VERSION ""

NS_ :

BS_:

BU_: ICC DVR EPC BBCM EAMP CMSM SBOX FLZCU_HCU_IC FLZCU_IC HCU_IC FLZCU_Signal_IC CGW TBOX BNCM CWC FRZCU

BO_ 1079 BSCU_1: 8 CGW
 SG_ BSCU_1_MotorLockSts : 17|2@0+ (1,0) [0|3] ""  ICC

BO_ 1127 CDU_DCDC_1: 24 CGW
 SG_ DCDC_FaultLevelSts : 107|3@0+ (1,0) [0|7] ""  ICC

BO_ 1035 VCC_1: 8 FLZCU_Signal_IC
 SG_ VCC_1_OTASts : 17|2@0+ (1,0) [0|3] ""  ICC

BO_ 1345 DVR_1: 16 DVR
 SG_ DVR_1_Sdcard_Sts : 26|3@0+ (1,0) [0|7] ""  ICC
 SG_ DVR_1_DVRFailReasons : 20|3@0+ (1,0) [0|7] ""  ICC
 SG_ DVR_1_RecordSts : 22|2@0+ (1,0) [0|3] ""  ICC

BO_ 1121 EAMP_1: 8 EAMP
 SG_ STAT_AMPNaviVolume : 3|4@0+ (1,0) [0|15] ""  ICC
 SG_ STAT_AMPVRVolume : 7|4@0+ (1,0) [0|15] ""  ICC
 SG_ STAT_AMPKeyTone : 9|2@0+ (1,0) [0|3] ""  ICC
 SG_ STAT_AMPMediaVolume : 15|6@0+ (1,0) [0|63] ""  ICC
 SG_ STAT_AMPPhoneVolume : 20|5@0+ (1,0) [0|31] ""  ICC
 SG_ STAT_AMPSoundFocus : 23|3@0+ (1,0) [0|7] ""  ICC
 SG_ STAT_AMPSoundEffect : 27|4@0+ (1,0) [0|15] ""  ICC
 SG_ STAT_AMPSoundEffectBass : 31|4@0+ (1,0) [0|15] ""  ICC
 SG_ STAT_AMPSoundEffectMidrange : 35|4@0+ (1,0) [0|15] ""  ICC
 SG_ STAT_AMPSoundEffectTreble : 39|4@0+ (1,0) [0|15] ""  ICC
 SG_ STAT_AMPSoundFieldBalance : 43|4@0+ (1,0) [0|15] ""  ICC
 SG_ STAT_AMPSoundFieldFader : 47|4@0+ (1,0) [0|15] ""  ICC
 SG_ STAT_REQ_AMPA2BMediaSound : 49|2@0+ (1,0) [0|3] ""  ICC
 SG_ STAT_REQ_AMPA2BNaviSound : 51|2@0+ (1,0) [0|3] ""  ICC
 SG_ STAT_REQ_AMPA2BVRSound : 53|2@0+ (1,0) [0|3] ""  ICC
 SG_ STAT_REQ_AMPA2BTTSSound : 55|2@0+ (1,0) [0|3] ""  ICC
 SG_ STAT_REQ_AMPA2BPhoneSound : 57|2@0+ (1,0) [0|3] ""  ICC
 SG_ STAT_REQ_AMPAlarm : 63|6@0+ (1,0) [0|63] ""  ICC

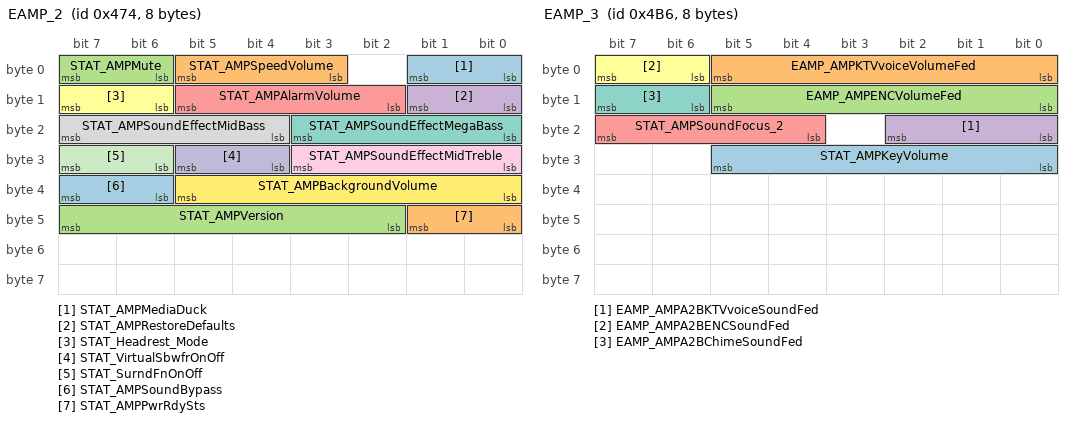
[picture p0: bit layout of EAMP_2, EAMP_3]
BO_ 1140 EAMP_2: 8 EAMP
 SG_ STAT_AMPMediaDuck : 1|2@0+ (1,0) [0|3] ""  ICC
 SG_ STAT_AMPSpeedVolume : 5|3@0+ (1,0) [0|7] ""  ICC
 SG_ STAT_AMPMute : 7|2@0+ (1,0) [0|3] ""  ICC
 SG_ STAT_AMPRestoreDefaults : 9|2@0+ (1,0) [0|3] ""  ICC
 SG_ STAT_AMPAlarmVolume : 13|4@0+ (1,0) [0|15] ""  ICC
 SG_ STAT_Headrest_Mode : 15|2@0+ (1,0) [0|3] ""  ICC
 SG_ STAT_AMPSoundEffectMegaBass : 19|4@0+ (1,0) [0|15] ""  ICC
 SG_ STAT_AMPSoundEffectMidBass : 23|4@0+ (1,0) [0|15] ""  ICC
 SG_ STAT_AMPSoundEffectMidTreble : 27|4@0+ (1,0) [0|15] ""  ICC
 SG_ STAT_VirtualSbwfrOnOff : 29|2@0+ (1,0) [0|3] ""  ICC
 SG_ STAT_SurndFnOnOff : 31|2@0+ (1,0) [0|3] ""  ICC
 SG_ STAT_AMPBackgroundVolume : 37|6@0+ (1,0) [0|63] ""  ICC
 SG_ STAT_AMPSoundBypass : 39|2@0+ (1,0) [0|3] ""  ICC
 SG_ STAT_AMPPwrRdySts : 41|2@0+ (1,0) [0|3] ""  ICC
 SG_ STAT_AMPVersion : 47|6@0+ (1,0) [0|63] ""  ICC

BO_ 1206 EAMP_3: 8 EAMP
 SG_ STAT_AMPKeyVolume : 29|6@0+ (1,0) [0|63] ""  ICC
 SG_ EAMP_AMPKTVvoiceVolumeFed : 5|6@0+ (1,0) [0|63] ""  ICC
 SG_ EAMP_AMPENCVolumeFed : 13|6@0+ (1,0) [0|63] ""  ICC
 SG_ EAMP_AMPA2BKTVvoiceSoundFed : 18|3@0+ (1,0) [0|7] ""  ICC
 SG_ STAT_AMPSoundFocus_2 : 23|4@0+ (1,0) [0|15] ""  ICC
 SG_ EAMP_AMPA2BENCSoundFed : 7|2@0+ (1,0) [0|3] ""  ICC
 SG_ EAMP_AMPA2BChimeSoundFed : 15|2@0+ (1,0) [0|3] ""  ICC

BO_ 1361 EPC_1: 64 EPC
 SG_ EPC_LeftPedalSystem_Sts : 27|4@0+ (1,0) [0|15] ""  ICC
 SG_ EPC_RightPedalSystem_Sts : 31|4@0+ (1,0) [0|15] ""  ICC
 SG_ EPC_LeftPedalTimeTravel : 39|8@0+ (1,0) [0|100] "%"  ICC
 SG_ EPC_RightPedalTimeTravel : 47|8@0+ (1,0) [0|100] "%"  ICC
 SG_ EPC_LeftPedalRealTime_Sts : 55|3@0+ (1,0) [0|7] ""  ICC
 SG_ EPC_LeftPedalBreakIce_Sts : 52|2@0+ (1,0) [0|3] ""  ICC
 SG_ EPC_RightPedalRealTime_Sts : 50|3@0+ (1,0) [0|7] ""  ICC
 SG_ EPC_RightPedalBreakIce_Sts : 63|2@0+ (1,0) [0|3] ""  ICC
 SG_ EPC_Enable_CmdStatus : 61|2@0+ (1,0) [0|3] ""  ICC
 SG_ EPC_LeftPedalCmdStatus : 59|2@0+ (1,0) [0|3] ""  ICC
 SG_ EPC_RightPedalCmdStatus : 57|2@0+ (1,0) [0|3] ""  ICC
 SG_ EPC_LeftPedal3D_Sts : 255|2@0+ (1,0) [0|3] ""  ICC
 SG_ EPC_RightPedal3D_Sts : 253|2@0+ (1,0) [0|3] ""  ICC

BO_ 1349 SBOX_MSD_1: 16 SBOX
 SG_ SBOX_MSD_Res : 3|4@0+ (1,0) [0|15] ""  ICC,TBOX
 SG_ SBOX_Ecallphonenub_Res : 7|4@0+ (1,0) [0|15] ""  ICC,TBOX

BO_ 1451 SBOX_STATE_2: 32 SBOX
 SG_ SBOX_GNSS_ANT_State : 1|2@0+ (1,0) [0|3] ""  ICC,TBOX
 SG_ SBOX_SIM_State : 3|2@0+ (1,0) [0|3] ""  ICC,TBOX
 SG_ SBOX_BT_State : 5|2@0+ (1,0) [0|3] ""  ICC,TBOX
 SG_ SBOX_TT_State : 7|2@0+ (1,0) [0|3] ""  ICC,TBOX
 SG_ SBOX_TT_ANT_State : 9|2@0+ (1,0) [0|3] ""  ICC,TBOX
 SG_ SBOX_BatterState : 11|2@0+ (1,0) [0|3] ""  ICC,TBOX
 SG_ SBOX_PowerState : 13|2@0+ (1,0) [0|3] ""  ICC,TBOX
 SG_ SBOX_SimActivation : 14|1@0+ (1,0) [0|1] ""  ICC,TBOX
 SG_ SBOX_TspActivation : 15|1@0+ (1,0) [0|1] ""  ICC,TBOX
 SG_ SBOX_SatelliteStatus : 19|4@0+ (1,0) [0|15] ""  ICC,TBOX
 SG_ SBOX_BtConState : 21|2@0+ (1,0) [0|3] ""  ICC,TBOX
 SG_ SBOX_SelfCheck : 23|2@0+ (1,0) [0|3] ""  ICC,TBOX
 SG_ SBOX_SatelliteSignalValue : 31|8@0+ (1,0) [0|255] ""  ICC,TBOX
 SG_ SBOX_BatTemp : 39|8@0+ (1,-40) [-40|100] "℃"  ICC,TBOX
 SG_ SBOX_TimeSpentOnline : 47|16@0+ (1,0) [0|65535] "sec"  ICC,TBOX
 SG_ SBOX_RunTime : 63|16@0+ (1,0) [0|65535] "min"  ICC,TBOX
 SG_ SBOX_EcallState : 79|2@0+ (1,0) [0|3] ""  ICC,TBOX

BO_ 1351 SBOX_CFG_3: 32 SBOX
 SG_ SBOX_SetMsgTotal : 15|16@0+ (1,0) [0|1000] ""  ICC
 SG_ SBOX_SetMSDTotal : 31|16@0+ (1,0) [0|1000] ""  ICC
 SG_ SBOX_SetCallTimeThreshold : 55|16@0+ (1,0) [0|65535] "min"  ICC
 SG_ SBOX_SetTodayCallTimeThreshold : 71|16@0+ (1,0) [0|65535] "min"  ICC
 SG_ SBOX_SetCurretnCallTime : 87|16@0+ (1,0) [0|65535] "min"  ICC
 SG_ SBOX_SetCurretnMsgThreshold : 103|16@0+ (1,0) [0|1000] ""  ICC
 SG_ SBOX_SetMsgTotalThreshold : 119|16@0+ (1,0) [0|1000] ""  ICC
 SG_ SBOX_SetMsdThreshold : 135|16@0+ (1,0) [0|1000] ""  ICC
 SG_ SBOX_SetCurrenMsdCnt : 151|16@0+ (1,0) [0|1000] ""  ICC
 SG_ SBOX_SetCustomMsgThreshold : 167|16@0+ (1,0) [0|1000] ""  ICC
 SG_ SBOX_SetCurrentCustomMsgCnt : 183|16@0+ (1,0) [0|1000] ""  ICC

BO_ 1353 SBOX_CFG_4: 16 SBOX
 SG_ SBOX_ICC_MACReq : 0|1@0+ (1,0) [0|1] ""  ICC
 SG_ SBOX_MAC_Req0 : 15|8@0+ (1,0) [0|255] ""  ICC
 SG_ SBOX_MAC_Req1 : 23|8@0+ (1,0) [0|255] ""  ICC
 SG_ SBOX_MAC_Req2 : 31|8@0+ (1,0) [0|255] ""  ICC
 SG_ SBOX_MAC_Req3 : 39|8@0+ (1,0) [0|255] ""  ICC
 SG_ SBOX_MAC_Req4 : 47|8@0+ (1,0) [0|255] ""  ICC
 SG_ SBOX_MAC_Req5 : 55|8@0+ (1,0) [0|255] ""  ICC

BO_ 1358 SBOX_CFG_5: 64 SBOX
 SG_ SBOX_ActiveTsp_Res : 0|1@0+ (1,0) [0|1] ""  ICC
 SG_ SBOX_ActiveSim_Res : 1|1@0+ (1,0) [0|1] ""  ICC
 SG_ SBOX_Mac_Res0 : 15|8@0+ (1,0) [0|255] ""  ICC
 SG_ SBOX_Mac_Res1 : 23|8@0+ (1,0) [0|255] ""  ICC
 SG_ SBOX_Mac_Res2 : 31|8@0+ (1,0) [0|255] ""  ICC
 SG_ SBOX_Mac_Res3 : 39|8@0+ (1,0) [0|255] ""  ICC
 SG_ SBOX_Mac_Res4 : 47|8@0+ (1,0) [0|255] ""  ICC
 SG_ SBOX_Mac_Res5 : 55|8@0+ (1,0) [0|255] ""  ICC
 SG_ SBOX_GetPlatformNumberRes : 2|1@0+ (1,0) [0|1] ""  ICC
 SG_ SBOX_ICCId_Res0 : 99|4@0+ (1,0) [0|9] ""  ICC
 SG_ SBOX_ICCId_Res1 : 103|4@0+ (1,0) [0|9] ""  ICC
 SG_ SBOX_ICCId_Res2 : 107|4@0+ (1,0) [0|9] ""  ICC
 SG_ SBOX_ICCId_Res3 : 111|4@0+ (1,0) [0|9] ""  ICC
 SG_ SBOX_ICCId_Res4 : 115|4@0+ (1,0) [0|9] ""  ICC
 SG_ SBOX_ICCId_Res5 : 119|4@0+ (1,0) [0|9] ""  ICC
 SG_ SBOX_ICCId_Res6 : 123|4@0+ (1,0) [0|9] ""  ICC
 SG_ SBOX_ICCId_Res7 : 127|4@0+ (1,0) [0|9] ""  ICC
 SG_ SBOX_ICCId_Res8 : 131|4@0+ (1,0) [0|9] ""  ICC
 SG_ SBOX_ICCId_Res9 : 135|4@0+ (1,0) [0|9] ""  ICC
 SG_ SBOX_ICCId_Res10 : 139|4@0+ (1,0) [0|9] ""  ICC
 SG_ SBOX_ICCId_Res11 : 143|4@0+ (1,0) [0|9] ""  ICC
 SG_ SBOX_ICCId_Res12 : 147|4@0+ (1,0) [0|9] ""  ICC
 SG_ SBOX_ICCId_Res13 : 151|4@0+ (1,0) [0|9] ""  ICC
 SG_ SBOX_ICCId_Res14 : 155|4@0+ (1,0) [0|9] ""  ICC
 SG_ SBOX_ICCId_Res15 : 159|4@0+ (1,0) [0|9] ""  ICC
 SG_ SBOX_ICCId_Res16 : 163|4@0+ (1,0) [0|9] ""  ICC
 SG_ SBOX_ICCId_Res17 : 167|4@0+ (1,0) [0|9] ""  ICC
 SG_ SBOX_ICCId_Res18 : 171|4@0+ (1,0) [0|9] ""  ICC
 SG_ SBOX_ICCId_Res19 : 175|4@0+ (1,0) [0|9] ""  ICC
 SG_ SBOX_Vin0 : 183|8@0+ (1,0) [0|90] ""  ICC
 SG_ SBOX_Vin1 : 191|8@0+ (1,0) [0|90] ""  ICC
 SG_ SBOX_Vin2 : 199|8@0+ (1,0) [0|90] ""  ICC
 SG_ SBOX_Vin3 : 207|8@0+ (1,0) [0|90] ""  ICC
 SG_ SBOX_Vin4 : 215|8@0+ (1,0) [0|90] ""  ICC
 SG_ SBOX_Vin5 : 223|8@0+ (1,0) [0|90] ""  ICC
 SG_ SBOX_Vin6 : 231|8@0+ (1,0) [0|90] ""  ICC
 SG_ SBOX_Vin7 : 239|8@0+ (1,0) [0|90] ""  ICC
 SG_ SBOX_Vin8 : 247|8@0+ (1,0) [0|90] ""  ICC
 SG_ SBOX_Vin9 : 255|8@0+ (1,0) [0|90] ""  ICC
 SG_ SBOX_Vin10 : 263|8@0+ (1,0) [0|90] ""  ICC
 SG_ SBOX_Vin11 : 271|8@0+ (1,0) [0|90] ""  ICC
 SG_ SBOX_Vin12 : 279|8@0+ (1,0) [0|90] ""  ICC
 SG_ SBOX_Vin13 : 287|8@0+ (1,0) [0|90] ""  ICC
 SG_ SBOX_Vin14 : 295|8@0+ (1,0) [0|90] ""  ICC
 SG_ SBOX_Vin15 : 303|8@0+ (1,0) [0|90] ""  ICC
 SG_ SBOX_Vin16 : 311|8@0+ (1,0) [0|90] ""  ICC

BO_ 1078 PLG_1: 8 BBCM
 SG_ PLG_LatchSts : 33|2@0+ (1,0) [0|3] ""  ICC,FLZCU_HCU_IC,FLZCU_IC,HCU_IC,TBOX,BNCM

BO_ 1310 BBCM_1: 32 BBCM
 SG_ BBCM_RLSeatMovFailCause3nd : 255|4@0+ (1,0) [0|15] ""  FRZCU,ICC
 SG_ BBCM_RRSeatMovFailCause3nd : 251|4@0+ (1,0) [0|15] ""  FRZCU,ICC
 SG_ BBCM_RLSeatMovFailCause2nd : 247|4@0+ (1,0) [0|15] ""  FRZCU,ICC
 SG_ BBCM_RRSeatMovFailCause2nd : 243|4@0+ (1,0) [0|15] ""  FRZCU,ICC
 SG_ BBCM_RRSeatExpSwSt2rd : 159|2@0+ (1,0) [0|3] ""  FRZCU,ICC
 SG_ BBCM_RRSeatExpSwCmd2rd : 145|2@0+ (1,0) [0|3] ""  ICC
 SG_ BBCM_RRSeatSwCmd3rd : 148|3@0+ (1,0) [0|7] ""  ICC
 SG_ BBCM_RLSeatSwCmd3rd : 151|3@0+ (1,0) [0|7] ""  ICC
 SG_ BBCM_RLSeatEasyEntryExitFb : 17|2@0+ (1,0) [0|3] ""  ICC
 SG_ BBCM_RRSeatEasyEntryExitFb : 19|2@0+ (1,0) [0|3] ""  ICC
 SG_ BBCM_RLSeatNeedMemory : 21|2@0+ (1,0) [0|3] ""  ICC
 SG_ BBCM_RLMemoryFb : 23|2@0+ (1,0) [0|3] ""  ICC
 SG_ BBCM_RLRecoverFb : 25|2@0+ (1,0) [0|3] ""  ICC
 SG_ BBCM_RRSeatNeedMemory : 27|2@0+ (1,0) [0|3] ""  ICC
 SG_ BBCM_RRMemoryFb : 29|2@0+ (1,0) [0|3] ""  ICC
 SG_ BBCM_RRRecoverFb : 31|2@0+ (1,0) [0|3] ""  ICC
 SG_ BBCM_RLSeatLvlFb2nd : 38|7@0+ (1,-1) [-1|100] "%"  ICC,FLZCU_HCU_IC,FLZCU_IC
 SG_ BBCM_RLSeatBackAgFb2nd : 46|7@0+ (1,-1) [-1|100] "%"  ICC,FLZCU_HCU_IC,FLZCU_IC
 SG_ BBCM_RLSeatLegSpprtFb2nd : 54|7@0+ (1,-1) [-1|100] "%"  ICC,FLZCU_HCU_IC,FLZCU_IC
 SG_ BBCM_RLSeatLegRestAngleFb2nd : 62|7@0+ (1,-1) [-1|100] "%"  ICC,FLZCU_HCU_IC,FLZCU_IC
 SG_ BBCM_RRSeatLvlFb2nd : 70|7@0+ (1,-1) [-1|100] "%"  ICC,FRZCU
 SG_ BBCM_RRSeatBackAgFb2nd : 78|7@0+ (1,-1) [-1|100] "%"  ICC,FRZCU
 SG_ BBCM_RRSeatLegSpprtFb2nd : 86|7@0+ (1,-1) [-1|100] "%"  ICC,FRZCU
 SG_ BBCM_RRSeatLegRestAngleFb2nd : 94|7@0+ (1,-1) [-1|100] "%"  ICC,FRZCU
 SG_ BBCM_RLSeatBackAgFb3rd : 102|7@0+ (1,-1) [-1|100] "%"  ICC
 SG_ BBCM_RRSeatBackAgFb3rd : 110|7@0+ (1,-1) [-1|100] "%"  ICC
 SG_ BBCM_RLSeatFrontFlipFb3rd : 118|7@0+ (1,-1) [-1|100] "%"  ICC
 SG_ BBCM_RRSeatFrontFlipFb3rd : 126|7@0+ (1,-1) [-1|100] "%"  ICC

BO_ 1201 CMSM_1: 16 CMSM
 SG_ CMSM_BLDCFaultSt : 87|3@0+ (1,0) [0|7] ""  ICC
 SG_ CMSM_DisplaySwitch : 23|2@0+ (1,0) [0|3] ""  ICC
 SG_ CMSM_DisplayAdjustrang : 31|8@0+ (1,0) [0|255] "°"  ICC
 SG_ CMSM_DisplayAdjustmode : 21|2@0+ (1,0) [0|3] ""  ICC
 SG_ CMSM_DisplayStandard : 84|2@0+ (1,0) [0|3] ""  ICC

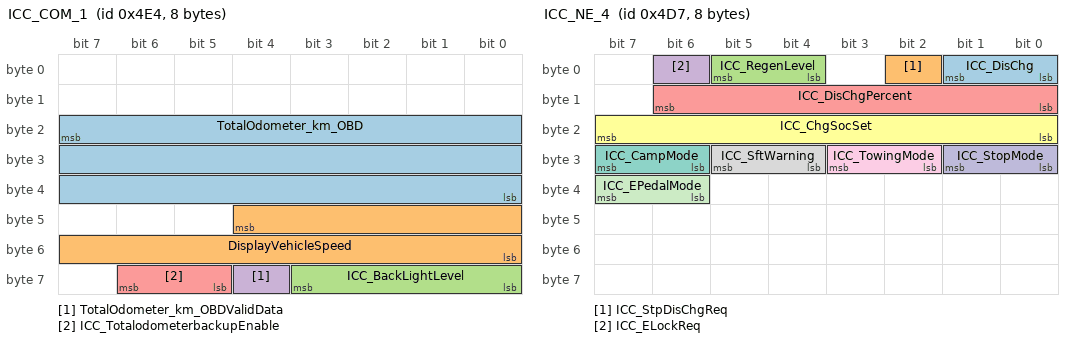
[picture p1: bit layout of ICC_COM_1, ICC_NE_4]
BO_ 1252 ICC_COM_1: 8 ICC
 SG_ TotalOdometer_km_OBD : 23|24@0+ (0.1,0) [0|999999.9] "km"  FLZCU_HCU_IC,FLZCU_IC,HCU_IC,TBOX,BNCM
 SG_ DisplayVehicleSpeed : 44|13@0+ (0.0625,0) [0|511.875] "km/h"  FLZCU_HCU_IC,FLZCU_IC,TBOX,BNCM
 SG_ ICC_BackLightLevel : 59|4@0+ (1,0) [0|15] ""  FLZCU_HCU_IC
 SG_ TotalOdometer_km_OBDValidData : 60|1@0+ (1,0) [0|1] ""  FLZCU_HCU_IC,FLZCU_IC,HCU_IC,TBOX,BNCM
 SG_ ICC_TotalodometerbackupEnable : 62|2@0+ (1,0) [0|3] ""  FLZCU_HCU_IC,FLZCU_IC

BO_ 1322 ICC_IC_2: 8 ICC
 SG_ STAT_AMPAlarm : 7|6@0+ (1,0) [0|63] ""  EAMP

BO_ 1176 ICC_CH_3: 8 ICC
 SG_ Fusa_498_6 : 51|2@0+ (1,0) [0|3] ""  CGW
 SG_ Fusa_498_5 : 45|4@0+ (1,0) [0|15] ""  CGW
 SG_ Fusa_498_4 : 34|3@0+ (1,0) [0|7] ""  CGW
 SG_ Fusa_498_3 : 39|3@0+ (1,0) [0|7] ""  CGW
 SG_ Fusa_498_2 : 31|4@0+ (1,0) [0|15] ""  CGW
 SG_ Fusa_498_1 : 15|2@0+ (1,0) [0|3] ""  CGW
 SG_ ICC_CH_3_CRC : 7|8@0+ (1,0) [0|255] ""  FLZCU_HCU_IC,FLZCU_Signal_IC,CGW
 SG_ ICC_CH_3_RollgCntr : 11|4@0+ (1,0) [0|14] ""  FLZCU_HCU_IC,FLZCU_Signal_IC,CGW
 SG_ ICC_ASUAssistPassSet : 13|2@0+ (1,0) [0|3] ""  FLZCU_HCU_IC,FLZCU_Signal_IC,CGW
 SG_ IHU_AutHldSet : 17|2@0+ (1,0) [0|3] ""  FLZCU_HCU_IC,FLZCU_Signal_IC,CGW
 SG_ ICC_AutoEasyEntrySet : 19|2@0+ (1,0) [0|3] ""  FLZCU_HCU_IC,FLZCU_Signal_IC,CGW
 SG_ ICC_ManualEasyOutSw : 21|2@0+ (1,0) [0|3] ""  FLZCU_HCU_IC,FLZCU_Signal_IC,CGW
 SG_ ICC_ASCMaintainModeReq : 23|2@0+ (1,0) [0|3] ""  FLZCU_HCU_IC,FLZCU_Signal_IC,CGW
 SG_ ICC_PABSetCmd : 25|2@0+ (1,0) [0|3] ""  FLZCU_HCU_IC,FLZCU_Signal_IC,CGW
 SG_ ICC_EPBSetCmd : 27|2@0+ (1,0) [0|3] ""  FLZCU_HCU_IC,FLZCU_Signal_IC,CGW
 SG_ ICC_ASUMemoryPosition : 36|2@0+ (1,0) [0|3] ""  FLZCU_HCU_IC,FLZCU_Signal_IC,CGW
 SG_ ICC_ASUEasyLoadingSet : 41|2@0+ (1,0) [0|3] ""  FLZCU_HCU_IC,FLZCU_Signal_IC,CGW
 SG_ Set_CSTFunctionSts : 47|2@0+ (1,0) [0|3] ""  FLZCU_HCU_IC,FLZCU_Signal_IC,CGW
 SG_ ICC_ASURearaxlewithTaildoor : 49|2@0+ (1,0) [0|3] ""  FLZCU_HCU_IC,FLZCU_Signal_IC,CGW
 SG_ CST_SensitivityReq : 53|2@0+ (1,0) [0|3] ""  FLZCU_HCU_IC,FLZCU_Signal_IC,CGW
 SG_ TIHU_SetHDCOnOff : 55|2@0+ (1,0) [0|3] ""  FLZCU_HCU_IC,FLZCU_Signal_IC,CGW
 SG_ Set_ESPFunctionSts : 57|2@0+ (1,0) [0|3] ""  FLZCU_HCU_IC,FLZCU_Signal_IC,CGW
 SG_ ICC_ASUPreviewCont : 59|2@0+ (1,0) [0|3] ""  FLZCU_HCU_IC,FLZCU_Signal_IC,CGW
 SG_ ICC_ASUHighwayModAdjust : 61|2@0+ (1,0) [0|3] ""  FLZCU_HCU_IC,FLZCU_Signal_IC,CGW
 SG_ ICC_ASUMapAdjust : 63|2@0+ (1,0) [0|3] ""  FLZCU_HCU_IC,FLZCU_Signal_IC,CGW

BO_ 1239 ICC_NE_4: 8 ICC
 SG_ ICC_DisChg : 1|2@0+ (1,0) [0|3] ""  FLZCU_HCU_IC,HCU_IC
 SG_ ICC_StpDisChgReq : 2|1@0+ (1,0) [0|1] "" Vector__XXX
 SG_ ICC_RegenLevel : 5|2@0+ (1,0) [0|3] "" Vector__XXX
 SG_ ICC_ELockReq : 6|1@0+ (1,0) [0|1] "" Vector__XXX
 SG_ ICC_DisChgPercent : 14|7@0+ (1,0) [1|100] "%"  FLZCU_HCU_IC,HCU_IC
 SG_ ICC_ChgSocSet : 23|8@0+ (1,0) [1|100] "%"  FLZCU_HCU_IC,HCU_IC
 SG_ ICC_CampMode : 31|2@0+ (1,0) [0|3] ""  FLZCU_HCU_IC,HCU_IC
 SG_ ICC_SftWarning : 29|2@0+ (1,0) [0|3] "" Vector__XXX
 SG_ ICC_TowingMode : 27|2@0+ (1,0) [0|3] ""  FLZCU_HCU_IC,HCU_IC
 SG_ ICC_StopMode : 25|2@0+ (1,0) [0|3] "" Vector__XXX
 SG_ ICC_EPedalMode : 39|2@0+ (1,0) [0|3] "" Vector__XXX

BO_ 1246 ICC_TMS_5: 32 ICC
 SG_ ICC_WindowKeySts : 1|2@0+ (1,0) [0|3] "" Vector__XXX
 SG_ ICC_FaceKeySts : 3|2@0+ (1,0) [0|3] "" Vector__XXX
 SG_ ICC_FootKeySts : 5|2@0+ (1,0) [0|3] "" Vector__XXX
 SG_ BltCallSts : 7|2@0+ (1,0) [0|3] "" Vector__XXX
 SG_ ICC_DockWinspSts : 9|2@0+ (1,0) [0|3] "" Vector__XXX
 SG_ ICC_DockTSts : 11|2@0+ (1,0) [0|3] "" Vector__XXX
 SG_ ICC_ACFastCool : 13|2@0+ (1,0) [0|3] "" Vector__XXX
 SG_ ICC_ACFastHeat : 15|2@0+ (1,0) [0|3] "" Vector__XXX
 SG_ ICC_SetCLMOn : 17|2@0+ (1,0) [0|3] "" Vector__XXX
 SG_ ICC_SetAutoKeySts : 19|2@0+ (1,0) [0|3] "" Vector__XXX
 SG_ ICC_SetFrontDeforestSts : 21|2@0+ (1,0) [0|3] "" Vector__XXX
 SG_ ICC_SetCirculationModeKeySts : 23|2@0+ (1,0) [0|3] "" Vector__XXX
 SG_ ICC_ZoneSelectionKeySts : 25|2@0+ (1,0) [0|3] "" Vector__XXX
 SG_ ICC_ResetFilter : 27|2@0+ (1,0) [0|3] "" Vector__XXX
 SG_ ICC_AUTODefrostOnKeySts : 29|2@0+ (1,0) [0|3] "" Vector__XXX
 SG_ ICC_AutoAirClean : 33|2@0+ (1,0) [0|3] "" Vector__XXX
 SG_ ICC_KeepWarm : 35|2@0+ (1,0) [0|3] ""  FLZCU_HCU_IC,HCU_IC
 SG_ ICC_BlowSpeedLevelKeySts : 39|4@0+ (1,0) [0|15] "" Vector__XXX
 SG_ ICC_SetACRequestKeySts : 42|3@0+ (1,0) [0|7] "" Vector__XXX
 SG_ ICC_DSwingSet : 45|3@0+ (1,0) [0|7] "" Vector__XXX
 SG_ ICC_PSwingSet : 50|3@0+ (1,0) [0|7] "" Vector__XXX
 SG_ ICC_AUTODefLevelSet : 58|3@0+ (1,0) [0|7] "" Vector__XXX
 SG_ ICC_SetTemperature_L_C : 55|5@0+ (0.5,15.5) [15.5|30.5] "℃" Vector__XXX
 SG_ ICC_SetTemperature_R_C : 63|5@0+ (0.5,15.5) [15.5|30.5] "℃" Vector__XXX
 SG_ ICC_DLSwingUpDwn : 70|7@0+ (1,0) [0|100] "%" Vector__XXX
 SG_ ICC_DLSwingLeRi : 78|7@0+ (1,0) [0|100] "%" Vector__XXX
 SG_ ICC_DRSwingUpDwn : 86|7@0+ (1,0) [0|100] "%" Vector__XXX
 SG_ ICC_DRSwingLeRi : 94|7@0+ (1,0) [0|100] "%" Vector__XXX
 SG_ ICC_PLSwingUpDwn : 102|7@0+ (1,0) [0|100] "%" Vector__XXX
 SG_ ICC_PLSwingLeRi : 110|7@0+ (1,0) [0|100] "%" Vector__XXX
 SG_ ICC_PRSwingUpDwn : 118|7@0+ (1,0) [0|100] "%" Vector__XXX
 SG_ ICC_PRSwingLeRi : 126|7@0+ (1,0) [0|100] "%" Vector__XXX
 SG_ ICC_DCSwingLeRi : 134|7@0+ (1,0) [0|100] "%" Vector__XXX
 SG_ ICC_NetWorkTemperature : 143|8@0+ (0.5,-40) [-40|85] "°C" Vector__XXX
 SG_ ICC_NetWorkHumidity : 151|8@0+ (0.5,-0.5) [0|100] "%" Vector__XXX
 SG_ ICC_DLOnOff : 201|2@0+ (1,0) [0|3] "" Vector__XXX
 SG_ ICC_DROnOff : 203|2@0+ (1,0) [0|3] "" Vector__XXX
 SG_ ICC_PLOnOff : 205|2@0+ (1,0) [0|3] "" Vector__XXX
 SG_ ICC_PROnOff : 207|2@0+ (1,0) [0|3] "" Vector__XXX
 SG_ ICC_DCOnOff : 209|2@0+ (1,0) [0|3] "" Vector__XXX
 SG_ ICC_LoveRemind : 211|2@0+ (1,0) [0|3] "" Vector__XXX
 SG_ ICC_InteCleanCar : 213|2@0+ (1,0) [0|3] "" Vector__XXX
 SG_ ICC_KeepWarmMemory : 223|2@0+ (1,0) [0|3] "" Vector__XXX

BO_ 1250 ICC_ZCU_6: 8 ICC
 SG_ ICC_CCMReq_4E2h : 52|3@0+ (1,0) [0|7] ""  FLZCU_HCU_IC,HCU_IC
 SG_ ICC_CCMSet : 49|2@0+ (1,0) [0|3] ""  FLZCU_HCU_IC,HCU_IC
 SG_ ICC_AutoLightSW : 10|1@0+ (1,0) [0|1] ""  FLZCU_HCU_IC,CGW
 SG_ ICC_CleanMode : 13|2@0+ (1,0) [0|3] ""  FLZCU_HCU_IC,FLZCU_IC,CGW
 SG_ ICC_1_OTASts : 17|2@0+ (1,0) [0|3] ""  FLZCU_HCU_IC,FLZCU_IC,HCU_IC,FLZCU_Signal_IC,CGW
 SG_ ICC_1_OTAHV_Req : 19|2@0+ (1,0) [0|3] ""  FLZCU_HCU_IC,FLZCU_IC,HCU_IC,CGW
 SG_ ICC_1_OTAPwrMngt : 22|3@0+ (1,0) [0|7] ""  FLZCU_HCU_IC,FLZCU_IC,CGW
 SG_ ICC_DriveModeSwitch : 31|3@0+ (1,0) [0|7] ""  FLZCU_HCU_IC,CGW
 SG_ ICC_PropulsionMode : 28|3@0+ (1,0) [0|7] ""  FLZCU_HCU_IC,CGW
 SG_ ICC_SteeringMode : 25|2@0+ (1,0) [0|3] ""  FLZCU_HCU_IC,HCU_IC,CGW
 SG_ ICC_SuspensionHeight : 39|3@0+ (1,0) [0|7] ""  FLZCU_HCU_IC,HCU_IC,CGW
 SG_ ICC_SuspensionDamping : 36|2@0+ (1,0) [0|3] ""  FLZCU_HCU_IC,HCU_IC,CGW
 SG_ ICC_AirconditionMode : 34|2@0+ (1,0) [0|3] ""  FLZCU_HCU_IC,CGW
 SG_ ICC_BrakePedalFeelMode : 47|2@0+ (1,0) [0|3] ""  FLZCU_HCU_IC,CGW
 SG_ ICC_SentinelHV_Req : 45|2@0+ (1,0) [0|3] ""  FLZCU_HCU_IC,HCU_IC,CGW
 SG_ ICC_PetModeHV_Req : 43|2@0+ (1,0) [0|3] ""  FLZCU_HCU_IC,HCU_IC,CGW
 SG_ ICC_SelfClearing : 41|2@0+ (1,0) [0|3] ""  FLZCU_HCU_IC,HCU_IC,CGW

BO_ 1254 ICC_DK_7: 64 ICC
 SG_ ICC_WelcomeOpenSet : 1|2@0+ (1,0) [0|3] ""  FLZCU_HCU_IC,FLZCU_IC,BNCM
 SG_ ICC_WALOpenSet : 3|2@0+ (1,0) [0|3] ""  FLZCU_HCU_IC,FLZCU_IC,BNCM
 SG_ ICC_EasytrunkSet : 5|2@0+ (1,0) [0|3] ""  BNCM
 SG_ ICC_UIROpenSet : 7|2@0+ (1,0) [0|3] ""  FLZCU_HCU_IC,FLZCU_IC,BNCM
 SG_ ICC_BeanIDReq : 13|2@0+ (1,0) [0|3] ""  BNCM
 SG_ ICC_CWCWorkingStsSet : 15|2@0+ (1,0) [0|3] ""  CWC
 SG_ ICC_CWCPhoneforgottenFunStsSet : 17|2@0+ (1,0) [0|3] ""  CWC
 SG_ ICC_RCWCWorkingStsSet : 25|2@0+ (1,0) [0|3] "" Vector__XXX
 SG_ ICC_RCWCPhoneforgottenFunStsSet : 27|2@0+ (1,0) [0|3] "" Vector__XXX

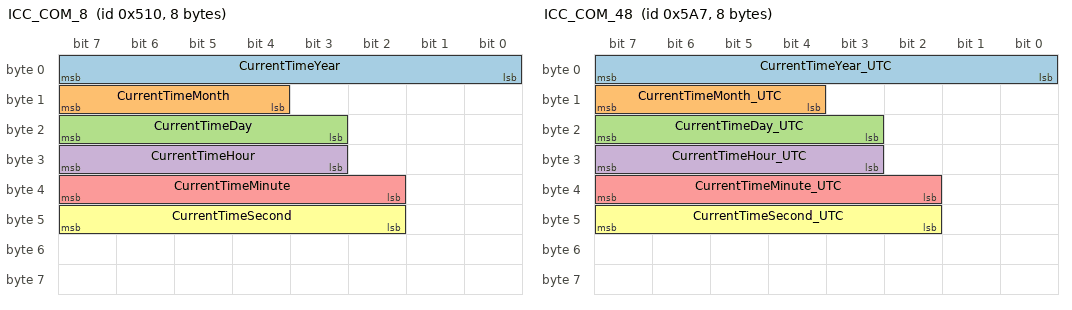
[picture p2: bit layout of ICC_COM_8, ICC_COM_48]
BO_ 1296 ICC_COM_8: 8 ICC
 SG_ CurrentTimeYear : 7|8@0+ (1,2000) [2000|2255] ""  DVR,EPC,FLZCU_HCU_IC,HCU_IC,BNCM
 SG_ CurrentTimeMonth : 15|4@0+ (1,0) [1|12] ""  DVR,EPC,FLZCU_HCU_IC,HCU_IC,BNCM
 SG_ CurrentTimeDay : 23|5@0+ (1,0) [1|31] ""  DVR,EPC,FLZCU_HCU_IC,HCU_IC,BNCM
 SG_ CurrentTimeHour : 31|5@0+ (1,0) [0|23] ""  DVR,EPC,FLZCU_HCU_IC,HCU_IC,BNCM
 SG_ CurrentTimeMinute : 39|6@0+ (1,0) [0|59] ""  DVR,EPC,FLZCU_HCU_IC,HCU_IC,BNCM
 SG_ CurrentTimeSecond : 47|6@0+ (1,0) [0|59] ""  DVR,EPC,FLZCU_HCU_IC,HCU_IC,BNCM

BO_ 1447 ICC_COM_48: 8 ICC
 SG_ CurrentTimeYear_UTC : 7|8@0+ (1,2000) [2000|2255] ""  FLZCU_HCU_IC,FLZCU_IC
 SG_ CurrentTimeMonth_UTC : 15|4@0+ (1,0) [1|12] ""  FLZCU_HCU_IC,FLZCU_IC
 SG_ CurrentTimeDay_UTC : 23|5@0+ (1,0) [1|31] ""  FLZCU_HCU_IC,FLZCU_IC
 SG_ CurrentTimeHour_UTC : 31|5@0+ (1,0) [0|23] ""  FLZCU_HCU_IC,FLZCU_IC
 SG_ CurrentTimeMinute_UTC : 39|6@0+ (1,0) [0|59] ""  FLZCU_HCU_IC,FLZCU_IC
 SG_ CurrentTimeSecond_UTC : 47|6@0+ (1,0) [0|59] ""  FLZCU_HCU_IC,FLZCU_IC

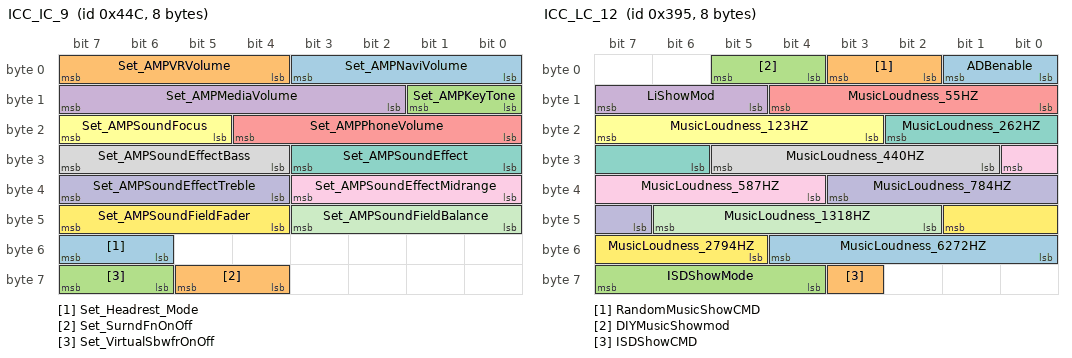
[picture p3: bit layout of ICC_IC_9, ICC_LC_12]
BO_ 1100 ICC_IC_9: 8 ICC
 SG_ Set_AMPNaviVolume : 3|4@0+ (1,0) [0|15] ""  EAMP
 SG_ Set_AMPVRVolume : 7|4@0+ (1,0) [0|15] ""  EAMP
 SG_ Set_AMPKeyTone : 9|2@0+ (1,0) [0|3] ""  EAMP
 SG_ Set_AMPMediaVolume : 15|6@0+ (1,0) [0|63] ""  EAMP
 SG_ Set_AMPPhoneVolume : 20|5@0+ (1,0) [0|31] ""  EAMP
 SG_ Set_AMPSoundFocus : 23|3@0+ (1,0) [0|7] ""  EAMP
 SG_ Set_AMPSoundEffect : 27|4@0+ (1,0) [0|15] ""  EAMP
 SG_ Set_AMPSoundEffectBass : 31|4@0+ (1,0) [0|15] ""  EAMP
 SG_ Set_AMPSoundEffectMidrange : 35|4@0+ (1,0) [0|15] ""  EAMP
 SG_ Set_AMPSoundEffectTreble : 39|4@0+ (1,0) [0|15] ""  EAMP
 SG_ Set_AMPSoundFieldBalance : 43|4@0+ (1,0) [0|15] ""  EAMP
 SG_ Set_AMPSoundFieldFader : 47|4@0+ (1,0) [0|15] ""  EAMP
 SG_ Set_Headrest_Mode : 55|2@0+ (1,0) [0|3] ""  EAMP
 SG_ Set_SurndFnOnOff : 61|2@0+ (1,0) [0|3] ""  EAMP
 SG_ Set_VirtualSbwfrOnOff : 63|2@0+ (1,0) [0|3] ""  EAMP

BO_ 1119 ICC_IC_10: 8 ICC
 SG_ Set_AMPMediaDuck : 1|2@0+ (1,0) [0|3] ""  EAMP
 SG_ Set_AMPSpeedVolume : 5|3@0+ (1,0) [0|7] ""  EAMP
 SG_ Set_AMPMute : 7|2@0+ (1,0) [0|3] ""  EAMP
 SG_ REQ_AMPA2BMediaSound : 9|2@0+ (1,0) [0|3] ""  EAMP
 SG_ REQ_AMPA2BNaviSound : 11|2@0+ (1,0) [0|3] ""  EAMP
 SG_ REQ_AMPA2BVRSound : 13|2@0+ (1,0) [0|3] ""  EAMP
 SG_ REQ_AMPA2BTTSSound : 15|2@0+ (1,0) [0|3] ""  EAMP
 SG_ REQ_AMPA2BKeyTone : 23|2@0+ (1,0) [0|3] ""  EAMP
 SG_ Set_AMPRestoreDefaults : 25|2@0+ (1,0) [0|3] ""  EAMP
 SG_ Set_AMPAlarmVolume : 29|4@0+ (1,0) [0|15] ""  EAMP
 SG_ REQ_AMPA2BPhoneSound : 31|2@0+ (1,0) [0|3] ""  EAMP
 SG_ Set_AMPSoundEffectMegaBass : 35|4@0+ (1,0) [0|15] ""  EAMP
 SG_ Set_AMPSoundEffectMidBass : 39|4@0+ (1,0) [0|15] ""  EAMP
 SG_ Set_AMPSoundEffectMidTreble : 43|4@0+ (1,0) [0|15] ""  EAMP
 SG_ Set_AMPBackgroundVolume : 53|6@0+ (1,0) [0|63] ""  EAMP
 SG_ Set_AMPSoundBypass : 45|2@0+ (1,0) [0|3] ""  EAMP
 SG_ Set_AMPA2BConfig : 47|2@0+ (1,0) [0|3] ""  EAMP

BO_ 1150 ICC_BD_11: 8 ICC
 SG_ Fusa_47E_3 : 28|1@0+ (1,0) [0|1] ""  CGW
 SG_ Fusa_47E_2 : 23|4@0+ (1,0) [0|15] ""  CGW
 SG_ Fusa_47E_1 : 15|2@0+ (1,0) [0|3] ""  CGW
 SG_ ICC_BD_11_CRC : 7|8@0+ (1,0) [0|255] "" Vector__XXX
 SG_ ICC_BD_11_RollgCntr : 11|4@0+ (1,0) [0|14] "" Vector__XXX
 SG_ ICC_CPDDelaySwitchSet : 13|2@0+ (1,0) [0|3] "" Vector__XXX
 SG_ ICC_PPMIDBSRBPASet : 17|2@0+ (1,0) [0|3] "" Vector__XXX
 SG_ ICC_PPMIDHwSet : 19|2@0+ (1,0) [0|3] "" Vector__XXX
 SG_ ICC_DriveDrosinessLevel : 31|3@0+ (1,0) [0|7] "" Vector__XXX
 SG_ ICC_FLDoorButton : 25|2@0+ (1,0) [0|3] "" Vector__XXX
 SG_ ICC_FRDoorButton : 27|2@0+ (1,0) [0|3] "" Vector__XXX
 SG_ ICC_RRDoorButton : 33|2@0+ (1,0) [0|3] "" Vector__XXX
 SG_ ICC_RLDoorButton : 35|2@0+ (1,0) [0|3] "" Vector__XXX
 SG_ ICC_CloseAllDoors : 37|2@0+ (1,0) [0|3] "" Vector__XXX
 SG_ ICC_DoorRemoteKeyControlEnable : 39|2@0+ (1,0) [0|3] ""  FLZCU_HCU_IC
 SG_ ICC_SetOpenAngle : 41|2@0+ (1,0) [0|3] "" Vector__XXX
 SG_ ICC_CPDSwitchSet : 43|2@0+ (1,0) [0|3] "" Vector__XXX
 SG_ ICC_FrontDoorPowerMode : 45|2@0+ (1,0) [0|3] "" Vector__XXX
 SG_ ICC_RearDoorPowerMode : 47|2@0+ (1,0) [0|3] "" Vector__XXX
 SG_ ICC_PedalCloseDriverDoorEnable : 49|2@0+ (1,0) [0|3] "" Vector__XXX
 SG_ RR_Door_RearScreen_Control : 51|2@0+ (1,0) [0|3] "" Vector__XXX
 SG_ ICC_RearDoorVoiceControlEnable : 53|2@0+ (1,0) [0|3] "" Vector__XXX
 SG_ ICC_FLVoiceControl : 55|2@0+ (1,0) [0|3] "" Vector__XXX
 SG_ ICC_FRVoiceControl : 57|2@0+ (1,0) [0|3] "" Vector__XXX
 SG_ ICC_RRVoiceControl : 59|2@0+ (1,0) [0|3] "" Vector__XXX
 SG_ ICC_RLVoiceControl : 61|2@0+ (1,0) [0|3] "" Vector__XXX
 SG_ RL_Door_RearScreen_Control : 63|2@0+ (1,0) [0|3] "" Vector__XXX

BO_ 917 ICC_LC_12: 8 ICC
 SG_ ADBenable : 1|2@0+ (1,0) [0|3] "" Vector__XXX
 SG_ RandomMusicShowCMD : 3|2@0+ (1,0) [0|3] "" Vector__XXX
 SG_ DIYMusicShowmod : 5|2@0+ (1,0) [0|3] "" Vector__XXX
 SG_ LiShowMod : 15|3@0+ (1,0) [0|7] "" Vector__XXX
 SG_ MusicLoudness_55HZ : 12|5@0+ (1,0) [0|31] "" Vector__XXX
 SG_ MusicLoudness_123HZ : 23|5@0+ (1,0) [0|31] "" Vector__XXX
 SG_ MusicLoudness_262HZ : 18|5@0+ (1,0) [0|31] "" Vector__XXX
 SG_ MusicLoudness_440HZ : 29|5@0+ (1,0) [0|31] "" Vector__XXX
 SG_ MusicLoudness_587HZ : 24|5@0+ (1,0) [0|31] "" Vector__XXX
 SG_ MusicLoudness_784HZ : 35|5@0+ (1,0) [0|31] "" Vector__XXX
 SG_ MusicLoudness_1318HZ : 46|5@0+ (1,0) [0|31] "" Vector__XXX
 SG_ MusicLoudness_2794HZ : 41|5@0+ (1,0) [0|31] "" Vector__XXX
 SG_ MusicLoudness_6272HZ : 52|5@0+ (1,0) [0|31] "" Vector__XXX
 SG_ ISDShowCMD : 59|1@0+ (1,0) [0|1] "" Vector__XXX
 SG_ ISDShowMode : 63|4@0+ (1,0) [0|15] "" Vector__XXX

BO_ 1273 ICC_IC_14: 8 ICC
 SG_ FaceID : 29|3@0+ (1,0) [0|7] ""  FLZCU_HCU_IC,FLZCU_IC

BO_ 1157 ICC_DA_15: 8 ICC
 SG_ Fusa_485_2 : 55|16@0+ (1,0) [0|65535] "" Vector__XXX
 SG_ Fusa_485_1 : 31|3@0+ (1,0) [0|7] "" Vector__XXX
 SG_ ICC_DA_15_CRC : 7|8@0+ (1,0) [0|255] "" Vector__XXX
 SG_ ICC_DA_15_RollgCntr : 11|4@0+ (1,0) [0|14] "" Vector__XXX
 SG_ ICC_DA_15_Resd : 15|4@0+ (1,0) [0|15] "" Vector__XXX
 SG_ ICC_DA_15_BSDLCWSettingSt : 17|2@0+ (1,0) [0|3] "" Vector__XXX
 SG_ ICC_DA_15_DOWSettingSt : 19|2@0+ (1,0) [0|3] "" Vector__XXX
 SG_ ICC_DA_15_RCWSettingSt : 21|2@0+ (1,0) [0|3] "" Vector__XXX
 SG_ ICC_DA_15_RCTARCTBWarnType : 23|2@0+ (1,0) [0|3] "" Vector__XXX
 SG_ ICC_DA_15_FCTAFCTBWarnType : 25|2@0+ (1,0) [0|3] "" Vector__XXX
 SG_ ICC_DA_15_FrontPDCMuteSet : 26|1@0+ (1,0) [0|1] "" Vector__XXX
 SG_ ICC_DA_15_FKPMuteSet : 27|1@0+ (1,0) [0|1] "" Vector__XXX
 SG_ ICC_DA_15_ExtremeEnergySaveMode : 28|1@0+ (1,0) [0|1] "" Vector__XXX
 SG_ Driver_EyeOnRoad : 39|3@0+ (1,0) [0|7] "" Vector__XXX
 SG_ Dms_Status : 36|3@0+ (1,0) [0|7] "" Vector__XXX
 SG_ Driver_AbnormalBehavior : 33|2@0+ (1,0) [0|3] "" Vector__XXX
 SG_ Driver_GazeRegion : 47|4@0+ (1,0) [0|15] "" Vector__XXX
 SG_ Dms_DriverPresence : 43|2@0+ (1,0) [0|3] "" Vector__XXX
 SG_ ICC_IHCfunctionSw : 41|2@0+ (1,0) [0|3] "" Vector__XXX

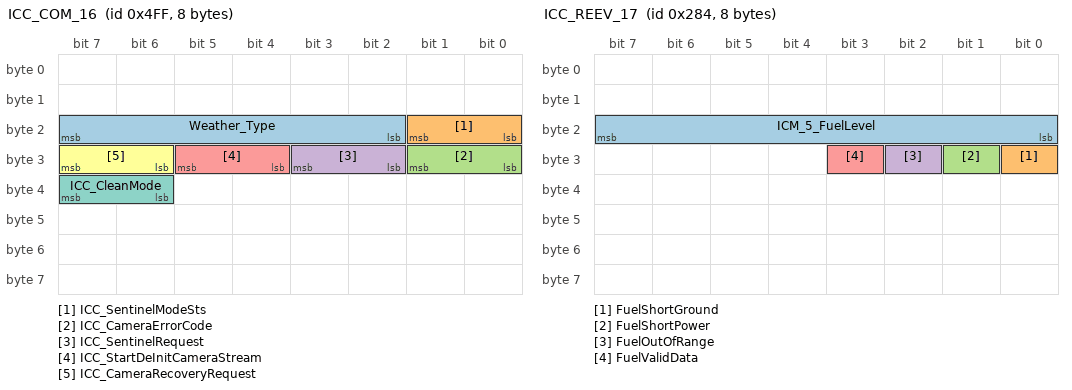
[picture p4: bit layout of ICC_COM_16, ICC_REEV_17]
BO_ 1279 ICC_COM_16: 8 ICC
 SG_ Weather_Type : 23|6@0+ (1,0) [0|63] "" Vector__XXX
 SG_ ICC_SentinelModeSts : 17|2@0+ (1,0) [0|3] "" Vector__XXX
 SG_ ICC_CameraErrorCode : 25|2@0+ (1,0) [0|3] "" Vector__XXX
 SG_ ICC_SentinelRequest : 27|2@0+ (1,0) [0|3] "" Vector__XXX
 SG_ ICC_StartDeInitCameraStream : 29|2@0+ (1,0) [0|3] "" Vector__XXX
 SG_ ICC_CameraRecoveryRequest : 31|2@0+ (1,0) [0|3] "" Vector__XXX
 SG_ ICC_CleanMode : 39|2@0+ (1,0) [0|3] "" Vector__XXX

BO_ 644 ICC_REEV_17: 8 ICC
 SG_ ICM_5_FuelLevel : 23|8@0+ (1,0) [0|100] "%"  FLZCU_HCU_IC,HCU_IC,TBOX
 SG_ FuelShortGround : 24|1@0+ (1,0) [0|1] ""  FLZCU_HCU_IC
 SG_ FuelShortPower : 25|1@0+ (1,0) [0|1] ""  FLZCU_HCU_IC
 SG_ FuelOutOfRange : 26|1@0+ (1,0) [0|1] ""  FLZCU_HCU_IC
 SG_ FuelValidData : 27|1@0+ (1,0) [0|1] ""  FLZCU_HCU_IC

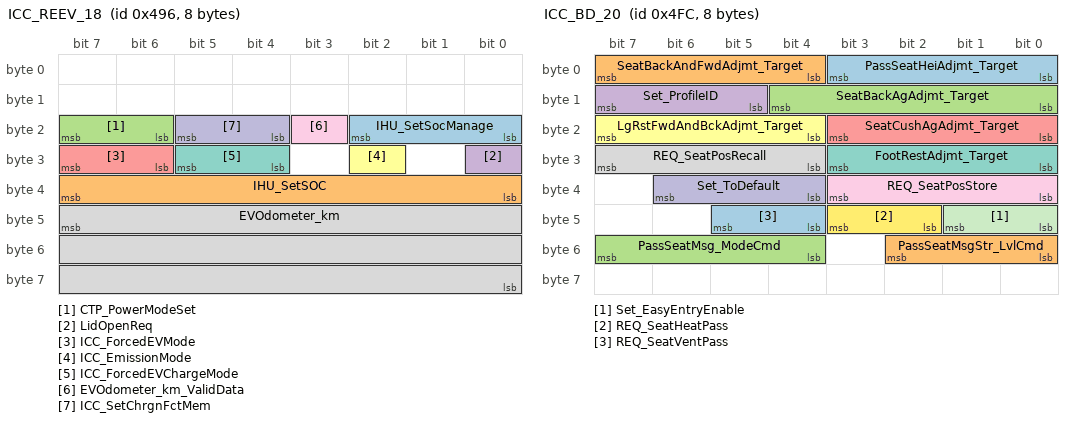
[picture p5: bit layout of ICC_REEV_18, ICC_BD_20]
BO_ 1174 ICC_REEV_18: 8 ICC
 SG_ IHU_SetSocManage : 18|3@0+ (1,0) [0|7] ""  FLZCU_HCU_IC
 SG_ IHU_SetSOC : 39|8@0+ (1,0) [0|100] "%"  FLZCU_HCU_IC,HCU_IC
 SG_ CTP_PowerModeSet : 23|2@0+ (1,0) [0|3] ""  FLZCU_HCU_IC,HCU_IC
 SG_ LidOpenReq : 24|1@0+ (1,0) [0|1] "" Vector__XXX
 SG_ ICC_ForcedEVMode : 31|2@0+ (1,0) [0|3] ""  FLZCU_HCU_IC
 SG_ ICC_EmissionMode : 26|1@0+ (1,0) [0|1] ""  FLZCU_HCU_IC,HCU_IC
 SG_ ICC_ForcedEVChargeMode : 29|2@0+ (1,0) [0|3] ""  FLZCU_HCU_IC
 SG_ EVOdometer_km : 47|24@0+ (0.1,0) [0|999999.9] "km"  FLZCU_HCU_IC
 SG_ EVOdometer_km_ValidData : 19|1@0+ (1,0) [0|1] ""  FLZCU_HCU_IC
 SG_ ICC_SetChrgnFctMem : 21|2@0+ (1,0) [0|3] ""  FLZCU_HCU_IC,HCU_IC

BO_ 1242 ICC_DK_19: 32 ICC
 SG_ ICC_DK_19_CRC1 : 7|8@0+ (1,0) [0|255] ""  BNCM
 SG_ ICC_DK_19_RollgCntr1 : 11|4@0+ (1,0) [0|14] ""  BNCM
 SG_ ICC_DK_19_Resd1 : 15|4@0+ (1,0) [0|15] ""  BNCM
 SG_ ICC_DK_19_CMD : 23|16@0+ (1,0) [0|65535] ""  BNCM
 SG_ ICC_DK_19_PDU1 : 39|64@0+ (1,0) [0|1.84467440737096E+019] ""  BNCM
 SG_ ICC_DK_19_PDU2 : 103|64@0+ (1,0) [0|1.84467440737096E+019] ""  BNCM
 SG_ ICC_DK_19_PDU3 : 167|64@0+ (1,0) [0|1.84467440737096E+019] ""  BNCM
 SG_ ICC_DK_19_PDU4 : 231|32@0+ (1,0) [0|4294967295] ""  BNCM

BO_ 1276 ICC_BD_20: 8 ICC
 SG_ PassSeatHeiAdjmt_Target : 3|4@0+ (1,0) [0|15] "" Vector__XXX
 SG_ SeatBackAndFwdAdjmt_Target : 7|4@0+ (1,0) [0|15] "" Vector__XXX
 SG_ SeatBackAgAdjmt_Target : 12|5@0+ (1,0) [0|31] "" Vector__XXX
 SG_ Set_ProfileID : 15|3@0+ (1,0) [0|7] "" Vector__XXX
 SG_ SeatCushAgAdjmt_Target : 19|4@0+ (1,0) [0|15] "" Vector__XXX
 SG_ LgRstFwdAndBckAdjmt_Target : 23|4@0+ (1,0) [0|15] "" Vector__XXX
 SG_ FootRestAdjmt_Target : 27|4@0+ (1,0) [0|15] "" Vector__XXX
 SG_ REQ_SeatPosRecall : 31|4@0+ (1,0) [0|15] "" Vector__XXX
 SG_ REQ_SeatPosStore : 35|4@0+ (1,0) [0|15] "" Vector__XXX
 SG_ Set_ToDefault : 38|3@0+ (1,0) [0|7] "" Vector__XXX
 SG_ Set_EasyEntryEnable : 41|2@0+ (1,0) [0|3] "" Vector__XXX
 SG_ REQ_SeatHeatPass : 43|2@0+ (1,0) [0|3] "" Vector__XXX
 SG_ REQ_SeatVentPass : 45|2@0+ (1,0) [0|3] "" Vector__XXX
 SG_ PassSeatMsgStr_LvlCmd : 50|3@0+ (1,0) [0|7] "" Vector__XXX
 SG_ PassSeatMsg_ModeCmd : 55|4@0+ (1,0) [0|15] "" Vector__XXX

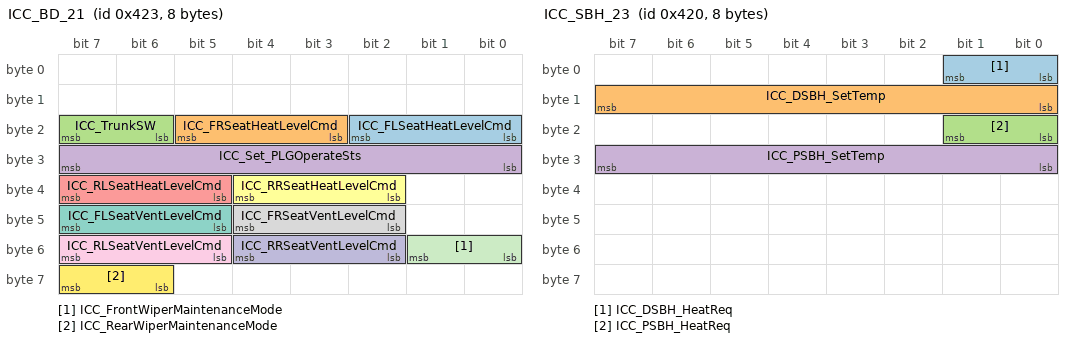
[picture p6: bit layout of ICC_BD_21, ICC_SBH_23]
BO_ 1059 ICC_BD_21: 8 ICC
 SG_ ICC_FLSeatHeatLevelCmd : 18|3@0+ (1,0) [0|7] ""  FLZCU_HCU_IC,FLZCU_IC
 SG_ ICC_FRSeatHeatLevelCmd : 21|3@0+ (1,0) [0|7] ""  FRZCU
 SG_ ICC_TrunkSW : 23|2@0+ (1,0) [0|3] "" Vector__XXX
 SG_ ICC_Set_PLGOperateSts : 31|8@0+ (1,-1) [-1|100] "%" Vector__XXX
 SG_ ICC_RLSeatHeatLevelCmd : 39|3@0+ (1,0) [0|7] ""  FLZCU_HCU_IC,FLZCU_IC
 SG_ ICC_RRSeatHeatLevelCmd : 36|3@0+ (1,0) [0|7] ""  FRZCU
 SG_ ICC_FLSeatVentLevelCmd : 47|3@0+ (1,0) [0|7] ""  FLZCU_HCU_IC,FLZCU_IC
 SG_ ICC_FRSeatVentLevelCmd : 44|3@0+ (1,0) [0|7] ""  FRZCU
 SG_ ICC_RLSeatVentLevelCmd : 55|3@0+ (1,0) [0|7] ""  FLZCU_HCU_IC,FLZCU_IC
 SG_ ICC_RRSeatVentLevelCmd : 52|3@0+ (1,0) [0|7] ""  FRZCU
 SG_ ICC_FrontWiperMaintenanceMode : 49|2@0+ (1,0) [0|3] ""  FLZCU_HCU_IC,FLZCU_IC
 SG_ ICC_RearWiperMaintenanceMode : 63|2@0+ (1,0) [0|3] ""  FLZCU_HCU_IC,FLZCU_IC

BO_ 1105 ICC_MFS_22: 8 ICC
 SG_ ICC_MultiplexSignalStatusSet : 12|3@0+ (1,0) [0|7] "" Vector__XXX

BO_ 1056 ICC_SBH_23: 8 ICC
 SG_ ICC_DSBH_HeatReq : 1|2@0+ (1,0) [0|3] "" Vector__XXX
 SG_ ICC_DSBH_SetTemp : 15|8@0+ (1,0) [30|65] "°C" Vector__XXX
 SG_ ICC_PSBH_HeatReq : 17|2@0+ (1,0) [0|3] "" Vector__XXX
 SG_ ICC_PSBH_SetTemp : 31|8@0+ (1,0) [30|65] "°C" Vector__XXX

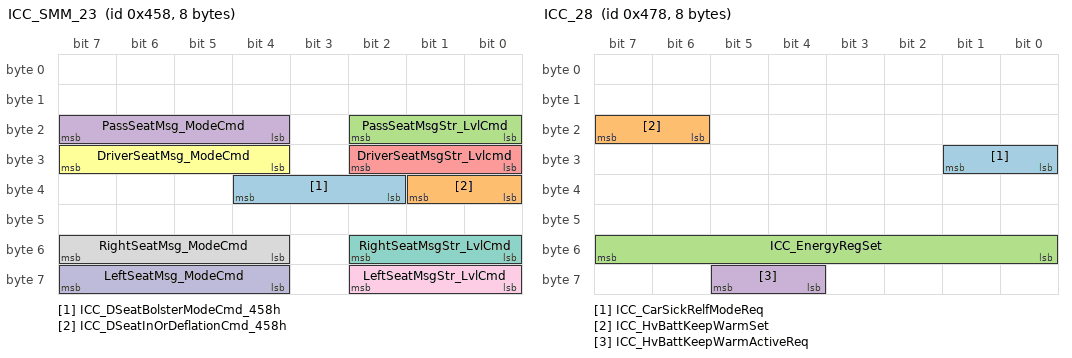
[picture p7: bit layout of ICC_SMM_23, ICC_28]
BO_ 1112 ICC_SMM_23: 8 ICC
 SG_ ICC_DSeatBolsterModeCmd_458h : 36|3@0+ (1,0) [0|7] ""  FLZCU_HCU_IC,FLZCU_IC
 SG_ ICC_DSeatInOrDeflationCmd_458h : 33|2@0+ (1,0) [0|3] ""  FLZCU_HCU_IC,FLZCU_IC
 SG_ PassSeatMsgStr_LvlCmd : 18|3@0+ (1,0) [0|7] ""  FLZCU_HCU_IC,FLZCU_IC
 SG_ PassSeatMsg_ModeCmd : 23|4@0+ (1,0) [0|15] ""  FLZCU_HCU_IC,FLZCU_IC
 SG_ DriverSeatMsgStr_Lvlcmd : 26|3@0+ (1,0) [0|7] ""  FLZCU_HCU_IC,FLZCU_IC
 SG_ DriverSeatMsg_ModeCmd : 31|4@0+ (1,0) [0|15] ""  FLZCU_HCU_IC,FLZCU_IC
 SG_ RightSeatMsgStr_LvlCmd : 50|3@0+ (1,0) [0|7] ""  FLZCU_HCU_IC,FLZCU_IC
 SG_ RightSeatMsg_ModeCmd : 55|4@0+ (1,0) [0|15] ""  FLZCU_HCU_IC,FLZCU_IC
 SG_ LeftSeatMsgStr_LvlCmd : 58|3@0+ (1,0) [0|7] ""  FLZCU_HCU_IC,FLZCU_IC
 SG_ LeftSeatMsg_ModeCmd : 63|4@0+ (1,0) [0|15] ""  FLZCU_HCU_IC,FLZCU_IC

BO_ 1265 ICC_ZCU_25: 24 ICC
 SG_ ICC_PwrOff : 18|1@0+ (1,0) [0|1] ""  FLZCU_HCU_IC
 SG_ ICC_EtmEgySave : 20|1@0+ (1,0) [0|1] ""  FLZCU_HCU_IC
 SG_ ICC_HoodSW : 23|2@0+ (1,0) [0|3] ""  FLZCU_HCU_IC
 SG_ ICC_GloveboxSW : 25|2@0+ (1,0) [0|3] ""  FLZCU_HCU_IC
 SG_ ICC_ChrgPortCover_Switch : 27|2@0+ (1,0) [0|3] ""  FLZCU_HCU_IC
 SG_ ICC_ReWinDefrstSwt : 29|2@0+ (1,0) [0|3] ""  FLZCU_HCU_IC,FLZCU_IC
 SG_ ICC_RearMirrorFoldCmd : 31|2@0+ (1,0) [0|3] ""  FLZCU_HCU_IC,FLZCU_IC
 SG_ ICC_CenterLockSwt : 33|2@0+ (1,0) [0|3] ""  FLZCU_HCU_IC,FLZCU_IC
 SG_ ICC_ReverseExtMirrorSts : 36|3@0+ (1,0) [0|7] ""  FLZCU_HCU_IC,FLZCU_IC
 SG_ ICC_LightMainSwitchSts : 39|3@0+ (1,0) [0|7] ""  FLZCU_HCU_IC
 SG_ ICC_AutoFoldSts : 41|2@0+ (1,0) [0|3] ""  FLZCU_HCU_IC,FLZCU_IC
 SG_ ICC_HeadlampHeightSts : 44|3@0+ (1,0) [0|7] ""  FLZCU_HCU_IC,FLZCU_IC
 SG_ ICC_WiprSnvty : 47|3@0+ (1,0) [0|7] ""  FLZCU_HCU_IC,FLZCU_IC
 SG_ ICC_WindowCmd : 52|5@0+ (1,0) [0|31] ""  FLZCU_HCU_IC,FLZCU_IC
 SG_ ICC_LowBeamDelayOff : 55|3@0+ (1,0) [0|7] ""  FLZCU_HCU_IC,FLZCU_IC
 SG_ ICC_FLWinCmd : 62|7@0+ (1,-1) [-1|100] "%"  FLZCU_HCU_IC,FLZCU_IC
 SG_ ICC_FRWinCmd : 86|7@0+ (1,-1) [-1|100] "%"  FLZCU_HCU_IC,FLZCU_IC
 SG_ ICC_RLWinCmd : 94|7@0+ (1,-1) [-1|100] "%"  FLZCU_HCU_IC,FLZCU_IC
 SG_ ICC_RRWinCmd : 102|7@0+ (1,-1) [-1|100] "%"  FLZCU_HCU_IC,FLZCU_IC
 SG_ ICC_FGHeatSts : 105|2@0+ (1,0) [0|3] ""  FLZCU_HCU_IC,FLZCU_IC
 SG_ ICC_AutolockSts : 107|2@0+ (1,0) [0|3] ""  FLZCU_HCU_IC,FLZCU_IC
 SG_ ICC_WiperID : 109|2@0+ (1,0) [0|3] ""  FLZCU_HCU_IC
 SG_ ICC_MaintenanceMode : 111|2@0+ (1,0) [0|3] ""  FLZCU_HCU_IC
 SG_ ICC_lockSetSwitchSts : 113|2@0+ (1,0) [0|3] ""  FLZCU_HCU_IC
 SG_ ICC_ChildLockSW : 115|2@0+ (1,0) [0|3] ""  FLZCU_HCU_IC
 SG_ ICC_ParkUnlockEnable : 117|2@0+ (1,0) [0|3] ""  FLZCU_HCU_IC,FLZCU_IC
 SG_ ICC_BLEOpenDriverDoorEnable : 119|2@0+ (1,0) [0|3] ""  FLZCU_HCU_IC,FLZCU_IC
 SG_ ICC_WinInhbSwt : 121|2@0+ (1,0) [0|3] ""  FLZCU_HCU_IC
 SG_ ICC_SteerWhlHeatgSwt : 124|3@0+ (1,0) [0|7] ""  FLZCU_HCU_IC,FLZCU_IC
 SG_ ICC_AutoHeatingset : 127|2@0+ (1,0) [0|3] ""  FLZCU_HCU_IC
 SG_ ICC_FrontFogSw : 145|2@0+ (1,0) [0|3] ""  FLZCU_HCU_IC
 SG_ ICC_RearFogSw : 147|2@0+ (1,0) [0|3] ""  FLZCU_HCU_IC
 SG_ ICC_DoorControlSW : 149|2@0+ (1,0) [0|3] ""  FLZCU_HCU_IC
 SG_ ICC_LockCarWinCloseSw : 151|2@0+ (1,0) [0|3] ""  FLZCU_HCU_IC,FLZCU_IC
 SG_ ICC_RainCarWinCloseSw : 159|2@0+ (1,0) [0|3] ""  FLZCU_HCU_IC
 SG_ ICC_EasyEntryExitSet : 157|2@0+ (1,0) [0|3] ""  FLZCU_HCU_IC,FLZCU_IC
 SG_ ICC_NapTimeSet : 166|6@0+ (1,-1) [-1|60] "min"  FLZCU_HCU_IC,FLZCU_IC
 SG_ ICC_NapAreaSet : 155|2@0+ (1,0) [0|3] ""  FLZCU_HCU_IC,FLZCU_IC
 SG_ ICC_NapStatusSet : 153|2@0+ (1,0) [0|3] ""  FLZCU_HCU_IC,FLZCU_IC
 SG_ ICC_NapCFSStatusSet : 175|2@0+ (1,0) [0|3] ""  FLZCU_HCU_IC,FRZCU
 SG_ ICC_NapSetTemperature : 173|5@0+ (0.5,15.5) [15.5|30.5] "℃"  FLZCU_HCU_IC,FRZCU
 SG_ ICC_SpoilerWelcomeFunSet : 183|2@0+ (1,0) [0|3] ""  FLZCU_HCU_IC
 SG_ ICC_SpoilerCtrlCmd : 181|3@0+ (1,0) [0|7] ""  FLZCU_HCU_IC
 SG_ ICC_HazardLightReq : 177|2@0+ (1,0) [0|3] ""  FLZCU_HCU_IC
 SG_ ICC_MusicStatus : 187|2@0+ (1,0) [0|3] ""  FLZCU_HCU_IC,FLZCU_IC
 SG_ ICC_CinemaStatus : 185|2@0+ (1,0) [0|3] ""  BBCM,FLZCU_HCU_IC,FLZCU_IC,HCU_IC

BO_ 1137 ICC_TBOX_27: 32 ICC
 SG_ ICC_ElectronicFenceStsFed_471h : 233|2@0+ (1,0) [0|3] ""  TBOX
 SG_ ICC_BookChrgSetReq : 23|2@0+ (1,0) [0|3] ""  FLZCU_HCU_IC,HCU_IC,TBOX
 SG_ ICC_BkChrgStartTimeYear : 31|16@0+ (1,1900) [1900|9999] "年"  FLZCU_HCU_IC,HCU_IC,TBOX
 SG_ ICC_BkChrgStartTimeDay : 47|5@0+ (1,0) [1|31] "日"  FLZCU_HCU_IC,HCU_IC,TBOX
 SG_ ICC_BkChrgStartTimeHour : 55|5@0+ (1,0) [0|23] "小时"  FLZCU_HCU_IC,HCU_IC,TBOX
 SG_ ICC_BkChrgStartTimemMin : 63|6@0+ (1,0) [0|59] "分钟"  FLZCU_HCU_IC,HCU_IC,TBOX
 SG_ ICC_BkChrgStartTimeMonth : 87|4@0+ (1,0) [1|12] "月"  FLZCU_HCU_IC,HCU_IC,TBOX
 SG_ ICC_BkChrgDuration : 83|11@0+ (1,0) [0|1440] "min"  FLZCU_HCU_IC,HCU_IC,TBOX
 SG_ ICC_BkChrgCycleType : 103|3@0+ (1,0) [0|7] ""  FLZCU_HCU_IC,HCU_IC,TBOX
 SG_ ICC_StopChrgReq : 100|2@0+ (1,0) [0|3] ""  FLZCU_HCU_IC,HCU_IC,TBOX
 SG_ ICC_BkChrgCycleMon : 98|2@0+ (1,0) [0|3] ""  FLZCU_HCU_IC,HCU_IC,TBOX
 SG_ ICC_BkChrgCycleTues : 111|2@0+ (1,0) [0|3] ""  FLZCU_HCU_IC,HCU_IC,TBOX
 SG_ ICC_BkChrgCycleWen : 109|2@0+ (1,0) [0|3] ""  FLZCU_HCU_IC,HCU_IC,TBOX
 SG_ ICC_BkChrgCycleThur : 107|2@0+ (1,0) [0|3] ""  FLZCU_HCU_IC,HCU_IC,TBOX
 SG_ ICC_BkChrgCycleFri : 105|2@0+ (1,0) [0|3] ""  FLZCU_HCU_IC,HCU_IC,TBOX
 SG_ ICC_BkChrgCycleSat : 119|2@0+ (1,0) [0|3] ""  FLZCU_HCU_IC,HCU_IC,TBOX
 SG_ ICC_BkChrgCycleSun : 117|2@0+ (1,0) [0|3] ""  FLZCU_HCU_IC,HCU_IC,TBOX
 SG_ ICC_KeepWarmStrt : 124|5@0+ (1,0) [1|31] "日"  FLZCU_HCU_IC,HCU_IC,TBOX
 SG_ ICC_KeepWarmStrtHour : 148|5@0+ (1,0) [0|23] "小时"  FLZCU_HCU_IC,HCU_IC,TBOX
 SG_ ICC_KeepWarmStrtMin : 157|6@0+ (1,0) [0|59] "分钟"  FLZCU_HCU_IC,HCU_IC,TBOX
 SG_ ICC_PetmodeFb : 159|2@0+ (1,0) [0|3] ""  FLZCU_HCU_IC,HCU_IC,TBOX
 SG_ ICC_SentinelModeSwitchSts : 167|2@0+ (1,0) [0|3] ""  FLZCU_HCU_IC,HCU_IC,TBOX
 SG_ ICC_SentinelModeWorkingSts : 165|3@0+ (1,0) [0|7] ""  FLZCU_HCU_IC,HCU_IC,TBOX
 SG_ ICC_SentinelModeFaultSts : 161|2@0+ (1,0) [0|3] ""  FLZCU_HCU_IC,HCU_IC,TBOX
 SG_ ICC_SentinelModeAlarmSts : 175|2@0+ (1,0) [0|3] ""  FLZCU_HCU_IC,HCU_IC,TBOX
 SG_ ICC_SentinelModeExitReason : 173|3@0+ (1,0) [0|7] ""  FLZCU_HCU_IC,HCU_IC,TBOX
 SG_ ICC_PetModeWarn : 170|3@0+ (1,0) [0|7] ""  FLZCU_HCU_IC
 SG_ ICC_TBOXPetmodeReq : 178|2@0+ (1,0) [0|3] ""  FLZCU_HCU_IC,TBOX
 SG_ ICC_PetModeWarn_2 : 183|5@0+ (1,0) [0|31] ""  FLZCU_HCU_IC,HCU_IC,TBOX
 SG_ ICM_FuelLevel : 215|8@0+ (1,0) [0|255] "L"  FLZCU_HCU_IC,HCU_IC,TBOX,BNCM
 SG_ ICM_AverageVehicleSpeed : 223|8@0+ (1,0) [0|255] "Km/h"  FLZCU_HCU_IC,HCU_IC,TBOX
 SG_ ICM_DistenceToEmpty_Km : 231|11@0+ (1,0) [0|2047] "km"  FLZCU_HCU_IC,HCU_IC,TBOX
 SG_ ICM_FuelLevelFailSts : 235|1@0+ (1,0) [0|1] ""  FLZCU_HCU_IC,HCU_IC,TBOX
 SG_ ICM_Maintenance_tips : 234|1@0+ (1,0) [0|1] ""  FLZCU_HCU_IC,HCU_IC,TBOX
 SG_ ICM_SumTrip : 247|14@0+ (1,0) [0|16383] "km"  FLZCU_HCU_IC,HCU_IC,TBOX

BO_ 1144 ICC_28: 8 ICC
 SG_ ICC_CarSickRelfModeReq : 25|2@0+ (1,0) [0|3] ""  FLZCU_HCU_IC,HCU_IC
 SG_ ICC_HvBattKeepWarmSet : 23|2@0+ (1,0) [0|3] ""  FLZCU_HCU_IC,HCU_IC,TBOX
 SG_ ICC_EnergyRegSet : 55|8@0+ (1,-1) [-1|100] "%"  FLZCU_HCU_IC
 SG_ ICC_HvBattKeepWarmActiveReq : 61|2@0+ (1,0) [0|3] ""  FLZCU_HCU_IC,HCU_IC,TBOX

BO_ 1210 ICC_ZCU_29: 32 ICC
 SG_ ICC_1_IDverify : 247|2@0+ (1,0) [0|3] ""  FLZCU_HCU_IC,FLZCU_IC
 SG_ ICC_FLSeatHeiCmd : 23|2@0+ (1,0) [0|3] ""  FLZCU_HCU_IC
 SG_ ICC_FLSeatLvlCmd : 21|2@0+ (1,0) [0|3] ""  FLZCU_HCU_IC
 SG_ ICC_FLSeatBackAgCmd : 19|2@0+ (1,0) [0|3] ""  FLZCU_HCU_IC
 SG_ ICC_FLSeatCushCmd : 17|2@0+ (1,0) [0|3] ""  FLZCU_HCU_IC
 SG_ ICC_FLSeatLegSpprtCmd : 31|2@0+ (1,0) [0|3] ""  FLZCU_HCU_IC
 SG_ ICC_FRSeatHeiCmd : 29|2@0+ (1,0) [0|3] ""  FLZCU_HCU_IC
 SG_ ICC_FRSeatLvlCmd : 27|2@0+ (1,0) [0|3] ""  FLZCU_HCU_IC
 SG_ ICC_FRSeatBackAgCmd : 25|2@0+ (1,0) [0|3] ""  FLZCU_HCU_IC
 SG_ ICC_FRSeatLegSpprtCmd : 39|2@0+ (1,0) [0|3] ""  FLZCU_HCU_IC
 SG_ ICC_MemoryRecoveryCmd : 37|2@0+ (1,0) [0|3] ""  FLZCU_HCU_IC,FLZCU_IC
 SG_ ICC_DeleteFaceID : 35|3@0+ (1,0) [0|7] ""  FLZCU_HCU_IC,FLZCU_IC
 SG_ ICC_FLSeatHeitargetCmd : 47|7@0+ (1,-1) [-1|100] "%"  FLZCU_HCU_IC
 SG_ ICC_FLSeatLvltargetCmd : 55|7@0+ (1,-1) [-1|100] "%"  FLZCU_HCU_IC
 SG_ ICC_FLSeatBackAgtargetCmd : 63|7@0+ (1,-1) [-1|100] "%"  FLZCU_HCU_IC
 SG_ ICC_FLSeatCushtargetCmd : 87|7@0+ (1,-1) [-1|100] "%"  FLZCU_HCU_IC
 SG_ ICC_FLSeatLegSpprttargetCmd : 95|7@0+ (1,-1) [-1|100] "%"  FLZCU_HCU_IC
 SG_ ICC_FRSeatHeitargetCmd : 103|7@0+ (1,-1) [-1|100] "%"  FLZCU_HCU_IC
 SG_ ICC_FRSeatLvltargetCmd : 111|7@0+ (1,-1) [-1|100] "%"  FLZCU_HCU_IC
 SG_ ICC_FRSeatBackAgtargetCmd : 119|7@0+ (1,-1) [-1|100] "%"  FLZCU_HCU_IC
 SG_ ICC_FRSeatLegSpprttargetCmd : 127|7@0+ (1,-1) [-1|100] "%"  FLZCU_HCU_IC
 SG_ ICC_NapFLSeatBackAgtargetSet : 151|7@0+ (1,-1) [-1|100] "%"  FLZCU_HCU_IC,FLZCU_IC
 SG_ ICC_NapFRSeatBackAgtargetSet : 159|7@0+ (1,-1) [-1|100] "%"  FLZCU_HCU_IC,FLZCU_IC
 SG_ ICC_NapFLSeatLvltargetSet : 167|7@0+ (1,-1) [-1|100] "%"  FLZCU_HCU_IC,FLZCU_IC
 SG_ ICC_NapFRSeatLvltargetSet : 175|7@0+ (1,-1) [-1|100] "%"  FLZCU_HCU_IC,FLZCU_IC
 SG_ ICC_FRSeatLegRestAngleCmd : 183|2@0+ (1,0) [0|3] ""  FLZCU_HCU_IC
 SG_ ICC_FRSeatLegRestAngletargetCmd : 190|7@0+ (1,-1) [-1|100] "%"  FLZCU_HCU_IC
 SG_ ICC_FRSeatCushCmd : 181|2@0+ (1,0) [0|3] ""  FLZCU_HCU_IC
 SG_ ICC_FRSeatCushtargetCmd : 214|7@0+ (1,-1) [-1|100] "%"  FLZCU_HCU_IC
 SG_ ICC_FRZeroGravitySeatSw : 179|2@0+ (1,0) [0|3] ""  FLZCU_HCU_IC
 SG_ ICC_HomeLinkArmHornSet : 223|2@0+ (1,0) [0|3] ""  FLZCU_HCU_IC
 SG_ ICC_HomeLinkWelLightSet : 221|2@0+ (1,0) [0|3] ""  FLZCU_HCU_IC
 SG_ ICC_HomeLinkPositionSts : 219|2@0+ (1,0) [0|3] ""  FLZCU_HCU_IC
 SG_ ICC_WelcomeOpenSetCmd : 217|2@0+ (1,0) [0|3] ""  FLZCU_HCU_IC,FLZCU_IC
 SG_ ICC_WALOpenSetCmd : 231|2@0+ (1,0) [0|3] ""  FLZCU_HCU_IC,FLZCU_IC
 SG_ ICC_UIROpenSetCmd : 229|2@0+ (1,0) [0|3] ""  FLZCU_HCU_IC,FLZCU_IC
 SG_ ICC_EnjoyableSeatSwitch : 227|2@0+ (1,0) [0|3] ""  FLZCU_HCU_IC,FLZCU_IC
 SG_ ICC_BLTKeyPESet : 225|2@0+ (1,0) [0|3] ""  FLZCU_HCU_IC,FLZCU_IC
 SG_ ICC_FRMemoryDeleteCmd : 241|2@0+ (1,0) [0|3] ""  FLZCU_HCU_IC
 SG_ ICC_FLSitPosnlocation : 233|2@0+ (1,0) [0|3] ""  FLZCU_HCU_IC,FLZCU_IC
 SG_ ICC_FRSitPosnlocation : 235|2@0+ (1,0) [0|3] ""  FLZCU_HCU_IC
 SG_ ICC_FREasyEntryExitSet : 237|2@0+ (1,0) [0|3] ""  FLZCU_HCU_IC
 SG_ ICC_FRMemoryRecoveryCmd : 239|2@0+ (1,0) [0|3] ""  FLZCU_HCU_IC
 SG_ ICC_ConsoleAdjustSwitch : 245|4@0+ (1,0) [0|15] ""  FLZCU_HCU_IC

BO_TX_BU_ 1035 : FLZCU_HCU_IC,FLZCU_IC,FLZCU_Signal_IC;

CM_ SG_ 1345 DVR_1_DVRFailReasons "DVR失效原因";
CM_ SG_ 1345 DVR_1_RecordSts "DVR普通录像状态";
CM_ SG_ 1121 STAT_AMPNaviVolume "Amplifier navigation volume status
反馈-导航音量设定";
CM_ SG_ 1121 STAT_AMPVRVolume "Amplifier voice recognize volume status
反馈语音音量设定";
CM_ SG_ 1121 STAT_AMPKeyTone "Amplifier key tone status
反馈按键音开关";
CM_ SG_ 1121 STAT_AMPMediaVolume "Amplifier media volume status
反馈媒体音量设定";
CM_ SG_ 1121 STAT_AMPPhoneVolume "Amplifier phone volume status
反馈电话音量设定";
CM_ SG_ 1121 STAT_AMPSoundFocus "Amplifier sound focus status
反馈音场（最佳听音位）设定";
CM_ SG_ 1121 STAT_AMPSoundEffect "Amplifier sound effect status
反馈-音效设定（预设EQ）";
CM_ SG_ 1121 STAT_AMPSoundEffectBass "Amplifier sound effect bass status
反馈-低音设定（用户自定义EQ下）";
CM_ SG_ 1121 STAT_AMPSoundEffectMidrange "Amplifier sound effect midrange status
反馈-中音设定（用户自定义EQ下）";
CM_ SG_ 1121 STAT_AMPSoundEffectTreble "Amplifier sound effect treble status
反馈-高音设定（用户自定义EQ下）";
CM_ SG_ 1121 STAT_AMPSoundFieldBalance "Amplifier sound field balance status
反馈-Balance设定（用户自定义声场)";
CM_ SG_ 1121 STAT_AMPSoundFieldFader "Amplifier sound field fader status
反馈-反馈-Fader设定（用户自定义声场）";
CM_ SG_ 1121 STAT_REQ_AMPA2BMediaSound "Status of Head unit media sound request to amplifier
媒体音源需求状态";
CM_ SG_ 1121 STAT_REQ_AMPA2BNaviSound "Status of Head unit navigation sound request to amplifier
导航音源需求状态";
CM_ SG_ 1121 STAT_REQ_AMPA2BVRSound "Status of Head unit VR sound request to amplifier
VR/Siri音源需求状态";
CM_ SG_ 1121 STAT_REQ_AMPA2BTTSSound "Status of Head unit TTS sound request to amplifier
TTS音源需求状态";
CM_ SG_ 1121 STAT_REQ_AMPA2BPhoneSound "Status of Head unit BT Phone and Tbox sound request to amplifier
电话/Tbox音源需求状态";
CM_ SG_ 1121 STAT_REQ_AMPAlarm "Status of Instrument panel cluster alarm status to amplifier for chime play
警报音需求状态";
CM_ SG_ 1140 STAT_AMPMediaDuck "Media Duck request to amplifier/发送媒体降音反馈给主机";
CM_ SG_ 1140 STAT_AMPSpeedVolume "Amplifier vehicle speed volume compensation status
反馈-随速补偿等级设定";
CM_ SG_ 1140 STAT_AMPMute "Amplifier audio mute or not status
反馈-媒体音量开关";
CM_ SG_ 1140 STAT_AMPRestoreDefaults "Amplifier audio restore defaults status/恢复默认音频参数设置状态";
CM_ SG_ 1140 STAT_AMPAlarmVolume "Amplifier instrument panel cluster alarm volume status/警报音量值状态";
CM_ SG_ 1140 STAT_Headrest_Mode "Headrest mode status/头枕模式状态";
CM_ SG_ 1140 STAT_AMPSoundEffectMegaBass "Amplifier sound effect megabass feedback/重低音设定值反馈";
CM_ SG_ 1140 STAT_AMPSoundEffectMidBass "Amplifier sound effect midbass feedback/中低音设定值反馈";
CM_ SG_ 1140 STAT_AMPSoundEffectMidTreble "Amplifier sound effect midtreble feedback/中高音设定值反馈";
CM_ SG_ 1140 STAT_VirtualSbwfrOnOff "Amplifier sound effect midtreble feedback/虚拟现场设定状态";
CM_ SG_ 1140 STAT_SurndFnOnOff "Surround_On_Off_Request feedback/3D环绕设定状态";
CM_ SG_ 1140 STAT_AMPBackgroundVolume "Amplifier background media volume status/背景音（迎宾音）音量值状态";
CM_ SG_ 1140 STAT_AMPSoundBypass "Amplifier sound bypass status/第三方APP打开时，外置功放做音效bypass处理状态";
CM_ SG_ 1140 STAT_AMPPwrRdySts "Amplifier Power Ready Status with A2B/A2B交互成功并支持出声后，反馈Ready";
CM_ SG_ 1206 EAMP_AMPKTVvoiceVolumeFed "Feedback Amplifier KTV voice volume status
反馈KTV人声音量设定";
CM_ SG_ 1206 EAMP_AMPENCVolumeFed "Feedback Amplifier ENC volume status
反馈ENC音量设定";
CM_ SG_ 1206 EAMP_AMPA2BKTVvoiceSoundFed "Feedback Status of Head unit KTV voice/IESS sound request to amplifier
反馈KTV人声/模拟声浪音源需求状态";
CM_ SG_ 1206 STAT_AMPSoundFocus_2 "Amplifier sound focus status反馈音场（最佳听音位）设定";
CM_ SG_ 1206 EAMP_AMPA2BENCSoundFed "Feedback Status of Head unit ENC sound request to amplifier
反馈ENC音源需求状态";
CM_ SG_ 1206 EAMP_AMPA2BChimeSoundFed "Feedback Status of Head unit Chime sound request to amplifier
反馈Chime音源需求状态";
CM_ SG_ 1361 EPC_LeftPedalSystem_Sts "左边电踏系统故障状态
0：正常
1：电压保护
2：系统故障
3：热保护
4：模式禁用
5：左边行驶保护
6：左边防夹保护";
CM_ SG_ 1361 EPC_RightPedalSystem_Sts "右边电踏系统状态
0：正常
1：电压保护
2：系统故障
3：热保护
4：模式禁用
5：右边行驶保护
6：右边防夹保护";
CM_ SG_ 1361 EPC_LeftPedalTimeTravel "左边电踏行程百分比";
CM_ SG_ 1361 EPC_RightPedalTimeTravel "右边电踏行程百分比";
CM_ SG_ 1361 EPC_LeftPedalRealTime_Sts "左边电踏实时状态
0：无效
1：左边踏板收回到位
2：左边踏板收回中
3：左边踏板收回失败
4：左边踏板展开到位
5：左边踏板展开中
6：左边踏板展开失败";
CM_ SG_ 1361 EPC_LeftPedalBreakIce_Sts "左边电踏实时破冰状态
0：无效
1：左边正在破冰
2：左边破冰成功
3：左边破冰失败";
CM_ SG_ 1361 EPC_RightPedalRealTime_Sts "右边电踏实时状态
0：无效
1：右边踏板收回到位
2：右边踏板收回中
3：右边踏板收回失败
4：右边踏板展开到位
5：右边踏板展开中
6：右边踏板展开失败";
CM_ SG_ 1361 EPC_RightPedalBreakIce_Sts "右边电踏实时破冰状态
0：无效
1：右边正在破冰
2：右边破冰成功
3：右边破冰失败";
CM_ SG_ 1361 EPC_Enable_CmdStatus "电踏功能模式使能反馈
0x0:无效值
0x1:踏板功能使能
0x2:踏板功能禁能";
CM_ SG_ 1361 EPC_LeftPedalCmdStatus "左边踏板反馈信号
0x1:左踏板展开
0x2:左踏板回收
0x3:自动";
CM_ SG_ 1361 EPC_RightPedalCmdStatus "右边踏板反馈信号
0x1:右边踏板展开
0x2:右边踏板回收
0x3:自动";
CM_ SG_ 1361 EPC_LeftPedal3D_Sts "左电踏收回和展开反馈（前提自动打开）
0x1:踏板3D软开关开启
0x2:踏板3D软开关关闭";
CM_ SG_ 1361 EPC_RightPedal3D_Sts "右电踏收回和展开反馈（前提自动打开）
0x1:踏板3D软开关开启
0x2:踏板3D软开关关闭";
CM_ SG_ 1349 SBOX_MSD_Res "MSD发送状态
0x0:inial
0x4:短信条数不够";
CM_ SG_ 1349 SBOX_Ecallphonenub_Res "通话状态";
CM_ SG_ 1451 SBOX_GNSS_ANT_State "GNSS天线状态";
CM_ SG_ 1451 SBOX_SIM_State "SIM卡状态";
CM_ SG_ 1451 SBOX_BT_State "蓝牙模组状态";
CM_ SG_ 1451 SBOX_TT_State "卫星模组状态";
CM_ SG_ 1451 SBOX_TT_ANT_State "卫星天线状态";
CM_ SG_ 1451 SBOX_BatterState "小电池状态";
CM_ SG_ 1451 SBOX_PowerState "主电状态";
CM_ SG_ 1451 SBOX_SimActivation "sim激活状态";
CM_ SG_ 1451 SBOX_TspActivation "TSP激活状态（OK才可发MSD短信）";
CM_ SG_ 1451 SBOX_SatelliteStatus "卫星网络状态";
CM_ SG_ 1451 SBOX_BtConState "蓝牙连接状态";
CM_ SG_ 1451 SBOX_SelfCheck "SBOX状态
（检测条件：上电注册网络作为功能是否正常）";
CM_ SG_ 1451 SBOX_SatelliteSignalValue "卫星信号强度";
CM_ SG_ 1451 SBOX_BatTemp "SBOX小电池温度";
CM_ SG_ 1451 SBOX_TimeSpentOnline "本次注网时长";
CM_ SG_ 1451 SBOX_RunTime "SBOX总运行时间";
CM_ SG_ 1451 SBOX_EcallState "ECALL状态";
CM_ SG_ 1351 SBOX_SetMsgTotal "当前短信总条数";
CM_ SG_ 1351 SBOX_SetMSDTotal "设置MSD短信阈值";
CM_ SG_ 1351 SBOX_SetCallTimeThreshold "设置通话总时长阈值";
CM_ SG_ 1351 SBOX_SetTodayCallTimeThreshold "设置当日通话时长阈值";
CM_ SG_ 1351 SBOX_SetCurretnCallTime "设置当前通话总时长";
CM_ SG_ 1351 SBOX_SetCurretnMsgThreshold "设置当前短信总条数";
CM_ SG_ 1351 SBOX_SetMsgTotalThreshold "设置短信总条数阈值";
CM_ SG_ 1351 SBOX_SetMsdThreshold "设置MSD短信阈值";
CM_ SG_ 1351 SBOX_SetCurrenMsdCnt "设置当前MSD短条数";
CM_ SG_ 1351 SBOX_SetCustomMsgThreshold "设置客户短信阈值";
CM_ SG_ 1351 SBOX_SetCurrentCustomMsgCnt "设置当前客户短信条数";
CM_ SG_ 1353 SBOX_ICC_MACReq "SBOX请求车机连接蓝牙";
CM_ SG_ 1353 SBOX_MAC_Req0 "本地MAC第0个字节";
CM_ SG_ 1353 SBOX_MAC_Req1 "本地MAC第1个字节";
CM_ SG_ 1353 SBOX_MAC_Req2 "本地MAC第2个字节";
CM_ SG_ 1353 SBOX_MAC_Req3 "本地MAC第3个字节";
CM_ SG_ 1353 SBOX_MAC_Req4 "本地MAC第4个字节";
CM_ SG_ 1353 SBOX_MAC_Req5 "本地MAC第5个字节";
CM_ SG_ 1358 SBOX_ActiveTsp_Res "TSP激活状态";
CM_ SG_ 1358 SBOX_ActiveSim_Res "SIM激活状态";
CM_ SG_ 1358 SBOX_Mac_Res0 "本地MAC第0个字节";
CM_ SG_ 1358 SBOX_Mac_Res1 "本地MAC第1个字节";
CM_ SG_ 1358 SBOX_Mac_Res2 "本地MAC第2个字节";
CM_ SG_ 1358 SBOX_Mac_Res3 "本地MAC第3个字节";
CM_ SG_ 1358 SBOX_Mac_Res4 "本地MAC第4个字节";
CM_ SG_ 1358 SBOX_Mac_Res5 "本地MAC第5个字节";
CM_ SG_ 1358 SBOX_GetPlatformNumberRes "平台号状态（有效，无效）";
CM_ SG_ 1358 SBOX_ICCId_Res0 "ICCID第0个字节（从左边开始）";
CM_ SG_ 1358 SBOX_ICCId_Res1 "ICCID第1个字节";
CM_ SG_ 1358 SBOX_ICCId_Res2 "ICCID第2个字节";
CM_ SG_ 1358 SBOX_ICCId_Res3 "ICCID第3个字节";
CM_ SG_ 1358 SBOX_ICCId_Res4 "ICCID第4个字节";
CM_ SG_ 1358 SBOX_ICCId_Res5 "ICCID第5个字节";
CM_ SG_ 1358 SBOX_ICCId_Res6 "ICCID第6个字节";
CM_ SG_ 1358 SBOX_ICCId_Res7 "ICCID第7个字节";
CM_ SG_ 1358 SBOX_ICCId_Res8 "ICCID第8个字节";
CM_ SG_ 1358 SBOX_ICCId_Res9 "ICCID第9个字节";
CM_ SG_ 1358 SBOX_ICCId_Res10 "ICCID第10个字节";
CM_ SG_ 1358 SBOX_ICCId_Res11 "ICCID第11个字节";
CM_ SG_ 1358 SBOX_ICCId_Res12 "ICCID第12个字节";
CM_ SG_ 1358 SBOX_ICCId_Res13 "ICCID第13个字节";
CM_ SG_ 1358 SBOX_ICCId_Res14 "ICCID第14个字节";
CM_ SG_ 1358 SBOX_ICCId_Res15 "ICCID第15个字节";
CM_ SG_ 1358 SBOX_ICCId_Res16 "ICCID第16个字节";
CM_ SG_ 1358 SBOX_ICCId_Res17 "ICCID第17个字节";
CM_ SG_ 1358 SBOX_ICCId_Res18 "ICCID第18个字节";
CM_ SG_ 1358 SBOX_ICCId_Res19 "ICCID第19个字节";
CM_ SG_ 1358 SBOX_Vin0 "VIN第0个字节（从左边开始）";
CM_ SG_ 1358 SBOX_Vin1 "VIN第1个字节('Z'-->5A(0101 1010))";
CM_ SG_ 1358 SBOX_Vin2 "VIN第2个字节";
CM_ SG_ 1358 SBOX_Vin3 "VIN第3个字节";
CM_ SG_ 1358 SBOX_Vin4 "VIN第4个字节";
CM_ SG_ 1358 SBOX_Vin5 "VIN第5个字节";
CM_ SG_ 1358 SBOX_Vin6 "VIN第6个字节";
CM_ SG_ 1358 SBOX_Vin7 "VIN第7个字节";
CM_ SG_ 1358 SBOX_Vin8 "VIN第8个字节";
CM_ SG_ 1358 SBOX_Vin9 "VIN第9个字节";
CM_ SG_ 1358 SBOX_Vin10 "VIN第10个字节";
CM_ SG_ 1358 SBOX_Vin11 "VIN第11个字节";
CM_ SG_ 1358 SBOX_Vin12 "VIN第12个字节";
CM_ SG_ 1358 SBOX_Vin13 "VIN第13个字节";
CM_ SG_ 1358 SBOX_Vin14 "VIN第14个字节";
CM_ SG_ 1358 SBOX_Vin15 "VIN第15个字节";
CM_ SG_ 1358 SBOX_Vin16 "VIN第16个字节";
CM_ SG_ 1078 PLG_LatchSts "尾门门锁状态";
CM_ SG_ 1310 BBCM_RLSeatEasyEntryExitFb "二排左侧便捷进入\离车";
CM_ SG_ 1310 BBCM_RRSeatEasyEntryExitFb "二排右侧便捷进入\离车";
CM_ SG_ 1310 BBCM_RLSeatNeedMemory "二排左侧座椅记忆弹框请求";
CM_ SG_ 1310 BBCM_RLMemoryFb "二排左侧记忆保存状态";
CM_ SG_ 1310 BBCM_RLRecoverFb "二排左侧记忆恢复状态";
CM_ SG_ 1310 BBCM_RRSeatNeedMemory "二排右侧座椅记忆弹框请求";
CM_ SG_ 1310 BBCM_RRMemoryFb "二排右侧记忆保存状态";
CM_ SG_ 1310 BBCM_RRRecoverFb "二排右侧记忆恢复状态";
CM_ SG_ 1310 BBCM_RLSeatLvlFb2nd "二排左侧座椅水平位置";
CM_ SG_ 1310 BBCM_RLSeatBackAgFb2nd "二排左侧座椅靠背角度位置";
CM_ SG_ 1310 BBCM_RLSeatLegSpprtFb2nd "二排左侧座椅腿托旋转位置";
CM_ SG_ 1310 BBCM_RLSeatLegRestAngleFb2nd "二排左侧座椅腿托延伸位置";
CM_ SG_ 1310 BBCM_RRSeatLvlFb2nd "二排右侧座椅水平位置";
CM_ SG_ 1310 BBCM_RRSeatBackAgFb2nd "二排右侧座椅靠背角度位置";
CM_ SG_ 1310 BBCM_RRSeatLegSpprtFb2nd "二排右侧座椅腿托旋转位置";
CM_ SG_ 1310 BBCM_RRSeatLegRestAngleFb2nd "二排右侧座椅腿托延伸位置";
CM_ SG_ 1310 BBCM_RLSeatBackAgFb3rd "三排左侧座椅靠背角度位置";
CM_ SG_ 1310 BBCM_RRSeatBackAgFb3rd "三排右侧座椅靠背角度位置";
CM_ SG_ 1310 BBCM_RLSeatFrontFlipFb3rd "三排左侧座椅前翻角度位置";
CM_ SG_ 1310 BBCM_RRSeatFrontFlipFb3rd "三排右侧座椅前翻角度位置";
CM_ SG_ 1201 CMSM_DisplaySwitch "吸顶屏开关反馈";
CM_ SG_ 1201 CMSM_DisplayAdjustrang "角度调节0-120°";
CM_ SG_ 1201 CMSM_DisplayAdjustmode "吸顶屏模式设置反馈";
CM_ SG_ 1201 CMSM_DisplayStandard "吸顶屏标定状态";
CM_ SG_ 1252 TotalOdometer_km_OBD "GB18285-2018新增OBD输出检查要求车辆累积行驶里程信号。";
CM_ SG_ 1252 DisplayVehicleSpeed "仪表显示的车速，比实际车速略大。";
CM_ SG_ 1252 ICC_TotalodometerbackupEnable "里程备份使能";
CM_ SG_ 1322 STAT_AMPAlarm "Instrument panel cluster alarm status to amplifier for chime play";
CM_ SG_ 1176 ICC_CH_3_CRC "Profile1A:E2E CRC (SAE J1850 CRC-8) for 8 Bytes
DataID:0x0048";
CM_ SG_ 1176 ICC_CH_3_RollgCntr "Profile1A:E2E Rolling message counter(the maximum value of Alive counter is 14)";
CM_ SG_ 1176 ICC_ASUAssistPassSet "Suspension assist in passing setting
悬架辅助通过设置";
CM_ SG_ 1176 IHU_AutHldSet "automatic hold set";
CM_ SG_ 1176 ICC_PABSetCmd "PAB Set Command";
CM_ SG_ 1176 ICC_EPBSetCmd "EPB Set Command";
CM_ SG_ 1176 ICC_ASUMemoryPosition "是否记忆当前悬架高度调节位置";
CM_ SG_ 1176 ICC_ASUEasyLoadingSet "ASU Easy Loading Setting
悬架手动便利装载设置";
CM_ SG_ 1176 Set_CSTFunctionSts "CST:Comfortable stop
To switch on or off CST function.";
CM_ SG_ 1176 ICC_ASURearaxlewithTaildoor "后轴高度与尾门开合关联";
CM_ SG_ 1176 TIHU_SetHDCOnOff "通过DVD设置HDC功能开关";
CM_ SG_ 1176 ICC_ASUPreviewCont "预瞄功能";
CM_ SG_ 1176 ICC_ASUHighwayModAdjust "高速路悬架高度自动调节";
CM_ SG_ 1176 ICC_ASUMapAdjust "悬架基于地图高度调节";
CM_ SG_ 1239 ICC_DisChg "Discharge switch";
CM_ SG_ 1239 ICC_StpDisChgReq "Stop discharge set";
CM_ SG_ 1239 ICC_RegenLevel "recovery level set";
CM_ SG_ 1239 ICC_ELockReq "解锁充放电枪电子锁";
CM_ SG_ 1239 ICC_DisChgPercent "discharge limit set SOC(ICC确认发送)";
CM_ SG_ 1239 ICC_ChgSocSet "Charge target SOC(ICC确认发送)";
CM_ SG_ 1239 ICC_CampMode "露营模式开启/关闭";
CM_ SG_ 1239 ICC_SftWarning "打开/关闭N档防误触提醒";
CM_ SG_ 1239 ICC_TowingMode "打开/关闭拖车模式服务";
CM_ SG_ 1239 ICC_StopMode "停车模式开关";
CM_ SG_ 1239 ICC_EPedalMode "E-Pedal模式开关";
CM_ SG_ 1246 ICC_WindowKeySts "Window Key Status
吹窗按键开关";
CM_ SG_ 1246 ICC_FaceKeySts "Face Key Status
吹面按键开关";
CM_ SG_ 1246 ICC_FootKeySts "Foot Key Status
吹脚按键开关";
CM_ SG_ 1246 BltCallSts "Whether the bluetooth call is turned on
蓝牙通话状态";
CM_ SG_ 1246 ICC_DockWinspSts "Constant display Blower Level
Set it once, first send the setting value three times and then send Not Active three times.";
CM_ SG_ 1246 ICC_DockTSts "Constant display SetTemp
Set it once, first send the setting value three times and then send Not Active three times.";
CM_ SG_ 1246 ICC_ACFastCool "AC Fast Cooling Working Status Set
空调极速降温工作状态设置";
CM_ SG_ 1246 ICC_ACFastHeat "AC Fast Heating Working Status Set
空调快速升温工作状态设置";
CM_ SG_ 1246 ICC_SetCLMOn "Set CLM On 
DVD设置空调开启";
CM_ SG_ 1246 ICC_SetAutoKeySts "Set Auto Status
DVD设置开启空调自动模式";
CM_ SG_ 1246 ICC_SetFrontDeforestSts "Set Front Deforest Status
DVD设置最大前除霜开启";
CM_ SG_ 1246 ICC_SetCirculationModeKeySts "Set Circulation Mode Key Status
DVD设置内外循环切换";
CM_ SG_ 1246 ICC_ZoneSelectionKeySts "Zone Selection Key Status
DVD设置单双区模式切换";
CM_ SG_ 1246 ICC_ResetFilter "Reset Filter Status
滤芯重置";
CM_ SG_ 1246 ICC_AUTODefrostOnKeySts "AUTO Defrost On Key Status
上报自动除雾设置项状态";
CM_ SG_ 1246 ICC_AutoAirClean "Auto Air Clean Set
上报座舱自动清洁设置项状态";
CM_ SG_ 1246 ICC_KeepWarm "Keep Warm Working Status Set
恒温模式工作状态设置";
CM_ SG_ 1246 ICC_BlowSpeedLevelKeySts "Blower Speed Level Key Status
鼓风机档位设置
在IHU上直接设置也通过此信号实现
电动IPM收，自动IPM不收";
CM_ SG_ 1246 ICC_SetACRequestKeySts "Set AC Request Status
DVD设置AC请求开启";
CM_ SG_ 1246 ICC_DSwingSet "Driver Air Swing Mode
主驾扫风模式设置";
CM_ SG_ 1246 ICC_PSwingSet "Passenge rAir Swing Mode
副驾扫风模式设置";
CM_ SG_ 1246 ICC_AUTODefLevelSet "AUTO Deforest Level Set
自动除雾等级信息";
CM_ SG_ 1246 ICC_SetTemperature_L_C "在单区模式下，调节左旋钮可以同时设定左右两边的温度设定。在双区模式下，左旋钮设定左区温度，右旋钮设定右区温度。
IHU未收到设定温值时，以及收到设定温值为startup 或default对应的1F时，IHU屏幕上温度显示区域均显示空白。
在IHU上直接设置也通过此信号实现 
电动空调配置时此信号预留不发
温度范围15.5-30.5℃
温度调节每次0.5℃
参数改变";
CM_ SG_ 1246 ICC_SetTemperature_R_C "在单区模式下，调节左旋钮可以同时设定左右两边的温度设定。在双区模式下，左旋钮设定左区温度，右旋钮设定右区温度。
IHU未收到设定温值时，以及收到设定温值为startup 或default对应的1F时，IHU屏幕上温度显示区域均显示空白。
在IHU上直接设置也通过此信号实现 
电动空调配置时此信号预留不发
温度范围15.5-30.5℃
温度调节每次0.5℃
参数改变";
CM_ SG_ 1246 ICC_DLSwingUpDwn "Driver Left Swing Up_Down Working Position Set
设置主驾左上下扫风电机工作位置";
CM_ SG_ 1246 ICC_DLSwingLeRi "Driver Left Swing Left_Right Working Position Set
设置主驾左左右扫风电机工作位置";
CM_ SG_ 1246 ICC_DRSwingUpDwn "Driver Right Swing Up_Down Working Position Set
设置主驾右上下扫风电机工作位置";
CM_ SG_ 1246 ICC_DRSwingLeRi "Driver Right Swing Left_Right Working Position Set
设置主驾右左右扫风电机工作位置";
CM_ SG_ 1246 ICC_PLSwingUpDwn "Passenger Left Swing Up_Down Working Position Set
设置副驾左上下扫风电机工作位置";
CM_ SG_ 1246 ICC_PLSwingLeRi "Passenger Left Swing Left_Right Working Position Set
设置副驾左左右扫风电机工作位置";
CM_ SG_ 1246 ICC_PRSwingUpDwn "Passenger Right Swing Up_Down Working Position Set
设置副驾右上下扫风电机工作位置";
CM_ SG_ 1246 ICC_PRSwingLeRi "Passenger Right Swing Left_Right Working Position Set
设置副驾右左右扫风电机工作位置";
CM_ SG_ 1246 ICC_DCSwingLeRi "Driver Center Swing Left_Right Working Position Set
设置主驾中上左右扫风电机工作位置";
CM_ SG_ 1246 ICC_NetWorkTemperature "Net Work Temperature
上报网络上温度";
CM_ SG_ 1246 ICC_NetWorkHumidity "Net Work Humidity
上报网络上湿度";
CM_ SG_ 1246 ICC_DLOnOff "Driver Left On_Off Status Set
主驾左出风口开关状态设置";
CM_ SG_ 1246 ICC_DROnOff "Driver Right On_Off Status Set
主驾右出风口开关状态设置";
CM_ SG_ 1246 ICC_PLOnOff "Passenger Left On_Off Status Set
副驾左出风口开关状态设置";
CM_ SG_ 1246 ICC_PROnOff "Passenger Right On_Off Status Set
副驾右出风口开关状态设置";
CM_ SG_ 1246 ICC_DCOnOff "Driver Center On_Off Status Set
中上出风口开关状态设置";
CM_ SG_ 1246 ICC_LoveRemind "Love Remind Working Status Set
爱心提醒工作状态设置";
CM_ SG_ 1246 ICC_InteCleanCar "Intelligent Clean Car Working Status Set
智能除味工作状态设置";
CM_ SG_ 1246 ICC_KeepWarmMemory "ICC恒温模式开关设定记忆状态
0x1:MemoryON(本次操作记忆)
0x2:Memory OFF(本次操作不记忆)";
CM_ SG_ 1250 ICC_AutoLightSW "AUTO灯开关，拨到该位置（打开）发1，不拨到该位置（关闭）发0，默认发0";
CM_ SG_ 1250 ICC_CleanMode "洗车模式";
CM_ SG_ 1250 ICC_1_OTASts "OTA status（拆帧为40B）";
CM_ SG_ 1250 ICC_1_OTAHV_Req "OTA high voltage power down request";
CM_ SG_ 1250 ICC_1_OTAPwrMngt "Power Management";
CM_ SG_ 1250 ICC_DriveModeSwitch "驾驶模式设置";
CM_ SG_ 1250 ICC_PropulsionMode "个性化-动力模式设置";
CM_ SG_ 1250 ICC_SteeringMode "个性化-转向模式设置";
CM_ SG_ 1250 ICC_SuspensionHeight "个性化-悬架高度设置";
CM_ SG_ 1250 ICC_SuspensionDamping "个性化-悬架阻尼设置";
CM_ SG_ 1250 ICC_AirconditionMode "个性化-空调模式设置";
CM_ SG_ 1250 ICC_BrakePedalFeelMode "个性化-制动踏板感觉设置
0x3:越野模式";
CM_ SG_ 1250 ICC_SentinelHV_Req "哨兵模式高压请求";
CM_ SG_ 1250 ICC_PetModeHV_Req "宠物模式高压请求";
CM_ SG_ 1250 ICC_SelfClearing "能耗分布自清零指令";
CM_ SG_ 1254 ICC_WelcomeOpenSet "迎宾灯开启设置";
CM_ SG_ 1254 ICC_WALOpenSet "远离闭锁开关设置";
CM_ SG_ 1254 ICC_EasytrunkSet "尾门感应开启设置开关";
CM_ SG_ 1254 ICC_UIROpenSet "靠近解锁开关设置";
CM_ SG_ 1254 ICC_BeanIDReq "车端大屏请求设备号";
CM_ SG_ 1254 ICC_CWCWorkingStsSet "通过DVD软按键控制无线充电器工作模式
0x0：不动作
0x1: 无线充电器关闭
0x2: 无线充电器打开
0x3：无效
CWC收到DVD的0x0、0x3时保持CWC当前开关状态";
CM_ SG_ 1254 ICC_CWCPhoneforgottenFunStsSet "通过DVD软按键控制无线充电器手机遗忘提醒功能的开关
0x0：不动作
0x1: 手机遗忘提醒功能关闭
0x2: 手机遗忘提醒功能打开
0x3：无效
CWC收到DVD的0x0、0x3时保持CWC当前手机遗忘提醒功能开关状态";
CM_ SG_ 1254 ICC_RCWCWorkingStsSet "通过DVD软按键控制无线充电器工作模式
0x0：不动作
0x1: 无线充电器关闭
0x2: 无线充电器打开
0x3：无效
RCWC收到DVD的0x0、0x3时保持RCWC当前开关状态";
CM_ SG_ 1296 CurrentTimeYear "时间（年）";
CM_ SG_ 1296 CurrentTimeMonth "时间（月）";
CM_ SG_ 1296 CurrentTimeDay "时间（日）";
CM_ SG_ 1296 CurrentTimeHour "时间（时）";
CM_ SG_ 1296 CurrentTimeMinute "时间（分）";
CM_ SG_ 1296 CurrentTimeSecond "时间（秒）";
CM_ SG_ 1447 CurrentTimeYear_UTC "时间（年）";
CM_ SG_ 1447 CurrentTimeMonth_UTC "时间（月）";
CM_ SG_ 1447 CurrentTimeDay_UTC "时间（日）";
CM_ SG_ 1447 CurrentTimeHour_UTC "时间（时）";
CM_ SG_ 1447 CurrentTimeMinute_UTC "时间（分）";
CM_ SG_ 1447 CurrentTimeSecond_UTC "时间（秒）";
CM_ SG_ 1100 Set_AMPNaviVolume "Amplifier navigation volume status";
CM_ SG_ 1100 Set_AMPVRVolume "Amplifier voice recognize volume status";
CM_ SG_ 1100 Set_AMPKeyTone "Amplifier key tone status";
CM_ SG_ 1100 Set_AMPMediaVolume "Amplifier media volume status";
CM_ SG_ 1100 Set_AMPPhoneVolume "Amplifier phone volume status";
CM_ SG_ 1100 Set_AMPSoundFocus "Amplifier sound focus status";
CM_ SG_ 1100 Set_AMPSoundEffect "Amplifier sound effect status";
CM_ SG_ 1100 Set_AMPSoundEffectBass "Amplifier sound effect bass status";
CM_ SG_ 1100 Set_AMPSoundEffectMidrange "Amplifier sound effect midrange status";
CM_ SG_ 1100 Set_AMPSoundEffectTreble "Amplifier sound effect treble status";
CM_ SG_ 1100 Set_AMPSoundFieldBalance "Amplifier sound field balance status";
CM_ SG_ 1100 Set_AMPSoundFieldFader "Amplifier sound field fader status";
CM_ SG_ 1100 Set_Headrest_Mode "Headrest_Mode";
CM_ SG_ 1100 Set_SurndFnOnOff "Surround Function On Off Switch";
CM_ SG_ 1100 Set_VirtualSbwfrOnOff "Virtual_Subwoofer_On_Off_Request";
CM_ SG_ 1119 Set_AMPMediaDuck "Media Duck request to amplifier/发送媒体降音需求给外置功放";
CM_ SG_ 1119 Set_AMPSpeedVolume "Amplifier vehicle speed volume compensation setting";
CM_ SG_ 1119 Set_AMPMute "Amplifier audio mute or not setting";
CM_ SG_ 1119 REQ_AMPA2BMediaSound "Head unit media sound request to amplifier";
CM_ SG_ 1119 REQ_AMPA2BNaviSound "Head unit navigation sound request to amplifier";
CM_ SG_ 1119 REQ_AMPA2BVRSound "Head unit VR sound request to amplifier";
CM_ SG_ 1119 REQ_AMPA2BTTSSound "Head unit TTS sound request to amplifier";
CM_ SG_ 1119 REQ_AMPA2BKeyTone "Head unit Beep sound request to amplifier";
CM_ SG_ 1119 Set_AMPRestoreDefaults "Amplifier audio restore defaults setting/恢复默认音频参数设置开关";
CM_ SG_ 1119 Set_AMPAlarmVolume "Amplifier instrument panel cluster alarm volume setting/警报音量值设定";
CM_ SG_ 1119 REQ_AMPA2BPhoneSound "Head unit BT Phone and Tbox sound request to amplifier/电话/Tbox音源需求设定";
CM_ SG_ 1119 Set_AMPSoundEffectMegaBass "Amplifier sound effect megabass setting/重低音设定";
CM_ SG_ 1119 Set_AMPSoundEffectMidBass "Amplifier sound effect midbass setting/中低音设定";
CM_ SG_ 1119 Set_AMPSoundEffectMidTreble "Amplifier sound effect midtreble setting/中高音设定";
CM_ SG_ 1119 Set_AMPBackgroundVolume "Amplifier background media volume status/背景音（迎宾音）音量值设定";
CM_ SG_ 1119 Set_AMPSoundBypass "Amplifier sound bypass need/第三方APP打开时，外置功放做音效bypass处理";
CM_ SG_ 1119 Set_AMPA2BConfig "Amplifier A2B Config status/EAMP的A2B节点配置完成后，下发OK";
CM_ SG_ 1150 ICC_BD_11_CRC "Profile1A:E2E CRC (SAE J1850 CRC-8) for 8 Bytes
DataID:0x009E";
CM_ SG_ 1150 ICC_BD_11_RollgCntr "Profile1A:E2E Rolling message counter(the maximum value of Alive counter is 14)";
CM_ SG_ 1150 ICC_CPDDelaySwitchSet "CIR功能延迟开关设置状态";
CM_ SG_ 1150 ICC_PPMIDBSRBPASet "Belt slack reduction(BSR) / 织带间隙消除
Belt parking assist(BPA) / 织带辅助回收";
CM_ SG_ 1150 ICC_PPMIDHwSet "Haptic Warning(HWA) /  震动触觉提醒";
CM_ SG_ 1150 ICC_DriveDrosinessLevel "0x0: not available;驾驶员在位检测输出“不在位”的时候触发
0x1: unknown;驾驶员不疲劳的默认状态
0x2: not fatigue;驾驶员不疲劳
0x3: lightly fatigue轻度疲劳,;
0x4: moderate fatigue中度疲劳;
0x5: severe fatigue重度疲劳;
0x6~0x7: Reserved";
CM_ SG_ 1150 ICC_FLDoorButton "大屏主驾门打开关闭，按钮按下是0x2 Active,不按是0x1 Inactive";
CM_ SG_ 1150 ICC_FRDoorButton "大屏副驾门打开关闭，按钮按下是0x2 Active,不按是0x1 Inactive";
CM_ SG_ 1150 ICC_RRDoorButton "大屏右后门打开关闭 按钮按下是0x2 Active,不按是0x1 Inactive";
CM_ SG_ 1150 ICC_RLDoorButton "大屏左后门打开关闭，按钮按下是0x2 Active,不按是0x1 Inactive";
CM_ SG_ 1150 ICC_CloseAllDoors "大屏一键电动门全关，按钮按下是0x2 Active,不按是0x1 Inactive";
CM_ SG_ 1150 ICC_DoorRemoteKeyControlEnable "长按钥匙远程控制使能";
CM_ SG_ 1150 ICC_SetOpenAngle "大屏设置侧门开度";
CM_ SG_ 1150 ICC_CPDSwitchSet "CIR功能开关设置状态";
CM_ SG_ 1150 ICC_FrontDoorPowerMode "前门手动模式、电动模式、半自动模式";
CM_ SG_ 1150 ICC_RearDoorPowerMode "后门手动模式、电动模式、半自动模式";
CM_ SG_ 1150 ICC_PedalCloseDriverDoorEnable "刹车踏板控制驾驶门 功能使能";
CM_ SG_ 1150 RR_Door_RearScreen_Control "The rear screen controls the door function to open/close/stop the rear door后排屏幕控制车门";
CM_ SG_ 1150 ICC_RearDoorVoiceControlEnable "后门语音控制使能";
CM_ SG_ 1150 ICC_FLVoiceControl "左前门语音控制";
CM_ SG_ 1150 ICC_FRVoiceControl "右前门语音控制";
CM_ SG_ 1150 ICC_RRVoiceControl "右后门语音控制";
CM_ SG_ 1150 ICC_RLVoiceControl "左后门语音控制";
CM_ SG_ 1150 RL_Door_RearScreen_Control "The rear screen controls the door function to open/close/stop the rear door后排屏幕控制车门";
CM_ SG_ 917 RandomMusicShowCMD "RandomMusic";
CM_ SG_ 917 DIYMusicShowmod "DIYMusicShow";
CM_ SG_ 917 LiShowMod "LightShowMode";
CM_ SG_ 917 MusicLoudness_55HZ "The corresponding audio loudness when the sampling point music frequency is 
55HZ
Note:
1.When DVD don't display music , DVD send this signal value 0x1F
2.Within a cycle time, If DVD don't acquire this frequency, DVD send this signal value 0x1F";
CM_ SG_ 917 MusicLoudness_123HZ "The corresponding audio loudness when the sampling point music frequency is 123HZ
Note:
1.When DVD don't display music , DVD send this signal value 0x1F
2.Within a cycle time, If DVD don't acquire this frequency, DVD send this signal value 0x1F";
CM_ SG_ 917 MusicLoudness_262HZ "The corresponding audio loudness when the sampling point music frequency is 262HZ
Note:
1.When DVD don't display music , DVD send this signal value 0x1F
2.Within a cycle time, If DVD don't acquire this frequency, DVD send this signal value 0x1F";
CM_ SG_ 917 MusicLoudness_440HZ "The corresponding audio loudness when the sampling point music frequency is 440HZ
Note:
1.When DVD don't display music , DVD send this signal value 0x1F
2.Within a cycle time, If DVD don't acquire this frequency, DVD send this signal value 0x1F";
CM_ SG_ 917 MusicLoudness_587HZ "The corresponding audio loudness when the sampling point music frequency is 587HZ
Note:
1.When DVD don't display music , DVD send this signal value 0x1F
2.Within a cycle time, If DVD don't acquire this frequency, DVD send this signal value 0x1F";
CM_ SG_ 917 MusicLoudness_784HZ "The corresponding audio loudness when the sampling point music frequency is 784HZ
Note:
1.When DVD don't display music , DVD send this signal value 0x1F
2.Within a cycle time, If DVD don't acquire this frequency, DVD send this signal value 0x1F";
CM_ SG_ 917 MusicLoudness_1318HZ "The corresponding audio loudness when the sampling point music frequency is 1318HZ
Note:
1.When DVD don't display music , DVD send this signal value 0x1F
2.Within a cycle time, If DVD don't acquire this frequency, DVD send this signal value 0x1F";
CM_ SG_ 917 MusicLoudness_2794HZ "The corresponding audio loudness when the sampling point music frequency is 2794HZ
Note:
1.When DVD don't display music , DVD send this signal value 0x1F
2.Within a cycle time, If DVD don't acquire this frequency, DVD send this signal value 0x1F";
CM_ SG_ 917 MusicLoudness_6272HZ "The corresponding audio loudness when the sampling point music frequency is 6272HZ
Note:
1.When DVD don't display music , DVD send this signal value 0x1F
2.Within a cycle time, If DVD don't acquire this frequency, DVD send this signal value 0x1F";
CM_ SG_ 917 ISDShowCMD "ISD灯光开启,同一个模式若想反复播放，需要先";
CM_ SG_ 917 ISDShowMode "ISD灯光模式";
CM_ SG_ 1273 FaceID "人脸ID";
CM_ SG_ 1157 ICC_DA_15_CRC "Profile1A:E2E CRC (SAE J1850 CRC-8) for 8 Bytes
DataID:0x009D";
CM_ SG_ 1157 ICC_DA_15_RollgCntr "Profile1A:E2E Rolling message counter(the maximum value of Alive counter is 14)";
CM_ SG_ 1157 ICC_DA_15_Resd "Profile1A:E2E Reserved";
CM_ SG_ 1157 ICC_DA_15_BSDLCWSettingSt "BSD/LCA function setting button status";
CM_ SG_ 1157 ICC_DA_15_DOWSettingSt "Door open warning function setting button status";
CM_ SG_ 1157 ICC_DA_15_RCWSettingSt "Rear Collision Warning function setting button status";
CM_ SG_ 1157 ICC_DA_15_RCTARCTBWarnType "RCTA/RCTB function setting button status";
CM_ SG_ 1157 ICC_DA_15_FCTAFCTBWarnType "FCTA/FCTB function setting button status";
CM_ SG_ 1157 ICC_DA_15_FrontPDCMuteSet "前PDC、侧PDC声音开关";
CM_ SG_ 1157 ICC_DA_15_FKPMuteSet "侧PDC声音开关";
CM_ SG_ 1157 Driver_EyeOnRoad "indicate Driver Eyes On Road status";
CM_ SG_ 1157 Dms_Status "DMS(Driver Monitor System) Status
驾驶员监测状态";
CM_ SG_ 1157 Driver_AbnormalBehavior "Driver Abnormal Behavior detection result
非正常行为";
CM_ SG_ 1157 Driver_GazeRegion "Driver Gaze Region
凝视的区域";
CM_ SG_ 1157 Dms_DriverPresence "indicate Driver Presence detection status
未检测到驾驶员";
CM_ SG_ 1157 ICC_IHCfunctionSw "智能远光辅助开关";
CM_ SG_ 1279 Weather_Type "天气类型
0x1：晴天
0x2：多云
0x3：阴天
0x4：阵雨
0x5：雷阵雨
0x6：雷阵雨夹冰雹
0x7：雨夹雪
0x8：小雨
0x9：中雨
0xA：大雨
0xB：暴风雨
0xF：小雪
0x10：中雪
0x11：大雪
0x12：暴风雪
0x13：雾天
0x15：尘暴
0x1E：尘埃
0x1F：风沙
0x21：雾霾";
CM_ SG_ 1279 ICC_SentinelModeSts "哨兵模式开启/关闭的状态";
CM_ SG_ 1279 ICC_CameraErrorCode "ICC侧Camera链路错误码";
CM_ SG_ 1279 ICC_SentinelRequest "哨兵模式进入，退出请求";
CM_ SG_ 1279 ICC_StartDeInitCameraStream "ICC通知ADCC开始关闭Camera视频流";
CM_ SG_ 1279 ICC_CameraRecoveryRequest "ICC通知ADCC恢复Camera视频链路";
CM_ SG_ 1279 ICC_CleanMode "洗车模式(主项目沿用)";
CM_ SG_ 644 ICM_5_FuelLevel "备注：国六项目EMS收，滤波后的燃油液位信息";
CM_ SG_ 644 FuelShortGround "备注：国六项目EMS收，短路到地";
CM_ SG_ 644 FuelShortPower "备注：国六项目EMS收，短路到电源";
CM_ SG_ 644 FuelOutOfRange "备注：国六项目EMS收。超范围";
CM_ SG_ 644 FuelValidData "备注：国六项目EMS收，开路，信号丢失";
CM_ SG_ 1174 IHU_SetSocManage "0x0:Not Active
0x1:Pure electricity priority mode（纯电优先）
0x2:Fuel priority mode（燃油优先）
0x3:SOC hold mode（电量保持）
0x4~0x7:Reserved";
CM_ SG_ 1174 IHU_SetSOC "设置电池";
CM_ SG_ 1174 CTP_PowerModeSet "动力模式设置";
CM_ SG_ 1174 LidOpenReq "加油小门开启请求";
CM_ SG_ 1174 ICC_ForcedEVMode "设置强制EV模式";
CM_ SG_ 1174 ICC_EmissionMode "设置排放检测模式";
CM_ SG_ 1174 ICC_ForcedEVChargeMode "设置强制发电模式";
CM_ SG_ 1174 EVOdometer_km "EV总里程";
CM_ SG_ 1174 EVOdometer_km_ValidData "EV总里程有效值";
CM_ SG_ 1174 ICC_SetChrgnFctMem "强制保电记忆开关设置";
CM_ SG_ 1242 ICC_DK_19_CRC1 "Profile1A:E2E CRC (SAE J1850 CRC-8) for 8 Bytes
DataID:No ASIL requirements.Not configure
CRC Reserved.";
CM_ SG_ 1242 ICC_DK_19_RollgCntr1 "Profile1A:E2E Rolling message counter(the maximum value of Alive counter is 14)";
CM_ SG_ 1242 ICC_DK_19_Resd1 "Profile1A:E2E Reserved";
CM_ SG_ 1242 ICC_DK_19_CMD "收到0不处理";
CM_ SG_ 1242 ICC_DK_19_PDU1 "收到0不处理";
CM_ SG_ 1242 ICC_DK_19_PDU2 "收到0不处理";
CM_ SG_ 1242 ICC_DK_19_PDU3 "收到0不处理";
CM_ SG_ 1242 ICC_DK_19_PDU4 "收到0不处理";
CM_ SG_ 1276 PassSeatHeiAdjmt_Target "座椅高度调节目标位置（大屏调节请求）";
CM_ SG_ 1276 SeatBackAndFwdAdjmt_Target "座椅水平调节目标值（大屏调节请求）";
CM_ SG_ 1276 SeatBackAgAdjmt_Target "座椅靠背角度调节目标值（大屏调节请求）";
CM_ SG_ 1276 Set_ProfileID "Set personalization profile ID number（记忆设置）";
CM_ SG_ 1276 SeatCushAgAdjmt_Target "座椅坐垫角度调节目标值（大屏调节请求）";
CM_ SG_ 1276 LgRstFwdAndBckAdjmt_Target "腿托前后位置目标值（大屏调节请求）";
CM_ SG_ 1276 FootRestAdjmt_Target "脚托调整位置目标值（大屏调节请求）";
CM_ SG_ 1276 REQ_SeatPosRecall "Seat position recall request";
CM_ SG_ 1276 REQ_SeatPosStore "Seat position store request";
CM_ SG_ 1276 Set_ToDefault "IHU setting function";
CM_ SG_ 1276 Set_EasyEntryEnable "Easy entry Set";
CM_ SG_ 1276 REQ_SeatHeatPass "Passenger Seat heating request from head unit";
CM_ SG_ 1276 REQ_SeatVentPass "Passenger Seat venting request from head unit";
CM_ SG_ 1276 PassSeatMsgStr_LvlCmd "0x0:未激活
0x1:关
0x2:低
0x3:中
0x4:高";
CM_ SG_ 1276 PassSeatMsg_ModeCmd "0x0：无动作
0x1:脉冲模式
0x2:波浪模式
0x3:猫步模式
0x4:单排模式
0x5:交叉模式
0x6:蝶形模式
0x7:腰部按摩模式
0x8:蛇形模式
0x9:特殊模式1
0xA:特殊模式2
0xB:特殊模式3
0xC:特殊模式4";
CM_ SG_ 1059 ICC_FLSeatHeatLevelCmd "一排主驾座椅加热信号";
CM_ SG_ 1059 ICC_FRSeatHeatLevelCmd "一排副驾座椅加热信号";
CM_ SG_ 1059 ICC_TrunkSW "后备箱开关";
CM_ SG_ 1059 ICC_Set_PLGOperateSts "电动尾门开度调节";
CM_ SG_ 1059 ICC_RLSeatHeatLevelCmd "二排左座椅加热";
CM_ SG_ 1059 ICC_RRSeatHeatLevelCmd "二排右座椅加热";
CM_ SG_ 1059 ICC_FLSeatVentLevelCmd "主驾座椅通风";
CM_ SG_ 1059 ICC_FRSeatVentLevelCmd "副驾座椅通风";
CM_ SG_ 1059 ICC_RLSeatVentLevelCmd "二排左座椅通风";
CM_ SG_ 1059 ICC_RRSeatVentLevelCmd "二排右座椅通风";
CM_ SG_ 1059 ICC_FrontWiperMaintenanceMode "大屏设置前雨刮维修
0x1:ON 进入维修
0x2: OFF退出维修";
CM_ SG_ 1059 ICC_RearWiperMaintenanceMode "大屏设置后雨刮维修
0x1:ON 进入维修
0x2: OFF退出维修";
CM_ SG_ 1056 ICC_DSBH_HeatReq "加热请求信号";
CM_ SG_ 1056 ICC_DSBH_SetTemp "设置加热温度，范围为30-65℃，即0x1E-0x41";
CM_ SG_ 1056 ICC_PSBH_HeatReq "加热请求信号";
CM_ SG_ 1056 ICC_PSBH_SetTemp "设置加热温度，范围为30-65℃，即0x1E-0x41";
CM_ SG_ 1112 PassSeatMsgStr_LvlCmd "0x0:未激活
0x1:关
0x2:低
0x3:中
0x4:高";
CM_ SG_ 1112 PassSeatMsg_ModeCmd "0x0:无动作
0x1:脉冲模式
0x2:波浪模式
0x3:猫步模式
0x4:单排模式
0x5:交叉模式
0x6:蝶形模式
0x7:腰部按摩模式
0x8:蛇形模式
0x9:特殊模式1
0xA:特殊模式2
0xB:特殊模式3
0xC:特殊模式4";
CM_ SG_ 1112 DriverSeatMsgStr_Lvlcmd "0x0:未激活
0x1:关
0x2:低
0x3:中
0x4:高";
CM_ SG_ 1112 DriverSeatMsg_ModeCmd "0x0:无动作
0x1:脉冲模式
0x2:波浪模式
0x3:猫步模式
0x4:单排模式
0x5:交叉模式
0x6:蝶形模式
0x7:腰部按摩模式
0x8:蛇形模式
0x9:特殊模式1
0xA:特殊模式2
0xB:特殊模式3
0xC:特殊模式4";
CM_ SG_ 1112 RightSeatMsgStr_LvlCmd "0x0:未激活
0x1:关
0x2:低
0x3:中
0x4:高";
CM_ SG_ 1112 RightSeatMsg_ModeCmd "0x0:无动作
0x1:脉冲模式
0x2:波浪模式
0x3:猫步模式
0x4:单排模式
0x5:交叉模式
0x6:蝶形模式
0x7:腰部按摩模式
0x8:蛇形模式
0x9:特殊模式1
0xA:特殊模式2
0xB:特殊模式3
0xC:特殊模式4";
CM_ SG_ 1112 LeftSeatMsgStr_LvlCmd "0x0:未激活
0x1:关
0x2:低
0x3:中
0x4:高";
CM_ SG_ 1112 LeftSeatMsg_ModeCmd "0x0:无动作
0x1:脉冲模式
0x2:波浪模式
0x3:猫步模式
0x4:单排模式
0x5:交叉模式
0x6:蝶形模式
0x7:腰部按摩模式
0x8:蛇形模式
0x9:特殊模式1
0xA:特殊模式2
0xB:特殊模式3
0xC:特殊模式4";
CM_ SG_ 1265 ICC_PwrOff "车辆下电";
CM_ SG_ 1265 ICC_EtmEgySave "极致节能模式";
CM_ SG_ 1265 ICC_HoodSW "前舱盖开关";
CM_ SG_ 1265 ICC_GloveboxSW "手套箱开关";
CM_ SG_ 1265 ICC_ChrgPortCover_Switch "充电口盖开关";
CM_ SG_ 1265 ICC_ReWinDefrstSwt "Rear window defrost后风窗加热";
CM_ SG_ 1265 ICC_RearMirrorFoldCmd "后视镜手动折叠开关";
CM_ SG_ 1265 ICC_CenterLockSwt "CenterLock中控锁开关";
CM_ SG_ 1265 ICC_ReverseExtMirrorSts "DVD设置倒车外后视镜下翻功能开启";
CM_ SG_ 1265 ICC_LightMainSwitchSts "小灯、近光、Auto开关";
CM_ SG_ 1265 ICC_AutoFoldSts "后视镜自动折叠";
CM_ SG_ 1265 ICC_HeadlampHeightSts "大灯高度调节设置信号";
CM_ SG_ 1265 ICC_WiprSnvty "WiperSensitivity雨刮灵敏度";
CM_ SG_ 1265 ICC_WindowCmd "语音控制车窗指令：
1、包含对左前车窗、右前车窗、左后车窗、右后车窗、前排车窗、后排车窗、全部车窗的指令控制；
2、具备open（打开）、close（关闭）、comfort（通风）三种动作指令，目前只有同时控制四个车窗时有comfort指令。
3、没有此功能，其他信号触发此帧报文发送时，此信号发“Not active”；";
CM_ SG_ 1265 ICC_LowBeamDelayOff "大灯延迟关闭开关";
CM_ SG_ 1265 ICC_FLWinCmd "玻璃升降防夹（霍尔、纹波）左前窗";
CM_ SG_ 1265 ICC_FRWinCmd "玻璃升降防夹（霍尔、纹波）右前窗";
CM_ SG_ 1265 ICC_RLWinCmd "玻璃升降防夹（霍尔、纹波）左后窗";
CM_ SG_ 1265 ICC_RRWinCmd "玻璃升降防夹（霍尔、纹波）左后窗";
CM_ SG_ 1265 ICC_FGHeatSts "设置前挡风加热";
CM_ SG_ 1265 ICC_AutolockSts "设置自动落锁模式";
CM_ SG_ 1265 ICC_WiperID "雨刮ID";
CM_ SG_ 1265 ICC_MaintenanceMode "雨刮维修模式开关";
CM_ SG_ 1265 ICC_lockSetSwitchSts "解闭锁设置";
CM_ SG_ 1265 ICC_ChildLockSW "儿童锁开关";
CM_ SG_ 1265 ICC_ParkUnlockEnable "驻车解锁设置";
CM_ SG_ 1265 ICC_BLEOpenDriverDoorEnable "蓝牙靠近开门设置";
CM_ SG_ 1265 ICC_WinInhbSwt "Window Inhibit 玻璃禁止开关";
CM_ SG_ 1265 ICC_SteerWhlHeatgSwt "Steering Wheel heating方向盘加热";
CM_ SG_ 1265 ICC_AutoHeatingset "后视镜自动加热设置";
CM_ SG_ 1265 ICC_FrontFogSw "屏内前雾灯开关";
CM_ SG_ 1265 ICC_RearFogSw "屏内后雾灯开关";
CM_ SG_ 1265 ICC_DoorControlSW "顶灯门控开关";
CM_ SG_ 1265 ICC_LockCarWinCloseSw "锁车自动升窗开关";
CM_ SG_ 1265 ICC_RainCarWinCloseSw "雨天自动升窗开关";
CM_ SG_ 1265 ICC_EasyEntryExitSet "便捷进入\离车";
CM_ SG_ 1265 ICC_NapTimeSet "小憩模式时长设置";
CM_ SG_ 1265 ICC_NapAreaSet "小憩模式开启区域设置";
CM_ SG_ 1265 ICC_NapStatusSet "小憩模式开关设置";
CM_ SG_ 1265 ICC_NapCFSStatusSet "小憩模式香氛系统开关设置";
CM_ SG_ 1265 ICC_NapSetTemperature "小憩模式设置空调温度";
CM_ SG_ 1265 ICC_SpoilerWelcomeFunSet "电动尾翼迎宾功能设置";
CM_ SG_ 1265 ICC_SpoilerCtrlCmd "电动尾翼控制设置";
CM_ SG_ 1265 ICC_HazardLightReq "双闪灯请求";
CM_ SG_ 1265 ICC_MusicStatus "K歌模式状态";
CM_ SG_ 1265 ICC_CinemaStatus "影院模式状态";
CM_ SG_ 1137 ICC_BookChrgSetReq "预约充电开启/取消设置请求";
CM_ SG_ 1137 ICC_BkChrgStartTimeYear "预约充电开始时间设置-年";
CM_ SG_ 1137 ICC_BkChrgStartTimeDay "预约充电开始时间设置-日";
CM_ SG_ 1137 ICC_BkChrgStartTimeHour "预约充电开始时间设置-时";
CM_ SG_ 1137 ICC_BkChrgStartTimemMin "预约充电开始时间设置-分";
CM_ SG_ 1137 ICC_BkChrgStartTimeMonth "预约充电开始时间设置-月";
CM_ SG_ 1137 ICC_BkChrgDuration "本地预约充电时长设置";
CM_ SG_ 1137 ICC_BkChrgCycleType "本地预约充电周期循环方式";
CM_ SG_ 1137 ICC_StopChrgReq "结束充电请求";
CM_ SG_ 1137 ICC_BkChrgCycleMon "预约充电周期循环_每周一循环";
CM_ SG_ 1137 ICC_BkChrgCycleTues "预约充电周期循环_每周二循环";
CM_ SG_ 1137 ICC_BkChrgCycleWen "预约充电周期循环_每周三循环";
CM_ SG_ 1137 ICC_BkChrgCycleThur "预约充电周期循环_每周四循环";
CM_ SG_ 1137 ICC_BkChrgCycleFri "预约充电周期循环_每周五循环";
CM_ SG_ 1137 ICC_BkChrgCycleSat "预约充电周期循环_每周六循环";
CM_ SG_ 1137 ICC_BkChrgCycleSun "预约充电周期循环_每周日循环";
CM_ SG_ 1137 ICC_KeepWarmStrt "插枪保温开始时间设置-日";
CM_ SG_ 1137 ICC_KeepWarmStrtHour "插枪保温开始时间设置-时";
CM_ SG_ 1137 ICC_KeepWarmStrtMin "插枪保温开始时间设置-分";
CM_ SG_ 1137 ICC_PetmodeFb "宠物模式反馈信号";
CM_ SG_ 1137 ICC_SentinelModeSwitchSts "哨兵开关状态";
CM_ SG_ 1137 ICC_SentinelModeWorkingSts "哨兵工作状态
0x0: NoActive，哨兵模式未进入或未激活
0x1: Active，哨兵模式已进入或激活
0x2: LowSOC 动力电池 电量低
0x3:HVNotReady，高压系统未上电
0x4: HVFault，高压系统故障
0x5: MirrorUnFold，后视镜未展开
0x6: CameraFault，摄像头故障
0x7:LowBatVolt，蓄电池电压低";
CM_ SG_ 1137 ICC_SentinelModeFaultSts "哨兵故障状态（摄像头被遮挡）
0x0:Not Warming
0x1:Artificial occlusion摄像头被人为遮挡
0x2 :Rain and snow cover摄像头被雨雪遮挡";
CM_ SG_ 1137 ICC_SentinelModeAlarmSts "哨兵模式报警状态
0x1: Level 1待命
0x2: Level 2警惕
0x3: Level 3警报";
CM_ SG_ 1137 ICC_SentinelModeExitReason "哨兵模式异常退出原因
0x0: Normal正常
0x1:LowSOC动力电池电量低
0x2:HVNotReady高压系统未上电
0x3:HVFault高压系统故障
0x4:MirrorUnFold后视镜未展开
0x5:CameraFault，摄像头故障
0x6:LowBatVolt蓄电池电压低";
CM_ SG_ 1137 ICC_PetModeWarn "宠物模式异常关闭
0x0:Not Active
0x1:高压电池电量低
0x2:空调异常
0x3:高压异常
0x4:低压电池电量低
0x5:高压电池电量低于15%
0x6:高压电池电量低于12%
0x7:时间过长预警";
CM_ SG_ 1137 ICC_TBOXPetmodeReq "ICC发给TBOX宠物模式激活请求
0x1:ON 激活
0X2:OFF 退出";
CM_ SG_ 1137 ICC_PetModeWarn_2 "宠物模式异常关闭
0x0:Not Active
0x1:高压电池电量低
0x2:空调异常
0x3:高压异常
0x4:低压电池电量低
0x5:高压电池电量低于15%
0x6:高压电池电量低于12%
0x7:时间过长预警
0x8:车辆充电中
0x9:车辆未设防
0xA:车辆档位为非P档";
CM_ SG_ 1137 ICM_FuelLevel "燃油量";
CM_ SG_ 1137 ICM_AverageVehicleSpeed "平均车速 (仪表计算)";
CM_ SG_ 1137 ICM_DistenceToEmpty_Km "燃油续航里程";
CM_ SG_ 1137 ICM_FuelLevelFailSts "燃油故障";
CM_ SG_ 1137 ICM_Maintenance_tips "保养提示（仪表计算，可能上传到平台）";
CM_ SG_ 1137 ICM_SumTrip "小计里程";
CM_ SG_ 1144 ICC_HvBattKeepWarmSet "中控插枪保温开关";
CM_ SG_ 1144 ICC_EnergyRegSet "能量回收强度调节设置";
CM_ SG_ 1144 ICC_HvBattKeepWarmActiveReq "插枪保温开始请求";
CM_ SG_ 1210 ICC_FLSeatHeiCmd "主驾座椅高度调节";
CM_ SG_ 1210 ICC_FLSeatLvlCmd "主驾座椅水平调节";
CM_ SG_ 1210 ICC_FLSeatBackAgCmd "主驾座椅靠背角度调节";
CM_ SG_ 1210 ICC_FLSeatCushCmd "主驾座椅坐垫角度调节";
CM_ SG_ 1210 ICC_FLSeatLegSpprtCmd "主驾座椅腿托调节";
CM_ SG_ 1210 ICC_FRSeatHeiCmd "副驾座椅高度调节";
CM_ SG_ 1210 ICC_FRSeatLvlCmd "副驾座椅水平调节";
CM_ SG_ 1210 ICC_FRSeatBackAgCmd "副驾座椅靠背角度调节";
CM_ SG_ 1210 ICC_FRSeatLegSpprtCmd "副驾座椅腿托调节";
CM_ SG_ 1210 ICC_MemoryRecoveryCmd "ICC记忆保存/恢复指令";
CM_ SG_ 1210 ICC_DeleteFaceID "删除ID";
CM_ SG_ 1210 ICC_FLSeatHeitargetCmd "主驾座椅高度调节目标";
CM_ SG_ 1210 ICC_FLSeatLvltargetCmd "主驾座椅水平调节目标";
CM_ SG_ 1210 ICC_FLSeatBackAgtargetCmd "主驾座椅靠背角度调节目标";
CM_ SG_ 1210 ICC_FLSeatCushtargetCmd "主驾座椅坐垫角度调节目标";
CM_ SG_ 1210 ICC_FLSeatLegSpprttargetCmd "主驾座椅腿托调节目标";
CM_ SG_ 1210 ICC_FRSeatHeitargetCmd "副驾座椅高度调节目标";
CM_ SG_ 1210 ICC_FRSeatLvltargetCmd "副驾座椅水平调节目标";
CM_ SG_ 1210 ICC_FRSeatBackAgtargetCmd "副驾座椅靠背角度调节目标";
CM_ SG_ 1210 ICC_FRSeatLegSpprttargetCmd "副驾座椅腿托调节目标";
CM_ SG_ 1210 ICC_NapFLSeatBackAgtargetSet "小憩模式设置主驾座椅靠背角度调节目标";
CM_ SG_ 1210 ICC_NapFRSeatBackAgtargetSet "小憩模式设置副驾座椅靠背角度调节目标";
CM_ SG_ 1210 ICC_NapFLSeatLvltargetSet "小憩模式设置主驾座椅水平调节目标";
CM_ SG_ 1210 ICC_NapFRSeatLvltargetSet "小憩模式设置副驾座椅水平调节目标";
CM_ SG_ 1210 ICC_FRSeatLegRestAngleCmd "副驾座椅腿托延伸调节";
CM_ SG_ 1210 ICC_FRSeatLegRestAngletargetCmd "副驾座椅腿托延伸调节目标";
CM_ SG_ 1210 ICC_FRSeatCushCmd "副驾座椅坐垫角度调节";
CM_ SG_ 1210 ICC_FRSeatCushtargetCmd "副驾座椅坐垫角度调节目标";
CM_ SG_ 1210 ICC_FRZeroGravitySeatSw "一键副驾零压座椅开关";
CM_ SG_ 1210 ICC_HomeLinkArmHornSet "HomeLink设防鸣笛设置状态";
CM_ SG_ 1210 ICC_HomeLinkWelLightSet "HomeLink迎宾灯设置";
CM_ SG_ 1210 ICC_HomeLinkPositionSts "HomeLink 位置状态";
CM_ SG_ 1210 ICC_WelcomeOpenSetCmd "迎宾灯开启设置";
CM_ SG_ 1210 ICC_WALOpenSetCmd "远离闭锁开关设置";
CM_ SG_ 1210 ICC_UIROpenSetCmd "靠近解锁开关设置";
CM_ SG_ 1210 ICC_EnjoyableSeatSwitch "一键尊享";
CM_ SG_ 1210 ICC_BLTKeyPESet "备注：设置蓝牙钥匙的PE功能ON/OFF状态
0x0：不动作
0x1：PE功能打开
0x2：PE功能关闭";
CM_ SG_ 1210 ICC_FRMemoryDeleteCmd "副驾座椅记忆删除";
CM_ SG_ 1210 ICC_FLSitPosnlocation "主驾座椅记忆设置";
CM_ SG_ 1210 ICC_FRSitPosnlocation "副驾座椅记忆设置";
CM_ SG_ 1210 ICC_FREasyEntryExitSet "副驾便捷进入\离车";
CM_ SG_ 1210 ICC_FRMemoryRecoveryCmd "ICC副驾记忆保存/恢复指令";
CM_ SG_ 1210 ICC_ConsoleAdjustSwitch "副仪表台调节开关
0x0:Not Active
0x1:Lock
0x2:Unlock
0x3:Forward(Reserved)
0x4:Backward(Reserved)
0x5:Delpoy一键最后
0x6:Retract一键最前
0x7:Middle
0x8:Stop";
BA_DEF_  "DBName" STRING ;
BA_DEF_  "BusType" STRING ;
BA_DEF_  "NmMessageCount" INT 0 255;
BA_DEF_  "NmBaseAddress" HEX 1536 1663;
BA_DEF_ BO_  "GenMsgCycleTimeFast" INT 0 50000;
BA_DEF_ BO_  "GenMsgNrOfRepetition" INT 0 999999;
BA_DEF_ BO_  "GenMsgDelayTime" INT 0 1000;
BA_DEF_ BO_  "VFrameFormat" ENUM  "StandardCAN","ExtendedCAN","reserved","reserved","reserved","reserved","reserved","reserved","reserved","reserved","reserved","reserved","reserved","reserved","StandardCAN_FD","ExtendedCAN_FD";
BA_DEF_ BO_  "GenMsgILSupport" ENUM  "No","Yes";
BA_DEF_ BO_  "NmMessage" ENUM  "No","Yes";
BA_DEF_ BO_  "GenMsgSendType" ENUM  "Cycle","Event","IfActive","CE","CA","NoMsgSendType";
BA_DEF_ BO_  "GenMsgCycleTime" INT 0 50000;
BA_DEF_ BO_  "CANFD_BRS" INT 0 1;
BA_DEF_ BO_  "NmAsrMessage" ENUM  "No","Yes";
BA_DEF_ BO_  "GRC_ASIL" ENUM  "vector_leerstring","QM","A","B","C","D";
BA_DEF_ BO_  "GRC_History" STRING ;
BA_DEF_ SG_  "GenSigStartValue" FLOAT 0 100000000000;
BA_DEF_ SG_  "GenSigInactiveValue" INT 0 100000;
BA_DEF_ SG_  "GenSigInvalidValue" INT 0 251610920;
BA_DEF_ SG_  "GenSigSendType" ENUM  "Cycle","OnChange","OnWrite","IfActive","OnChangeWithRepetition","OnWriteWithRepetition","IfActiveWithRepetition","NoSigSendType","OnChangeAndIfActive","OnChangeAndIfActiveWithRepetition","CA","CE","Event";
BA_DEF_ SG_  "GRC_Sig_ASIL" ENUM  "vector_leerstring","QM","A","B","C","D";
BA_DEF_ SG_  "E2EDataId" INT 0 0;
BA_DEF_ SG_  "E2EProfile" STRING ;
BA_DEF_ SG_  "E2EDataLength" INT 0 512;
BA_DEF_DEF_  "DBName" "";
BA_DEF_DEF_  "BusType" "CAN FD";
BA_DEF_DEF_  "NmMessageCount" 128;
BA_DEF_DEF_  "NmBaseAddress" 1536;
BA_DEF_DEF_  "GenMsgCycleTimeFast" 0;
BA_DEF_DEF_  "GenMsgNrOfRepetition" 0;
BA_DEF_DEF_  "GenMsgDelayTime" 0;
BA_DEF_DEF_  "VFrameFormat" "StandardCAN";
BA_DEF_DEF_  "GenMsgILSupport" "No";
BA_DEF_DEF_  "NmMessage" "No";
BA_DEF_DEF_  "GenMsgSendType" "NoMsgSendType";
BA_DEF_DEF_  "GenMsgCycleTime" 0;
BA_DEF_DEF_  "CANFD_BRS" 0;
BA_DEF_DEF_  "NmAsrMessage" "No";
BA_DEF_DEF_  "GRC_ASIL" "";
BA_DEF_DEF_  "GRC_History" "";
BA_DEF_DEF_  "GenSigStartValue" 0;
BA_DEF_DEF_  "GenSigInactiveValue" 0;
BA_DEF_DEF_  "GenSigInvalidValue" 0;
BA_DEF_DEF_  "GenSigSendType" "NoSigSendType";
BA_DEF_DEF_  "GRC_Sig_ASIL" "";
BA_DEF_DEF_  "E2EDataId" 0;
BA_DEF_DEF_  "E2EProfile" "";
BA_DEF_DEF_  "E2EDataLength" 0;
BA_ "DBName" "D01D01PMessageListICCANFDEEA51_V";
BA_ "CANFD_BRS" BO_ 1079 1;
BA_ "GenMsgCycleTime" BO_ 1079 100;
BA_ "GenMsgSendType" BO_ 1079 0;
BA_ "GenMsgILSupport" BO_ 1079 1;
BA_ "VFrameFormat" BO_ 1079 14;
BA_ "GenMsgILSupport" BO_ 1127 1;
BA_ "GenMsgSendType" BO_ 1127 0;
BA_ "GenMsgCycleTime" BO_ 1127 100;
BA_ "CANFD_BRS" BO_ 1127 1;
BA_ "VFrameFormat" BO_ 1127 14;
BA_ "CANFD_BRS" BO_ 1035 1;
BA_ "GenMsgCycleTime" BO_ 1035 100;
BA_ "GenMsgSendType" BO_ 1035 0;
BA_ "GenMsgILSupport" BO_ 1035 1;
BA_ "CANFD_BRS" BO_ 1345 1;
BA_ "GenMsgSendType" BO_ 1345 3;
BA_ "GenMsgCycleTime" BO_ 1345 100;
BA_ "GenMsgCycleTimeFast" BO_ 1345 50;
BA_ "GenMsgNrOfRepetition" BO_ 1345 3;
BA_ "GenMsgDelayTime" BO_ 1345 5;
BA_ "GenMsgILSupport" BO_ 1345 1;
BA_ "VFrameFormat" BO_ 1345 14;
BA_ "CANFD_BRS" BO_ 1121 1;
BA_ "GenMsgSendType" BO_ 1121 0;
BA_ "GenMsgCycleTime" BO_ 1121 100;
BA_ "GenMsgILSupport" BO_ 1121 1;
BA_ "GRC_History" BO_ 1121 "[{'approvedBy':'贾少辉','author':'吴慧','changesComments':'参考股份矩阵，初始值0x0补充，涉及存储记忆等值在功能规范定义','date':'2024/12/11','ecu':'EAMP_1(0x461)','ecuName':'ICC,EAMP','reviewedBy':'杨华','revision':'V2.1'}]";
BA_ "VFrameFormat" BO_ 1121 14;
BA_ "CANFD_BRS" BO_ 1140 1;
BA_ "GenMsgSendType" BO_ 1140 0;
BA_ "GenMsgCycleTime" BO_ 1140 100;
BA_ "GenMsgILSupport" BO_ 1140 1;
BA_ "GRC_History" BO_ 1140 "[{'approvedBy':'贾少辉','author':'吴慧','changesComments':'参考股份矩阵，初始值0x0补充，涉及存储记忆等值在功能规范定义','date':'2024/12/11','ecu':'EAMP_2(0x474)','ecuName':'ICC,EAMP','reviewedBy':'杨华','revision':'V2.1'}]";
BA_ "VFrameFormat" BO_ 1140 14;
BA_ "CANFD_BRS" BO_ 1206 1;
BA_ "GenMsgSendType" BO_ 1206 0;
BA_ "GenMsgCycleTime" BO_ 1206 100;
BA_ "GenMsgILSupport" BO_ 1206 1;
BA_ "VFrameFormat" BO_ 1206 14;
BA_ "CANFD_BRS" BO_ 1361 1;
BA_ "GenMsgSendType" BO_ 1361 0;
BA_ "GenMsgCycleTime" BO_ 1361 100;
BA_ "GenMsgILSupport" BO_ 1361 1;
BA_ "GRC_History" BO_ 1361 "[{'approvedBy':'贾少辉','author':'吴慧','changesComments':'枚举值新增EPC_LeftPedalCmdStatus信号0x3:Auto自动，ICC\n枚举值新增EPC_RightPedalCmdStatus信号0x3:Auto自动，枚举值中Left更新为Right\n新增信号EPC_LeftPedal3D_Sts和EPC_RightPedal3D_Sts与ICC交互','dat";
BA_ "VFrameFormat" BO_ 1361 14;
BA_ "CANFD_BRS" BO_ 1349 1;
BA_ "GenMsgSendType" BO_ 1349 1;
BA_ "GenMsgCycleTimeFast" BO_ 1349 100;
BA_ "GenMsgNrOfRepetition" BO_ 1349 3;
BA_ "GenMsgDelayTime" BO_ 1349 5;
BA_ "GenMsgILSupport" BO_ 1349 1;
BA_ "GRC_History" BO_ 1349 "[{'approvedBy':'贾少辉','author':'吴慧','changesComments':'报文名称SBOX_MSD_RES_1更改为SBOX_MSD_1（路由表同步更新）','date':'2024/11/21','ecu':'SBOX_MSD_1(0x545)','ecuName':'ICC,SBOX,TBOX','reviewedBy':'杨华','revision':'V2.0'}]";
BA_ "VFrameFormat" BO_ 1349 14;
BA_ "CANFD_BRS" BO_ 1451 1;
BA_ "GenMsgSendType" BO_ 1451 0;
BA_ "GenMsgCycleTime" BO_ 1451 1000;
BA_ "GenMsgILSupport" BO_ 1451 1;
BA_ "GRC_History" BO_ 1451 "[{'approvedBy':'贾少辉','author':'吴慧','changesComments':'ICC新增接收SBOX整帧报文，殷世双刘标','date':'2024/11/13','ecu':'SBOX_STATE_2(0x5AB)','ecuName':'ICC,SBOX','reviewedBy':'杨华','revision':'V1.3.1'},{'approvedBy':'贾少辉','author':'吴慧','changesC";
BA_ "VFrameFormat" BO_ 1451 14;
BA_ "CANFD_BRS" BO_ 1351 1;
BA_ "GenMsgSendType" BO_ 1351 1;
BA_ "GenMsgCycleTimeFast" BO_ 1351 100;
BA_ "GenMsgNrOfRepetition" BO_ 1351 3;
BA_ "GenMsgDelayTime" BO_ 1351 5;
BA_ "GenMsgILSupport" BO_ 1351 1;
BA_ "GRC_History" BO_ 1351 "[{'approvedBy':'贾少辉','author':'吴慧','changesComments':'报文名称SBOX_CFG_MSG_3更改为SBOX_CFG_3','date':'2024/11/21','ecu':'SBOX_CFG_3(0x547)','ecuName':'ICC,SBOX','reviewedBy':'杨华','revision':'V2.0'}]";
BA_ "VFrameFormat" BO_ 1351 14;
BA_ "CANFD_BRS" BO_ 1353 1;
BA_ "GenMsgSendType" BO_ 1353 1;
BA_ "GenMsgCycleTimeFast" BO_ 1353 100;
BA_ "GenMsgNrOfRepetition" BO_ 1353 3;
BA_ "GenMsgDelayTime" BO_ 1353 5;
BA_ "GenMsgILSupport" BO_ 1353 1;
BA_ "GRC_History" BO_ 1353 "[{'approvedBy':'贾少辉','author':'吴慧','changesComments':'报文名称SBOX_CFG_PARA_4更改为SBOX_CFG_4\n删除请求：本地MAC第6个字节 到 本地MAC第10个字节，与ICC_CFG_47(0x54C)一致','date':'2024/11/21','ecu':'SBOX_CFG_4(0x549)','ecuName':'ICC,SBOX','reviewedBy':";
BA_ "VFrameFormat" BO_ 1353 14;
BA_ "CANFD_BRS" BO_ 1358 1;
BA_ "GenMsgSendType" BO_ 1358 1;
BA_ "GenMsgCycleTimeFast" BO_ 1358 100;
BA_ "GenMsgNrOfRepetition" BO_ 1358 3;
BA_ "GenMsgDelayTime" BO_ 1358 5;
BA_ "GenMsgILSupport" BO_ 1358 1;
BA_ "GRC_History" BO_ 1358 "[{'approvedBy':'贾少辉','author':'吴慧','changesComments':'报文名称SBOX_CFG_PARA_RES_5更改为SBOX_CFG_5\n删除响应：本地MAC第6个字节 到 本地MAC第10个字节，与ICC_CFG_47(0x54C)一致','date':'2024/11/21','ecu':'SBOX_CFG_5(0x54E)','ecuName':'ICC,SBOX','reviewed";
BA_ "VFrameFormat" BO_ 1358 14;
BA_ "CANFD_BRS" BO_ 1078 1;
BA_ "GenMsgSendType" BO_ 1078 0;
BA_ "GenMsgCycleTime" BO_ 1078 100;
BA_ "GenMsgILSupport" BO_ 1078 1;
BA_ "GRC_History" BO_ 1078 "[{'approvedBy':'贾少辉','author':'吴慧','changesComments':'李思思BBCM补充未填写的无效值为0x0','date':'2024/11/22','ecu':'PLG_1(0x436)','ecuName':'BBCM,ICC,FLZCU,HCU','reviewedBy':'杨华','revision':'V2.0'},{'approvedBy':'贾少辉','author':'吴慧','changesCo";
BA_ "VFrameFormat" BO_ 1078 14;
BA_ "CANFD_BRS" BO_ 1310 1;
BA_ "GenMsgSendType" BO_ 1310 0;
BA_ "GenMsgCycleTime" BO_ 1310 100;
BA_ "GenMsgILSupport" BO_ 1310 1;
BA_ "GRC_History" BO_ 1310 "[{'approvedBy':'贾少辉','author':'吴慧','changesComments':'李思思BBCM补充未填写的初始值和无效值为0x0','date':'2024/11/22','ecu':'BBCM_1(0x51E)','ecuName':'BBCM,ICC','reviewedBy':'杨华','revision':'V2.0'},{'approvedBy':'贾少辉','author':'吴慧','changesCom";
BA_ "VFrameFormat" BO_ 1310 14;
BA_ "CANFD_BRS" BO_ 1201 1;
BA_ "GenMsgSendType" BO_ 1201 0;
BA_ "GenMsgCycleTime" BO_ 1201 100;
BA_ "GenMsgILSupport" BO_ 1201 1;
BA_ "GRC_History" BO_ 1201 "[{'approvedBy':'贾少辉','author':'吴慧','changesComments':'ICC新增接收CMSM_DisplayAdjustrang魏睿','date':'2024/11/7','ecu':'CMSM_1(0x4B1)','ecuName':'CMSM,ICC','reviewedBy':'杨华','revision':'V1.3.1'}]";
BA_ "VFrameFormat" BO_ 1201 14;
BA_ "CANFD_BRS" BO_ 1252 1;
BA_ "GenMsgSendType" BO_ 1252 0;
BA_ "GenMsgCycleTime" BO_ 1252 100;
BA_ "GenMsgILSupport" BO_ 1252 1;
BA_ "VFrameFormat" BO_ 1252 14;
BA_ "CANFD_BRS" BO_ 1322 1;
BA_ "GenMsgSendType" BO_ 1322 1;
BA_ "GenMsgCycleTimeFast" BO_ 1322 100;
BA_ "GenMsgNrOfRepetition" BO_ 1322 2;
BA_ "GenMsgDelayTime" BO_ 1322 5;
BA_ "GenMsgILSupport" BO_ 1322 1;
BA_ "GRC_History" BO_ 1322 "[{'approvedBy':'贾少辉','author':'吴慧','changesComments':'同步股份，补充所有未填写的初始值,补充为0x0','date':'2024/12/12','ecu':'ICC_IC_2(0x52A)','ecuName':'ICC,EAMP','reviewedBy':'杨华','revision':'V2.1'}]";
BA_ "VFrameFormat" BO_ 1322 14;
BA_ "CANFD_BRS" BO_ 1176 1;
BA_ "GenMsgSendType" BO_ 1176 3;
BA_ "GenMsgCycleTime" BO_ 1176 100;
BA_ "GenMsgCycleTimeFast" BO_ 1176 20;
BA_ "GenMsgNrOfRepetition" BO_ 1176 2;
BA_ "GenMsgDelayTime" BO_ 1176 5;
BA_ "GenMsgILSupport" BO_ 1176 1;
BA_ "GRC_History" BO_ 1176 "[{'approvedBy':'贾少辉','author':'吴慧','changesComments':'有其他网段做拆帧信号路由，接收端新增FLZCU接收','date':'2024/11/20','ecu':'ICC_CH_3(0x498)','ecuName':'ICC,FLZCU','reviewedBy':'杨华','revision':'V1.3.1'},{'approvedBy':'贾少辉','author':'吴慧','c";
BA_ "VFrameFormat" BO_ 1176 14;
BA_ "CANFD_BRS" BO_ 1239 1;
BA_ "GenMsgSendType" BO_ 1239 3;
BA_ "GenMsgCycleTime" BO_ 1239 100;
BA_ "GenMsgCycleTimeFast" BO_ 1239 50;
BA_ "GenMsgNrOfRepetition" BO_ 1239 2;
BA_ "GenMsgDelayTime" BO_ 1239 5;
BA_ "GenMsgILSupport" BO_ 1239 1;
BA_ "VFrameFormat" BO_ 1239 14;
BA_ "CANFD_BRS" BO_ 1246 1;
BA_ "GenMsgSendType" BO_ 1246 3;
BA_ "GenMsgCycleTime" BO_ 1246 100;
BA_ "GenMsgCycleTimeFast" BO_ 1246 50;
BA_ "GenMsgNrOfRepetition" BO_ 1246 2;
BA_ "GenMsgDelayTime" BO_ 1246 5;
BA_ "GenMsgILSupport" BO_ 1246 1;
BA_ "VFrameFormat" BO_ 1246 14;
BA_ "CANFD_BRS" BO_ 1250 1;
BA_ "GenMsgSendType" BO_ 1250 3;
BA_ "GenMsgCycleTime" BO_ 1250 100;
BA_ "GenMsgCycleTimeFast" BO_ 1250 50;
BA_ "GenMsgNrOfRepetition" BO_ 1250 2;
BA_ "GenMsgDelayTime" BO_ 1250 5;
BA_ "GenMsgILSupport" BO_ 1250 1;
BA_ "GRC_History" BO_ 1250 "[{'approvedBy':'贾少辉','author':'吴慧','changesComments':'枚举值新增ICC_BrakePedalFeelMode信号0x3:Offroad越野模式','date':'2024/11/22','ecu':'ICC_ZCU_6(0x4E2)','ecuName':'ICC,FLZCU','reviewedBy':'杨华','revision':'V2.0'}]";
BA_ "VFrameFormat" BO_ 1250 14;
BA_ "CANFD_BRS" BO_ 1254 1;
BA_ "GenMsgSendType" BO_ 1254 0;
BA_ "GenMsgCycleTime" BO_ 1254 100;
BA_ "GenMsgCycleTimeFast" BO_ 1254 50;
BA_ "GenMsgNrOfRepetition" BO_ 1254 2;
BA_ "GenMsgDelayTime" BO_ 1254 5;
BA_ "GenMsgILSupport" BO_ 1254 1;
BA_ "VFrameFormat" BO_ 1254 14;
BA_ "CANFD_BRS" BO_ 1296 1;
BA_ "GenMsgSendType" BO_ 1296 0;
BA_ "GenMsgCycleTime" BO_ 1296 500;
BA_ "GenMsgILSupport" BO_ 1296 1;
BA_ "GRC_History" BO_ 1296 "[{'approvedBy':'贾少辉','author':'吴慧','changesComments':'接收端更新：HCU新增接收时间信号','date':'2024/11/29','ecu':'ICC_COM_8(0x510)','ecuName':'ICC,HCU,FLZCU','reviewedBy':'杨华','revision':'V2.0'}]";
BA_ "VFrameFormat" BO_ 1296 14;
BA_ "CANFD_BRS" BO_ 1447 1;
BA_ "GenMsgSendType" BO_ 1447 0;
BA_ "GenMsgCycleTime" BO_ 1447 500;
BA_ "GenMsgILSupport" BO_ 1447 1;
BA_ "VFrameFormat" BO_ 1447 14;
BA_ "CANFD_BRS" BO_ 1100 1;
BA_ "GenMsgSendType" BO_ 1100 1;
BA_ "GenMsgCycleTimeFast" BO_ 1100 100;
BA_ "GenMsgNrOfRepetition" BO_ 1100 2;
BA_ "GenMsgDelayTime" BO_ 1100 5;
BA_ "GenMsgILSupport" BO_ 1100 1;
BA_ "VFrameFormat" BO_ 1100 14;
BA_ "CANFD_BRS" BO_ 1119 1;
BA_ "GenMsgSendType" BO_ 1119 1;
BA_ "GenMsgCycleTimeFast" BO_ 1119 100;
BA_ "GenMsgNrOfRepetition" BO_ 1119 2;
BA_ "GenMsgDelayTime" BO_ 1119 5;
BA_ "GenMsgILSupport" BO_ 1119 1;
BA_ "VFrameFormat" BO_ 1119 14;
BA_ "CANFD_BRS" BO_ 1150 1;
BA_ "GenMsgSendType" BO_ 1150 3;
BA_ "GenMsgCycleTime" BO_ 1150 100;
BA_ "GenMsgCycleTimeFast" BO_ 1150 50;
BA_ "GenMsgNrOfRepetition" BO_ 1150 2;
BA_ "GenMsgDelayTime" BO_ 1150 5;
BA_ "GenMsgILSupport" BO_ 1150 1;
BA_ "GRC_ASIL" BO_ 1150 2;
BA_ "GRC_History" BO_ 1150 "[{'approvedBy':'贾少辉','author':'吴慧','changesComments':'新增一列信息：E2E SignalGroup功能安全信号组','date':'2025/1/13','ecu':'ICC_BD_11(0x47E)','ecuName':'ICC,FLZCU','reviewedBy':'杨华','revision':'V2.1.1'}]";
BA_ "VFrameFormat" BO_ 1150 14;
BA_ "CANFD_BRS" BO_ 917 1;
BA_ "GenMsgSendType" BO_ 917 0;
BA_ "GenMsgCycleTime" BO_ 917 50;
BA_ "GenMsgILSupport" BO_ 917 1;
BA_ "VFrameFormat" BO_ 917 14;
BA_ "CANFD_BRS" BO_ 1273 1;
BA_ "GenMsgSendType" BO_ 1273 1;
BA_ "GenMsgCycleTimeFast" BO_ 1273 100;
BA_ "GenMsgNrOfRepetition" BO_ 1273 2;
BA_ "GenMsgDelayTime" BO_ 1273 5;
BA_ "GenMsgILSupport" BO_ 1273 1;
BA_ "VFrameFormat" BO_ 1273 14;
BA_ "CANFD_BRS" BO_ 1157 1;
BA_ "GenMsgSendType" BO_ 1157 3;
BA_ "GenMsgCycleTime" BO_ 1157 100;
BA_ "GenMsgCycleTimeFast" BO_ 1157 50;
BA_ "GenMsgNrOfRepetition" BO_ 1157 2;
BA_ "GenMsgDelayTime" BO_ 1157 5;
BA_ "GenMsgILSupport" BO_ 1157 1;
BA_ "GRC_ASIL" BO_ 1157 3;
BA_ "GRC_History" BO_ 1157 "[{'approvedBy':'贾少辉','author':'吴慧','changesComments':'新增一列信息：E2E SignalGroup功能安全信号组','date':'2025/1/13','ecu':'ICC_DA_15(0x485)','ecuName':'ICC','reviewedBy':'杨华','revision':'V2.1.1'}]";
BA_ "VFrameFormat" BO_ 1157 14;
BA_ "CANFD_BRS" BO_ 1279 1;
BA_ "GenMsgSendType" BO_ 1279 3;
BA_ "GenMsgCycleTime" BO_ 1279 100;
BA_ "GenMsgCycleTimeFast" BO_ 1279 50;
BA_ "GenMsgNrOfRepetition" BO_ 1279 2;
BA_ "GenMsgDelayTime" BO_ 1279 5;
BA_ "GenMsgILSupport" BO_ 1279 1;
BA_ "VFrameFormat" BO_ 1279 14;
BA_ "CANFD_BRS" BO_ 644 1;
BA_ "GenMsgSendType" BO_ 644 0;
BA_ "GenMsgCycleTime" BO_ 644 20;
BA_ "GenMsgILSupport" BO_ 644 1;
BA_ "VFrameFormat" BO_ 644 14;
BA_ "CANFD_BRS" BO_ 1174 1;
BA_ "GenMsgSendType" BO_ 1174 3;
BA_ "GenMsgCycleTime" BO_ 1174 100;
BA_ "GenMsgCycleTimeFast" BO_ 1174 50;
BA_ "GenMsgNrOfRepetition" BO_ 1174 2;
BA_ "GenMsgDelayTime" BO_ 1174 5;
BA_ "GenMsgILSupport" BO_ 1174 1;
BA_ "VFrameFormat" BO_ 1174 14;
BA_ "CANFD_BRS" BO_ 1242 1;
BA_ "GenMsgSendType" BO_ 1242 1;
BA_ "GenMsgDelayTime" BO_ 1242 5;
BA_ "GenMsgILSupport" BO_ 1242 1;
BA_ "VFrameFormat" BO_ 1242 14;
BA_ "CANFD_BRS" BO_ 1276 1;
BA_ "GenMsgSendType" BO_ 1276 0;
BA_ "GenMsgCycleTime" BO_ 1276 100;
BA_ "GenMsgCycleTimeFast" BO_ 1276 50;
BA_ "GenMsgNrOfRepetition" BO_ 1276 2;
BA_ "GenMsgDelayTime" BO_ 1276 5;
BA_ "GenMsgILSupport" BO_ 1276 1;
BA_ "VFrameFormat" BO_ 1276 14;
BA_ "CANFD_BRS" BO_ 1059 1;
BA_ "GenMsgSendType" BO_ 1059 0;
BA_ "GenMsgCycleTime" BO_ 1059 100;
BA_ "GenMsgCycleTimeFast" BO_ 1059 100;
BA_ "GenMsgNrOfRepetition" BO_ 1059 2;
BA_ "GenMsgDelayTime" BO_ 1059 5;
BA_ "GenMsgILSupport" BO_ 1059 1;
BA_ "VFrameFormat" BO_ 1059 14;
BA_ "CANFD_BRS" BO_ 1105 1;
BA_ "GenMsgSendType" BO_ 1105 0;
BA_ "GenMsgCycleTime" BO_ 1105 100;
BA_ "GenMsgCycleTimeFast" BO_ 1105 100;
BA_ "GenMsgNrOfRepetition" BO_ 1105 2;
BA_ "GenMsgDelayTime" BO_ 1105 5;
BA_ "GenMsgILSupport" BO_ 1105 1;
BA_ "VFrameFormat" BO_ 1105 14;
BA_ "CANFD_BRS" BO_ 1056 1;
BA_ "GenMsgSendType" BO_ 1056 3;
BA_ "GenMsgCycleTime" BO_ 1056 100;
BA_ "GenMsgCycleTimeFast" BO_ 1056 100;
BA_ "GenMsgNrOfRepetition" BO_ 1056 2;
BA_ "GenMsgDelayTime" BO_ 1056 5;
BA_ "GenMsgILSupport" BO_ 1056 1;
BA_ "VFrameFormat" BO_ 1056 14;
BA_ "CANFD_BRS" BO_ 1112 1;
BA_ "GenMsgSendType" BO_ 1112 0;
BA_ "GenMsgCycleTime" BO_ 1112 100;
BA_ "GenMsgCycleTimeFast" BO_ 1112 100;
BA_ "GenMsgNrOfRepetition" BO_ 1112 2;
BA_ "GenMsgDelayTime" BO_ 1112 5;
BA_ "GenMsgILSupport" BO_ 1112 1;
BA_ "VFrameFormat" BO_ 1112 14;
BA_ "CANFD_BRS" BO_ 1265 1;
BA_ "GenMsgSendType" BO_ 1265 3;
BA_ "GenMsgCycleTime" BO_ 1265 100;
BA_ "GenMsgCycleTimeFast" BO_ 1265 100;
BA_ "GenMsgNrOfRepetition" BO_ 1265 2;
BA_ "GenMsgDelayTime" BO_ 1265 5;
BA_ "GenMsgILSupport" BO_ 1265 1;
BA_ "VFrameFormat" BO_ 1265 14;
BA_ "CANFD_BRS" BO_ 1137 1;
BA_ "GenMsgSendType" BO_ 1137 3;
BA_ "GenMsgCycleTime" BO_ 1137 100;
BA_ "GenMsgCycleTimeFast" BO_ 1137 100;
BA_ "GenMsgNrOfRepetition" BO_ 1137 2;
BA_ "GenMsgDelayTime" BO_ 1137 5;
BA_ "GenMsgILSupport" BO_ 1137 1;
BA_ "VFrameFormat" BO_ 1137 14;
BA_ "CANFD_BRS" BO_ 1144 1;
BA_ "GenMsgSendType" BO_ 1144 0;
BA_ "GenMsgCycleTime" BO_ 1144 100;
BA_ "GenMsgCycleTimeFast" BO_ 1144 100;
BA_ "GenMsgNrOfRepetition" BO_ 1144 2;
BA_ "GenMsgDelayTime" BO_ 1144 5;
BA_ "GenMsgILSupport" BO_ 1144 1;
BA_ "VFrameFormat" BO_ 1144 14;
BA_ "CANFD_BRS" BO_ 1210 1;
BA_ "GenMsgSendType" BO_ 1210 3;
BA_ "GenMsgCycleTime" BO_ 1210 100;
BA_ "GenMsgCycleTimeFast" BO_ 1210 100;
BA_ "GenMsgNrOfRepetition" BO_ 1210 2;
BA_ "GenMsgDelayTime" BO_ 1210 5;
BA_ "GenMsgILSupport" BO_ 1210 1;
BA_ "VFrameFormat" BO_ 1210 14;
BA_ "GenSigSendType" SG_ 1079 BSCU_1_MotorLockSts 0;
BA_ "GenSigSendType" SG_ 1127 DCDC_FaultLevelSts 0;
BA_ "GRC_Sig_ASIL" SG_ 1127 DCDC_FaultLevelSts 1;
BA_ "GenSigSendType" SG_ 1035 VCC_1_OTASts 0;
BA_ "GenSigSendType" SG_ 1345 DVR_1_Sdcard_Sts 5;
BA_ "GenSigSendType" SG_ 1345 DVR_1_DVRFailReasons 5;
BA_ "GenSigSendType" SG_ 1345 DVR_1_RecordSts 5;
BA_ "GenSigSendType" SG_ 1121 STAT_AMPNaviVolume 0;
BA_ "GenSigSendType" SG_ 1121 STAT_AMPVRVolume 0;
BA_ "GenSigSendType" SG_ 1121 STAT_AMPKeyTone 0;
BA_ "GenSigSendType" SG_ 1121 STAT_AMPMediaVolume 0;
BA_ "GenSigSendType" SG_ 1121 STAT_AMPPhoneVolume 0;
BA_ "GenSigSendType" SG_ 1121 STAT_AMPSoundFocus 0;
BA_ "GenSigSendType" SG_ 1121 STAT_AMPSoundEffect 0;
BA_ "GenSigSendType" SG_ 1121 STAT_AMPSoundEffectBass 0;
BA_ "GenSigSendType" SG_ 1121 STAT_AMPSoundEffectMidrange 0;
BA_ "GenSigSendType" SG_ 1121 STAT_AMPSoundEffectTreble 0;
BA_ "GenSigSendType" SG_ 1121 STAT_AMPSoundFieldBalance 0;
BA_ "GenSigSendType" SG_ 1121 STAT_AMPSoundFieldFader 0;
BA_ "GenSigSendType" SG_ 1121 STAT_REQ_AMPA2BMediaSound 0;
BA_ "GenSigSendType" SG_ 1121 STAT_REQ_AMPA2BNaviSound 0;
BA_ "GenSigSendType" SG_ 1121 STAT_REQ_AMPA2BVRSound 0;
BA_ "GenSigSendType" SG_ 1121 STAT_REQ_AMPA2BTTSSound 0;
BA_ "GenSigSendType" SG_ 1121 STAT_REQ_AMPA2BPhoneSound 0;
BA_ "GenSigSendType" SG_ 1121 STAT_REQ_AMPAlarm 0;
BA_ "GenSigSendType" SG_ 1140 STAT_AMPMediaDuck 0;
BA_ "GenSigSendType" SG_ 1140 STAT_AMPSpeedVolume 0;
BA_ "GenSigSendType" SG_ 1140 STAT_AMPMute 0;
BA_ "GenSigSendType" SG_ 1140 STAT_AMPRestoreDefaults 0;
BA_ "GenSigSendType" SG_ 1140 STAT_AMPAlarmVolume 0;
BA_ "GenSigSendType" SG_ 1140 STAT_Headrest_Mode 0;
BA_ "GenSigSendType" SG_ 1140 STAT_AMPSoundEffectMegaBass 0;
BA_ "GenSigSendType" SG_ 1140 STAT_AMPSoundEffectMidBass 0;
BA_ "GenSigSendType" SG_ 1140 STAT_AMPSoundEffectMidTreble 0;
BA_ "GenSigSendType" SG_ 1140 STAT_VirtualSbwfrOnOff 0;
BA_ "GenSigSendType" SG_ 1140 STAT_SurndFnOnOff 0;
BA_ "GenSigSendType" SG_ 1140 STAT_AMPBackgroundVolume 0;
BA_ "GenSigSendType" SG_ 1140 STAT_AMPSoundBypass 0;
BA_ "GenSigSendType" SG_ 1140 STAT_AMPPwrRdySts 0;
BA_ "GenSigSendType" SG_ 1140 STAT_AMPVersion 0;
BA_ "GenSigSendType" SG_ 1206 STAT_AMPKeyVolume 0;
BA_ "GenSigSendType" SG_ 1206 EAMP_AMPKTVvoiceVolumeFed 0;
BA_ "GenSigSendType" SG_ 1206 EAMP_AMPENCVolumeFed 0;
BA_ "GenSigSendType" SG_ 1206 EAMP_AMPA2BKTVvoiceSoundFed 0;
BA_ "GenSigSendType" SG_ 1206 STAT_AMPSoundFocus_2 0;
BA_ "GenSigSendType" SG_ 1206 EAMP_AMPA2BENCSoundFed 0;
BA_ "GenSigSendType" SG_ 1206 EAMP_AMPA2BChimeSoundFed 0;
BA_ "GenSigSendType" SG_ 1361 EPC_LeftPedalSystem_Sts 0;
BA_ "GenSigInvalidValue" SG_ 1361 EPC_LeftPedalSystem_Sts 15;
BA_ "GenSigSendType" SG_ 1361 EPC_RightPedalSystem_Sts 0;
BA_ "GenSigInvalidValue" SG_ 1361 EPC_RightPedalSystem_Sts 15;
BA_ "GenSigSendType" SG_ 1361 EPC_LeftPedalTimeTravel 0;
BA_ "GenSigSendType" SG_ 1361 EPC_RightPedalTimeTravel 0;
BA_ "GenSigSendType" SG_ 1361 EPC_LeftPedalRealTime_Sts 0;
BA_ "GenSigSendType" SG_ 1361 EPC_LeftPedalBreakIce_Sts 0;
BA_ "GenSigSendType" SG_ 1361 EPC_RightPedalRealTime_Sts 0;
BA_ "GenSigSendType" SG_ 1361 EPC_RightPedalBreakIce_Sts 0;
BA_ "GenSigSendType" SG_ 1361 EPC_Enable_CmdStatus 0;
BA_ "GenSigInvalidValue" SG_ 1361 EPC_Enable_CmdStatus 3;
BA_ "GenSigSendType" SG_ 1361 EPC_LeftPedalCmdStatus 0;
BA_ "GenSigStartValue" SG_ 1361 EPC_LeftPedalCmdStatus 3;
BA_ "GenSigSendType" SG_ 1361 EPC_RightPedalCmdStatus 0;
BA_ "GenSigStartValue" SG_ 1361 EPC_RightPedalCmdStatus 3;
BA_ "GenSigSendType" SG_ 1361 EPC_LeftPedal3D_Sts 0;
BA_ "GenSigSendType" SG_ 1361 EPC_RightPedal3D_Sts 0;
BA_ "GenSigSendType" SG_ 1349 SBOX_MSD_Res 12;
BA_ "GenSigSendType" SG_ 1349 SBOX_Ecallphonenub_Res 12;
BA_ "GenSigSendType" SG_ 1451 SBOX_GNSS_ANT_State 0;
BA_ "GenSigInvalidValue" SG_ 1451 SBOX_GNSS_ANT_State 3;
BA_ "GenSigSendType" SG_ 1451 SBOX_SIM_State 0;
BA_ "GenSigInvalidValue" SG_ 1451 SBOX_SIM_State 3;
BA_ "GenSigSendType" SG_ 1451 SBOX_BT_State 0;
BA_ "GenSigInvalidValue" SG_ 1451 SBOX_BT_State 3;
BA_ "GenSigSendType" SG_ 1451 SBOX_TT_State 0;
BA_ "GenSigInvalidValue" SG_ 1451 SBOX_TT_State 3;
BA_ "GenSigSendType" SG_ 1451 SBOX_TT_ANT_State 0;
BA_ "GenSigInvalidValue" SG_ 1451 SBOX_TT_ANT_State 3;
BA_ "GenSigSendType" SG_ 1451 SBOX_BatterState 0;
BA_ "GenSigInvalidValue" SG_ 1451 SBOX_BatterState 3;
BA_ "GenSigSendType" SG_ 1451 SBOX_PowerState 0;
BA_ "GenSigInvalidValue" SG_ 1451 SBOX_PowerState 3;
BA_ "GenSigSendType" SG_ 1451 SBOX_SimActivation 0;
BA_ "GenSigSendType" SG_ 1451 SBOX_TspActivation 0;
BA_ "GenSigSendType" SG_ 1451 SBOX_SatelliteStatus 0;
BA_ "GenSigSendType" SG_ 1451 SBOX_BtConState 0;
BA_ "GenSigSendType" SG_ 1451 SBOX_SelfCheck 0;
BA_ "GenSigSendType" SG_ 1451 SBOX_SatelliteSignalValue 0;
BA_ "GenSigSendType" SG_ 1451 SBOX_BatTemp 0;
BA_ "GenSigStartValue" SG_ 1451 SBOX_BatTemp 255;
BA_ "GenSigSendType" SG_ 1451 SBOX_TimeSpentOnline 0;
BA_ "GenSigSendType" SG_ 1451 SBOX_RunTime 0;
BA_ "GenSigSendType" SG_ 1451 SBOX_EcallState 0;
BA_ "GenSigSendType" SG_ 1351 SBOX_SetMsgTotal 2;
BA_ "GenSigSendType" SG_ 1351 SBOX_SetMSDTotal 2;
BA_ "GenSigSendType" SG_ 1351 SBOX_SetCallTimeThreshold 2;
BA_ "GenSigSendType" SG_ 1351 SBOX_SetTodayCallTimeThreshold 2;
BA_ "GenSigSendType" SG_ 1351 SBOX_SetCurretnCallTime 2;
BA_ "GenSigSendType" SG_ 1351 SBOX_SetCurretnMsgThreshold 2;
BA_ "GenSigSendType" SG_ 1351 SBOX_SetMsgTotalThreshold 2;
BA_ "GenSigSendType" SG_ 1351 SBOX_SetMsdThreshold 2;
BA_ "GenSigSendType" SG_ 1351 SBOX_SetCurrenMsdCnt 2;
BA_ "GenSigSendType" SG_ 1351 SBOX_SetCustomMsgThreshold 2;
BA_ "GenSigSendType" SG_ 1351 SBOX_SetCurrentCustomMsgCnt 2;
BA_ "GenSigSendType" SG_ 1353 SBOX_ICC_MACReq 2;
BA_ "GenSigSendType" SG_ 1353 SBOX_MAC_Req0 2;
BA_ "GenSigSendType" SG_ 1353 SBOX_MAC_Req1 2;
BA_ "GenSigSendType" SG_ 1353 SBOX_MAC_Req2 2;
BA_ "GenSigSendType" SG_ 1353 SBOX_MAC_Req3 2;
BA_ "GenSigSendType" SG_ 1353 SBOX_MAC_Req4 2;
BA_ "GenSigSendType" SG_ 1353 SBOX_MAC_Req5 2;
BA_ "GenSigSendType" SG_ 1358 SBOX_ActiveTsp_Res 2;
BA_ "GenSigSendType" SG_ 1358 SBOX_ActiveSim_Res 2;
BA_ "GenSigSendType" SG_ 1358 SBOX_Mac_Res0 2;
BA_ "GenSigSendType" SG_ 1358 SBOX_Mac_Res1 2;
BA_ "GenSigSendType" SG_ 1358 SBOX_Mac_Res2 2;
BA_ "GenSigSendType" SG_ 1358 SBOX_Mac_Res3 2;
BA_ "GenSigSendType" SG_ 1358 SBOX_Mac_Res4 2;
BA_ "GenSigSendType" SG_ 1358 SBOX_Mac_Res5 2;
BA_ "GenSigSendType" SG_ 1358 SBOX_GetPlatformNumberRes 2;
BA_ "GenSigSendType" SG_ 1358 SBOX_ICCId_Res0 2;
BA_ "GenSigSendType" SG_ 1358 SBOX_ICCId_Res1 2;
BA_ "GenSigSendType" SG_ 1358 SBOX_ICCId_Res2 2;
BA_ "GenSigSendType" SG_ 1358 SBOX_ICCId_Res3 2;
BA_ "GenSigSendType" SG_ 1358 SBOX_ICCId_Res4 2;
BA_ "GenSigSendType" SG_ 1358 SBOX_ICCId_Res5 2;
BA_ "GenSigSendType" SG_ 1358 SBOX_ICCId_Res6 2;
BA_ "GenSigSendType" SG_ 1358 SBOX_ICCId_Res7 2;
BA_ "GenSigSendType" SG_ 1358 SBOX_ICCId_Res8 2;
BA_ "GenSigSendType" SG_ 1358 SBOX_ICCId_Res9 2;
BA_ "GenSigSendType" SG_ 1358 SBOX_ICCId_Res10 2;
BA_ "GenSigSendType" SG_ 1358 SBOX_ICCId_Res11 2;
BA_ "GenSigSendType" SG_ 1358 SBOX_ICCId_Res12 2;
BA_ "GenSigSendType" SG_ 1358 SBOX_ICCId_Res13 2;
BA_ "GenSigSendType" SG_ 1358 SBOX_ICCId_Res14 2;
BA_ "GenSigSendType" SG_ 1358 SBOX_ICCId_Res15 2;
BA_ "GenSigSendType" SG_ 1358 SBOX_ICCId_Res16 2;
BA_ "GenSigSendType" SG_ 1358 SBOX_ICCId_Res17 2;
BA_ "GenSigSendType" SG_ 1358 SBOX_ICCId_Res18 2;
BA_ "GenSigSendType" SG_ 1358 SBOX_ICCId_Res19 2;
BA_ "GenSigSendType" SG_ 1358 SBOX_Vin0 2;
BA_ "GenSigSendType" SG_ 1358 SBOX_Vin1 2;
BA_ "GenSigSendType" SG_ 1358 SBOX_Vin2 2;
BA_ "GenSigSendType" SG_ 1358 SBOX_Vin3 2;
BA_ "GenSigSendType" SG_ 1358 SBOX_Vin4 2;
BA_ "GenSigSendType" SG_ 1358 SBOX_Vin5 2;
BA_ "GenSigSendType" SG_ 1358 SBOX_Vin6 2;
BA_ "GenSigSendType" SG_ 1358 SBOX_Vin7 2;
BA_ "GenSigSendType" SG_ 1358 SBOX_Vin8 2;
BA_ "GenSigSendType" SG_ 1358 SBOX_Vin9 2;
BA_ "GenSigSendType" SG_ 1358 SBOX_Vin10 2;
BA_ "GenSigSendType" SG_ 1358 SBOX_Vin11 2;
BA_ "GenSigSendType" SG_ 1358 SBOX_Vin12 2;
BA_ "GenSigSendType" SG_ 1358 SBOX_Vin13 2;
BA_ "GenSigSendType" SG_ 1358 SBOX_Vin14 2;
BA_ "GenSigSendType" SG_ 1358 SBOX_Vin15 2;
BA_ "GenSigSendType" SG_ 1358 SBOX_Vin16 2;
BA_ "GenSigSendType" SG_ 1078 PLG_LatchSts 0;
BA_ "GenSigInvalidValue" SG_ 1078 PLG_LatchSts 3;
BA_ "GenSigStartValue" SG_ 1078 PLG_LatchSts 2;
BA_ "GenSigSendType" SG_ 1310 BBCM_RLSeatMovFailCause3nd 0;
BA_ "GenSigSendType" SG_ 1310 BBCM_RRSeatMovFailCause3nd 0;
BA_ "GenSigSendType" SG_ 1310 BBCM_RLSeatMovFailCause2nd 0;
BA_ "GenSigSendType" SG_ 1310 BBCM_RRSeatMovFailCause2nd 0;
BA_ "GenSigSendType" SG_ 1310 BBCM_RRSeatExpSwSt2rd 0;
BA_ "GenSigSendType" SG_ 1310 BBCM_RRSeatExpSwCmd2rd 0;
BA_ "GenSigSendType" SG_ 1310 BBCM_RRSeatSwCmd3rd 0;
BA_ "GenSigSendType" SG_ 1310 BBCM_RLSeatSwCmd3rd 0;
BA_ "GenSigSendType" SG_ 1310 BBCM_RLSeatEasyEntryExitFb 0;
BA_ "GenSigSendType" SG_ 1310 BBCM_RRSeatEasyEntryExitFb 0;
BA_ "GenSigSendType" SG_ 1310 BBCM_RLSeatNeedMemory 0;
BA_ "GenSigSendType" SG_ 1310 BBCM_RLMemoryFb 0;
BA_ "GenSigSendType" SG_ 1310 BBCM_RLRecoverFb 0;
BA_ "GenSigSendType" SG_ 1310 BBCM_RRSeatNeedMemory 0;
BA_ "GenSigSendType" SG_ 1310 BBCM_RRMemoryFb 0;
BA_ "GenSigSendType" SG_ 1310 BBCM_RRRecoverFb 0;
BA_ "GenSigSendType" SG_ 1310 BBCM_RLSeatLvlFb2nd 0;
BA_ "GenSigSendType" SG_ 1310 BBCM_RLSeatBackAgFb2nd 0;
BA_ "GenSigSendType" SG_ 1310 BBCM_RLSeatLegSpprtFb2nd 0;
BA_ "GenSigSendType" SG_ 1310 BBCM_RLSeatLegRestAngleFb2nd 0;
BA_ "GenSigSendType" SG_ 1310 BBCM_RRSeatLvlFb2nd 0;
BA_ "GenSigSendType" SG_ 1310 BBCM_RRSeatBackAgFb2nd 0;
BA_ "GenSigSendType" SG_ 1310 BBCM_RRSeatLegSpprtFb2nd 0;
BA_ "GenSigSendType" SG_ 1310 BBCM_RRSeatLegRestAngleFb2nd 0;
BA_ "GenSigSendType" SG_ 1310 BBCM_RLSeatBackAgFb3rd 0;
BA_ "GenSigSendType" SG_ 1310 BBCM_RRSeatBackAgFb3rd 0;
BA_ "GenSigSendType" SG_ 1310 BBCM_RLSeatFrontFlipFb3rd 0;
BA_ "GenSigSendType" SG_ 1310 BBCM_RRSeatFrontFlipFb3rd 0;
BA_ "GenSigSendType" SG_ 1201 CMSM_BLDCFaultSt 0;
BA_ "GenSigSendType" SG_ 1201 CMSM_DisplaySwitch 0;
BA_ "GenSigSendType" SG_ 1201 CMSM_DisplayAdjustrang 0;
BA_ "GenSigSendType" SG_ 1201 CMSM_DisplayAdjustmode 0;
BA_ "GenSigSendType" SG_ 1201 CMSM_DisplayStandard 0;
BA_ "GenSigSendType" SG_ 1252 TotalOdometer_km_OBD 0;
BA_ "GenSigSendType" SG_ 1252 DisplayVehicleSpeed 0;
BA_ "GenSigSendType" SG_ 1252 ICC_BackLightLevel 0;
BA_ "GenSigSendType" SG_ 1252 TotalOdometer_km_OBDValidData 0;
BA_ "GenSigSendType" SG_ 1252 ICC_TotalodometerbackupEnable 0;
BA_ "GenSigSendType" SG_ 1322 STAT_AMPAlarm 2;
BA_ "GenSigSendType" SG_ 1176 Fusa_498_6 5;
BA_ "GenSigSendType" SG_ 1176 Fusa_498_5 5;
BA_ "GenSigSendType" SG_ 1176 Fusa_498_4 5;
BA_ "GenSigSendType" SG_ 1176 Fusa_498_3 5;
BA_ "GenSigSendType" SG_ 1176 Fusa_498_2 5;
BA_ "GenSigSendType" SG_ 1176 Fusa_498_1 5;
BA_ "GenSigSendType" SG_ 1176 ICC_CH_3_CRC 0;
BA_ "E2EDataId" SG_ 1176 ICC_CH_3_CRC 72;
BA_ "E2EProfile" SG_ 1176 ICC_CH_3_CRC "P01";
BA_ "E2EDataLength" SG_ 1176 ICC_CH_3_CRC 64;
BA_ "GenSigSendType" SG_ 1176 ICC_CH_3_RollgCntr 0;
BA_ "E2EDataId" SG_ 1176 ICC_CH_3_RollgCntr 72;
BA_ "E2EProfile" SG_ 1176 ICC_CH_3_RollgCntr "P01";
BA_ "E2EDataLength" SG_ 1176 ICC_CH_3_RollgCntr 64;
BA_ "GenSigSendType" SG_ 1176 ICC_ASUAssistPassSet 5;
BA_ "E2EDataId" SG_ 1176 ICC_ASUAssistPassSet 72;
BA_ "E2EProfile" SG_ 1176 ICC_ASUAssistPassSet "P01";
BA_ "E2EDataLength" SG_ 1176 ICC_ASUAssistPassSet 64;
BA_ "GenSigSendType" SG_ 1176 IHU_AutHldSet 5;
BA_ "E2EDataId" SG_ 1176 IHU_AutHldSet 72;
BA_ "E2EProfile" SG_ 1176 IHU_AutHldSet "P01";
BA_ "E2EDataLength" SG_ 1176 IHU_AutHldSet 64;
BA_ "GenSigSendType" SG_ 1176 ICC_AutoEasyEntrySet 5;
BA_ "E2EDataId" SG_ 1176 ICC_AutoEasyEntrySet 72;
BA_ "E2EProfile" SG_ 1176 ICC_AutoEasyEntrySet "P01";
BA_ "E2EDataLength" SG_ 1176 ICC_AutoEasyEntrySet 64;
BA_ "GenSigSendType" SG_ 1176 ICC_ManualEasyOutSw 5;
BA_ "E2EDataId" SG_ 1176 ICC_ManualEasyOutSw 72;
BA_ "E2EProfile" SG_ 1176 ICC_ManualEasyOutSw "P01";
BA_ "E2EDataLength" SG_ 1176 ICC_ManualEasyOutSw 64;
BA_ "GenSigSendType" SG_ 1176 ICC_ASCMaintainModeReq 5;
BA_ "E2EDataId" SG_ 1176 ICC_ASCMaintainModeReq 72;
BA_ "E2EProfile" SG_ 1176 ICC_ASCMaintainModeReq "P01";
BA_ "E2EDataLength" SG_ 1176 ICC_ASCMaintainModeReq 64;
BA_ "GenSigSendType" SG_ 1176 ICC_PABSetCmd 5;
BA_ "E2EDataId" SG_ 1176 ICC_PABSetCmd 72;
BA_ "E2EProfile" SG_ 1176 ICC_PABSetCmd "P01";
BA_ "E2EDataLength" SG_ 1176 ICC_PABSetCmd 64;
BA_ "GenSigSendType" SG_ 1176 ICC_EPBSetCmd 5;
BA_ "E2EDataId" SG_ 1176 ICC_EPBSetCmd 72;
BA_ "E2EProfile" SG_ 1176 ICC_EPBSetCmd "P01";
BA_ "E2EDataLength" SG_ 1176 ICC_EPBSetCmd 64;
BA_ "GenSigSendType" SG_ 1176 ICC_ASUMemoryPosition 5;
BA_ "E2EDataId" SG_ 1176 ICC_ASUMemoryPosition 72;
BA_ "E2EProfile" SG_ 1176 ICC_ASUMemoryPosition "P01";
BA_ "E2EDataLength" SG_ 1176 ICC_ASUMemoryPosition 64;
BA_ "GenSigSendType" SG_ 1176 ICC_ASUEasyLoadingSet 5;
BA_ "E2EDataId" SG_ 1176 ICC_ASUEasyLoadingSet 72;
BA_ "E2EProfile" SG_ 1176 ICC_ASUEasyLoadingSet "P01";
BA_ "E2EDataLength" SG_ 1176 ICC_ASUEasyLoadingSet 64;
BA_ "GenSigSendType" SG_ 1176 Set_CSTFunctionSts 5;
BA_ "E2EDataId" SG_ 1176 Set_CSTFunctionSts 72;
BA_ "E2EProfile" SG_ 1176 Set_CSTFunctionSts "P01";
BA_ "E2EDataLength" SG_ 1176 Set_CSTFunctionSts 64;
BA_ "GenSigSendType" SG_ 1176 ICC_ASURearaxlewithTaildoor 5;
BA_ "E2EDataId" SG_ 1176 ICC_ASURearaxlewithTaildoor 72;
BA_ "E2EProfile" SG_ 1176 ICC_ASURearaxlewithTaildoor "P01";
BA_ "E2EDataLength" SG_ 1176 ICC_ASURearaxlewithTaildoor 64;
BA_ "GenSigSendType" SG_ 1176 CST_SensitivityReq 5;
BA_ "E2EDataId" SG_ 1176 CST_SensitivityReq 72;
BA_ "E2EProfile" SG_ 1176 CST_SensitivityReq "P01";
BA_ "E2EDataLength" SG_ 1176 CST_SensitivityReq 64;
BA_ "GenSigSendType" SG_ 1176 TIHU_SetHDCOnOff 5;
BA_ "E2EDataId" SG_ 1176 TIHU_SetHDCOnOff 72;
BA_ "E2EProfile" SG_ 1176 TIHU_SetHDCOnOff "P01";
BA_ "E2EDataLength" SG_ 1176 TIHU_SetHDCOnOff 64;
BA_ "GenSigSendType" SG_ 1176 Set_ESPFunctionSts 5;
BA_ "E2EDataId" SG_ 1176 Set_ESPFunctionSts 72;
BA_ "E2EProfile" SG_ 1176 Set_ESPFunctionSts "P01";
BA_ "E2EDataLength" SG_ 1176 Set_ESPFunctionSts 64;
BA_ "GenSigSendType" SG_ 1176 ICC_ASUPreviewCont 5;
BA_ "E2EDataId" SG_ 1176 ICC_ASUPreviewCont 72;
BA_ "E2EProfile" SG_ 1176 ICC_ASUPreviewCont "P01";
BA_ "E2EDataLength" SG_ 1176 ICC_ASUPreviewCont 64;
BA_ "GenSigSendType" SG_ 1176 ICC_ASUHighwayModAdjust 5;
BA_ "E2EDataId" SG_ 1176 ICC_ASUHighwayModAdjust 72;
BA_ "E2EProfile" SG_ 1176 ICC_ASUHighwayModAdjust "P01";
BA_ "E2EDataLength" SG_ 1176 ICC_ASUHighwayModAdjust 64;
BA_ "GenSigSendType" SG_ 1176 ICC_ASUMapAdjust 5;
BA_ "E2EDataId" SG_ 1176 ICC_ASUMapAdjust 72;
BA_ "E2EProfile" SG_ 1176 ICC_ASUMapAdjust "P01";
BA_ "E2EDataLength" SG_ 1176 ICC_ASUMapAdjust 64;
BA_ "GenSigSendType" SG_ 1239 ICC_DisChg 5;
BA_ "GenSigSendType" SG_ 1239 ICC_StpDisChgReq 0;
BA_ "GenSigSendType" SG_ 1239 ICC_RegenLevel 5;
BA_ "GenSigSendType" SG_ 1239 ICC_ELockReq 0;
BA_ "GenSigSendType" SG_ 1239 ICC_DisChgPercent 0;
BA_ "GenSigInvalidValue" SG_ 1239 ICC_DisChgPercent 127;
BA_ "GenSigSendType" SG_ 1239 ICC_ChgSocSet 5;
BA_ "GenSigInvalidValue" SG_ 1239 ICC_ChgSocSet 255;
BA_ "GenSigStartValue" SG_ 1239 ICC_ChgSocSet 255;
BA_ "GenSigSendType" SG_ 1239 ICC_CampMode 5;
BA_ "GenSigSendType" SG_ 1239 ICC_SftWarning 5;
BA_ "GenSigSendType" SG_ 1239 ICC_TowingMode 5;
BA_ "GenSigSendType" SG_ 1239 ICC_StopMode 5;
BA_ "GenSigSendType" SG_ 1239 ICC_EPedalMode 5;
BA_ "GenSigSendType" SG_ 1246 ICC_WindowKeySts 5;
BA_ "GenSigSendType" SG_ 1246 ICC_FaceKeySts 5;
BA_ "GenSigSendType" SG_ 1246 ICC_FootKeySts 5;
BA_ "GenSigSendType" SG_ 1246 BltCallSts 5;
BA_ "GenSigSendType" SG_ 1246 ICC_DockWinspSts 5;
BA_ "GenSigSendType" SG_ 1246 ICC_DockTSts 5;
BA_ "GenSigSendType" SG_ 1246 ICC_ACFastCool 5;
BA_ "GenSigSendType" SG_ 1246 ICC_ACFastHeat 5;
BA_ "GenSigSendType" SG_ 1246 ICC_SetCLMOn 5;
BA_ "GenSigSendType" SG_ 1246 ICC_SetAutoKeySts 5;
BA_ "GenSigSendType" SG_ 1246 ICC_SetFrontDeforestSts 5;
BA_ "GenSigSendType" SG_ 1246 ICC_SetCirculationModeKeySts 5;
BA_ "GenSigSendType" SG_ 1246 ICC_ZoneSelectionKeySts 5;
BA_ "GenSigSendType" SG_ 1246 ICC_ResetFilter 5;
BA_ "GenSigSendType" SG_ 1246 ICC_AUTODefrostOnKeySts 5;
BA_ "GenSigSendType" SG_ 1246 ICC_AutoAirClean 5;
BA_ "GenSigSendType" SG_ 1246 ICC_KeepWarm 0;
BA_ "GenSigSendType" SG_ 1246 ICC_BlowSpeedLevelKeySts 4;
BA_ "GenSigSendType" SG_ 1246 ICC_SetACRequestKeySts 5;
BA_ "GenSigSendType" SG_ 1246 ICC_DSwingSet 5;
BA_ "GenSigSendType" SG_ 1246 ICC_PSwingSet 5;
BA_ "GenSigSendType" SG_ 1246 ICC_AUTODefLevelSet 5;
BA_ "GenSigSendType" SG_ 1246 ICC_SetTemperature_L_C 5;
BA_ "GenSigInvalidValue" SG_ 1246 ICC_SetTemperature_L_C 31;
BA_ "GenSigStartValue" SG_ 1246 ICC_SetTemperature_L_C 31;
BA_ "GenSigSendType" SG_ 1246 ICC_SetTemperature_R_C 5;
BA_ "GenSigInvalidValue" SG_ 1246 ICC_SetTemperature_R_C 31;
BA_ "GenSigStartValue" SG_ 1246 ICC_SetTemperature_R_C 31;
BA_ "GenSigSendType" SG_ 1246 ICC_DLSwingUpDwn 5;
BA_ "GenSigInvalidValue" SG_ 1246 ICC_DLSwingUpDwn 127;
BA_ "GenSigSendType" SG_ 1246 ICC_DLSwingLeRi 5;
BA_ "GenSigInvalidValue" SG_ 1246 ICC_DLSwingLeRi 127;
BA_ "GenSigSendType" SG_ 1246 ICC_DRSwingUpDwn 5;
BA_ "GenSigInvalidValue" SG_ 1246 ICC_DRSwingUpDwn 127;
BA_ "GenSigSendType" SG_ 1246 ICC_DRSwingLeRi 5;
BA_ "GenSigInvalidValue" SG_ 1246 ICC_DRSwingLeRi 127;
BA_ "GenSigSendType" SG_ 1246 ICC_PLSwingUpDwn 5;
BA_ "GenSigInvalidValue" SG_ 1246 ICC_PLSwingUpDwn 127;
BA_ "GenSigSendType" SG_ 1246 ICC_PLSwingLeRi 5;
BA_ "GenSigInvalidValue" SG_ 1246 ICC_PLSwingLeRi 127;
BA_ "GenSigSendType" SG_ 1246 ICC_PRSwingUpDwn 5;
BA_ "GenSigInvalidValue" SG_ 1246 ICC_PRSwingUpDwn 127;
BA_ "GenSigSendType" SG_ 1246 ICC_PRSwingLeRi 5;
BA_ "GenSigInvalidValue" SG_ 1246 ICC_PRSwingLeRi 127;
BA_ "GenSigSendType" SG_ 1246 ICC_DCSwingLeRi 5;
BA_ "GenSigInvalidValue" SG_ 1246 ICC_DCSwingLeRi 127;
BA_ "GenSigSendType" SG_ 1246 ICC_NetWorkTemperature 0;
BA_ "GenSigInvalidValue" SG_ 1246 ICC_NetWorkTemperature 255;
BA_ "GenSigStartValue" SG_ 1246 ICC_NetWorkTemperature 254;
BA_ "GenSigSendType" SG_ 1246 ICC_NetWorkHumidity 0;
BA_ "GenSigInvalidValue" SG_ 1246 ICC_NetWorkHumidity 255;
BA_ "GenSigStartValue" SG_ 1246 ICC_NetWorkHumidity 1;
BA_ "GenSigSendType" SG_ 1246 ICC_DLOnOff 5;
BA_ "GenSigSendType" SG_ 1246 ICC_DROnOff 5;
BA_ "GenSigSendType" SG_ 1246 ICC_PLOnOff 5;
BA_ "GenSigSendType" SG_ 1246 ICC_PROnOff 5;
BA_ "GenSigSendType" SG_ 1246 ICC_DCOnOff 5;
BA_ "GenSigSendType" SG_ 1246 ICC_LoveRemind 5;
BA_ "GenSigSendType" SG_ 1246 ICC_InteCleanCar 5;
BA_ "GenSigSendType" SG_ 1246 ICC_KeepWarmMemory 5;
BA_ "GenSigSendType" SG_ 1250 ICC_CCMReq_4E2h 5;
BA_ "GenSigSendType" SG_ 1250 ICC_CCMSet 5;
BA_ "GenSigSendType" SG_ 1250 ICC_AutoLightSW 0;
BA_ "GenSigSendType" SG_ 1250 ICC_CleanMode 5;
BA_ "GenSigSendType" SG_ 1250 ICC_1_OTASts 0;
BA_ "GenSigSendType" SG_ 1250 ICC_1_OTAHV_Req 0;
BA_ "GenSigSendType" SG_ 1250 ICC_1_OTAPwrMngt 0;
BA_ "GenSigSendType" SG_ 1250 ICC_DriveModeSwitch 5;
BA_ "GenSigSendType" SG_ 1250 ICC_PropulsionMode 5;
BA_ "GenSigSendType" SG_ 1250 ICC_SteeringMode 5;
BA_ "GenSigSendType" SG_ 1250 ICC_SuspensionHeight 5;
BA_ "GenSigSendType" SG_ 1250 ICC_SuspensionDamping 5;
BA_ "GenSigSendType" SG_ 1250 ICC_AirconditionMode 5;
BA_ "GenSigSendType" SG_ 1250 ICC_BrakePedalFeelMode 5;
BA_ "GenSigSendType" SG_ 1250 ICC_SentinelHV_Req 0;
BA_ "GenSigSendType" SG_ 1250 ICC_PetModeHV_Req 0;
BA_ "GenSigSendType" SG_ 1250 ICC_SelfClearing 5;
BA_ "GenSigSendType" SG_ 1254 ICC_WelcomeOpenSet 5;
BA_ "GenSigSendType" SG_ 1254 ICC_WALOpenSet 5;
BA_ "GenSigSendType" SG_ 1254 ICC_EasytrunkSet 5;
BA_ "GenSigSendType" SG_ 1254 ICC_UIROpenSet 5;
BA_ "GenSigSendType" SG_ 1254 ICC_BeanIDReq 5;
BA_ "GenSigSendType" SG_ 1254 ICC_CWCWorkingStsSet 5;
BA_ "GenSigInvalidValue" SG_ 1254 ICC_CWCWorkingStsSet 3;
BA_ "GenSigStartValue" SG_ 1254 ICC_CWCWorkingStsSet 3;
BA_ "GenSigSendType" SG_ 1254 ICC_CWCPhoneforgottenFunStsSet 5;
BA_ "GenSigInvalidValue" SG_ 1254 ICC_CWCPhoneforgottenFunStsSet 3;
BA_ "GenSigStartValue" SG_ 1254 ICC_CWCPhoneforgottenFunStsSet 3;
BA_ "GenSigSendType" SG_ 1254 ICC_RCWCWorkingStsSet 5;
BA_ "GenSigInvalidValue" SG_ 1254 ICC_RCWCWorkingStsSet 3;
BA_ "GenSigStartValue" SG_ 1254 ICC_RCWCWorkingStsSet 3;
BA_ "GenSigSendType" SG_ 1254 ICC_RCWCPhoneforgottenFunStsSet 5;
BA_ "GenSigInvalidValue" SG_ 1254 ICC_RCWCPhoneforgottenFunStsSet 3;
BA_ "GenSigStartValue" SG_ 1254 ICC_RCWCPhoneforgottenFunStsSet 3;
BA_ "GenSigSendType" SG_ 1296 CurrentTimeYear 0;
BA_ "GenSigSendType" SG_ 1296 CurrentTimeMonth 0;
BA_ "GenSigStartValue" SG_ 1296 CurrentTimeMonth 1;
BA_ "GenSigSendType" SG_ 1296 CurrentTimeDay 0;
BA_ "GenSigStartValue" SG_ 1296 CurrentTimeDay 1;
BA_ "GenSigSendType" SG_ 1296 CurrentTimeHour 0;
BA_ "GenSigSendType" SG_ 1296 CurrentTimeMinute 0;
BA_ "GenSigSendType" SG_ 1296 CurrentTimeSecond 0;
BA_ "GenSigSendType" SG_ 1447 CurrentTimeYear_UTC 0;
BA_ "GenSigSendType" SG_ 1447 CurrentTimeMonth_UTC 0;
BA_ "GenSigStartValue" SG_ 1447 CurrentTimeMonth_UTC 1;
BA_ "GenSigSendType" SG_ 1447 CurrentTimeDay_UTC 0;
BA_ "GenSigStartValue" SG_ 1447 CurrentTimeDay_UTC 1;
BA_ "GenSigSendType" SG_ 1447 CurrentTimeHour_UTC 0;
BA_ "GenSigSendType" SG_ 1447 CurrentTimeMinute_UTC 0;
BA_ "GenSigSendType" SG_ 1447 CurrentTimeSecond_UTC 0;
BA_ "GenSigSendType" SG_ 1100 Set_AMPNaviVolume 5;
BA_ "GenSigSendType" SG_ 1100 Set_AMPVRVolume 5;
BA_ "GenSigSendType" SG_ 1100 Set_AMPKeyTone 5;
BA_ "GenSigSendType" SG_ 1100 Set_AMPMediaVolume 5;
BA_ "GenSigSendType" SG_ 1100 Set_AMPPhoneVolume 5;
BA_ "GenSigSendType" SG_ 1100 Set_AMPSoundFocus 5;
BA_ "GenSigSendType" SG_ 1100 Set_AMPSoundEffect 5;
BA_ "GenSigSendType" SG_ 1100 Set_AMPSoundEffectBass 5;
BA_ "GenSigSendType" SG_ 1100 Set_AMPSoundEffectMidrange 5;
BA_ "GenSigSendType" SG_ 1100 Set_AMPSoundEffectTreble 5;
BA_ "GenSigSendType" SG_ 1100 Set_AMPSoundFieldBalance 5;
BA_ "GenSigSendType" SG_ 1100 Set_AMPSoundFieldFader 5;
BA_ "GenSigSendType" SG_ 1100 Set_Headrest_Mode 5;
BA_ "GenSigSendType" SG_ 1100 Set_SurndFnOnOff 5;
BA_ "GenSigSendType" SG_ 1100 Set_VirtualSbwfrOnOff 5;
BA_ "GenSigSendType" SG_ 1119 Set_AMPMediaDuck 5;
BA_ "GenSigSendType" SG_ 1119 Set_AMPSpeedVolume 5;
BA_ "GenSigSendType" SG_ 1119 Set_AMPMute 5;
BA_ "GenSigSendType" SG_ 1119 REQ_AMPA2BMediaSound 5;
BA_ "GenSigSendType" SG_ 1119 REQ_AMPA2BNaviSound 5;
BA_ "GenSigSendType" SG_ 1119 REQ_AMPA2BVRSound 5;
BA_ "GenSigSendType" SG_ 1119 REQ_AMPA2BTTSSound 5;
BA_ "GenSigSendType" SG_ 1119 REQ_AMPA2BKeyTone 5;
BA_ "GenSigSendType" SG_ 1119 Set_AMPRestoreDefaults 5;
BA_ "GenSigSendType" SG_ 1119 Set_AMPAlarmVolume 5;
BA_ "GenSigSendType" SG_ 1119 REQ_AMPA2BPhoneSound 5;
BA_ "GenSigSendType" SG_ 1119 Set_AMPSoundEffectMegaBass 5;
BA_ "GenSigSendType" SG_ 1119 Set_AMPSoundEffectMidBass 5;
BA_ "GenSigSendType" SG_ 1119 Set_AMPSoundEffectMidTreble 5;
BA_ "GenSigSendType" SG_ 1119 Set_AMPBackgroundVolume 5;
BA_ "GenSigSendType" SG_ 1119 Set_AMPSoundBypass 5;
BA_ "GenSigSendType" SG_ 1119 Set_AMPA2BConfig 5;
BA_ "GenSigSendType" SG_ 1150 Fusa_47E_3 5;
BA_ "GenSigSendType" SG_ 1150 Fusa_47E_2 5;
BA_ "GenSigSendType" SG_ 1150 Fusa_47E_1 5;
BA_ "GenSigSendType" SG_ 1150 ICC_BD_11_CRC 0;
BA_ "E2EDataId" SG_ 1150 ICC_BD_11_CRC 158;
BA_ "E2EProfile" SG_ 1150 ICC_BD_11_CRC "P01";
BA_ "E2EDataLength" SG_ 1150 ICC_BD_11_CRC 64;
BA_ "GenSigSendType" SG_ 1150 ICC_BD_11_RollgCntr 0;
BA_ "E2EDataId" SG_ 1150 ICC_BD_11_RollgCntr 158;
BA_ "E2EProfile" SG_ 1150 ICC_BD_11_RollgCntr "P01";
BA_ "E2EDataLength" SG_ 1150 ICC_BD_11_RollgCntr 64;
BA_ "GenSigSendType" SG_ 1150 ICC_CPDDelaySwitchSet 5;
BA_ "E2EDataId" SG_ 1150 ICC_CPDDelaySwitchSet 158;
BA_ "E2EProfile" SG_ 1150 ICC_CPDDelaySwitchSet "P01";
BA_ "E2EDataLength" SG_ 1150 ICC_CPDDelaySwitchSet 64;
BA_ "GenSigSendType" SG_ 1150 ICC_PPMIDBSRBPASet 5;
BA_ "E2EDataId" SG_ 1150 ICC_PPMIDBSRBPASet 158;
BA_ "E2EProfile" SG_ 1150 ICC_PPMIDBSRBPASet "P01";
BA_ "E2EDataLength" SG_ 1150 ICC_PPMIDBSRBPASet 64;
BA_ "GenSigSendType" SG_ 1150 ICC_PPMIDHwSet 5;
BA_ "E2EDataId" SG_ 1150 ICC_PPMIDHwSet 158;
BA_ "E2EProfile" SG_ 1150 ICC_PPMIDHwSet "P01";
BA_ "E2EDataLength" SG_ 1150 ICC_PPMIDHwSet 64;
BA_ "GRC_Sig_ASIL" SG_ 1150 ICC_DriveDrosinessLevel 2;
BA_ "GenSigSendType" SG_ 1150 ICC_DriveDrosinessLevel 0;
BA_ "E2EDataId" SG_ 1150 ICC_DriveDrosinessLevel 158;
BA_ "E2EProfile" SG_ 1150 ICC_DriveDrosinessLevel "P01";
BA_ "E2EDataLength" SG_ 1150 ICC_DriveDrosinessLevel 64;
BA_ "GenSigSendType" SG_ 1150 ICC_FLDoorButton 5;
BA_ "E2EDataId" SG_ 1150 ICC_FLDoorButton 158;
BA_ "E2EProfile" SG_ 1150 ICC_FLDoorButton "P01";
BA_ "E2EDataLength" SG_ 1150 ICC_FLDoorButton 64;
BA_ "GenSigSendType" SG_ 1150 ICC_FRDoorButton 5;
BA_ "E2EDataId" SG_ 1150 ICC_FRDoorButton 158;
BA_ "E2EProfile" SG_ 1150 ICC_FRDoorButton "P01";
BA_ "E2EDataLength" SG_ 1150 ICC_FRDoorButton 64;
BA_ "GenSigSendType" SG_ 1150 ICC_RRDoorButton 5;
BA_ "E2EDataId" SG_ 1150 ICC_RRDoorButton 158;
BA_ "E2EProfile" SG_ 1150 ICC_RRDoorButton "P01";
BA_ "E2EDataLength" SG_ 1150 ICC_RRDoorButton 64;
BA_ "GenSigSendType" SG_ 1150 ICC_RLDoorButton 5;
BA_ "E2EDataId" SG_ 1150 ICC_RLDoorButton 158;
BA_ "E2EProfile" SG_ 1150 ICC_RLDoorButton "P01";
BA_ "E2EDataLength" SG_ 1150 ICC_RLDoorButton 64;
BA_ "GenSigSendType" SG_ 1150 ICC_CloseAllDoors 5;
BA_ "E2EDataId" SG_ 1150 ICC_CloseAllDoors 158;
BA_ "E2EProfile" SG_ 1150 ICC_CloseAllDoors "P01";
BA_ "E2EDataLength" SG_ 1150 ICC_CloseAllDoors 64;
BA_ "GenSigSendType" SG_ 1150 ICC_DoorRemoteKeyControlEnable 5;
BA_ "E2EDataId" SG_ 1150 ICC_DoorRemoteKeyControlEnable 158;
BA_ "E2EProfile" SG_ 1150 ICC_DoorRemoteKeyControlEnable "P01";
BA_ "E2EDataLength" SG_ 1150 ICC_DoorRemoteKeyControlEnable 64;
BA_ "GenSigSendType" SG_ 1150 ICC_SetOpenAngle 5;
BA_ "E2EDataId" SG_ 1150 ICC_SetOpenAngle 158;
BA_ "E2EProfile" SG_ 1150 ICC_SetOpenAngle "P01";
BA_ "E2EDataLength" SG_ 1150 ICC_SetOpenAngle 64;
BA_ "GenSigSendType" SG_ 1150 ICC_CPDSwitchSet 5;
BA_ "E2EDataId" SG_ 1150 ICC_CPDSwitchSet 158;
BA_ "E2EProfile" SG_ 1150 ICC_CPDSwitchSet "P01";
BA_ "E2EDataLength" SG_ 1150 ICC_CPDSwitchSet 64;
BA_ "GenSigSendType" SG_ 1150 ICC_FrontDoorPowerMode 5;
BA_ "E2EDataId" SG_ 1150 ICC_FrontDoorPowerMode 158;
BA_ "E2EProfile" SG_ 1150 ICC_FrontDoorPowerMode "P01";
BA_ "E2EDataLength" SG_ 1150 ICC_FrontDoorPowerMode 64;
BA_ "GenSigSendType" SG_ 1150 ICC_RearDoorPowerMode 5;
BA_ "E2EDataId" SG_ 1150 ICC_RearDoorPowerMode 158;
BA_ "E2EProfile" SG_ 1150 ICC_RearDoorPowerMode "P01";
BA_ "E2EDataLength" SG_ 1150 ICC_RearDoorPowerMode 64;
BA_ "GenSigSendType" SG_ 1150 ICC_PedalCloseDriverDoorEnable 5;
BA_ "E2EDataId" SG_ 1150 ICC_PedalCloseDriverDoorEnable 158;
BA_ "E2EProfile" SG_ 1150 ICC_PedalCloseDriverDoorEnable "P01";
BA_ "E2EDataLength" SG_ 1150 ICC_PedalCloseDriverDoorEnable 64;
BA_ "GenSigSendType" SG_ 1150 RR_Door_RearScreen_Control 5;
BA_ "E2EDataId" SG_ 1150 RR_Door_RearScreen_Control 158;
BA_ "E2EProfile" SG_ 1150 RR_Door_RearScreen_Control "P01";
BA_ "E2EDataLength" SG_ 1150 RR_Door_RearScreen_Control 64;
BA_ "GenSigSendType" SG_ 1150 ICC_RearDoorVoiceControlEnable 5;
BA_ "E2EDataId" SG_ 1150 ICC_RearDoorVoiceControlEnable 158;
BA_ "E2EProfile" SG_ 1150 ICC_RearDoorVoiceControlEnable "P01";
BA_ "E2EDataLength" SG_ 1150 ICC_RearDoorVoiceControlEnable 64;
BA_ "GenSigSendType" SG_ 1150 ICC_FLVoiceControl 5;
BA_ "E2EDataId" SG_ 1150 ICC_FLVoiceControl 158;
BA_ "E2EProfile" SG_ 1150 ICC_FLVoiceControl "P01";
BA_ "E2EDataLength" SG_ 1150 ICC_FLVoiceControl 64;
BA_ "GenSigSendType" SG_ 1150 ICC_FRVoiceControl 5;
BA_ "E2EDataId" SG_ 1150 ICC_FRVoiceControl 158;
BA_ "E2EProfile" SG_ 1150 ICC_FRVoiceControl "P01";
BA_ "E2EDataLength" SG_ 1150 ICC_FRVoiceControl 64;
BA_ "GenSigSendType" SG_ 1150 ICC_RRVoiceControl 5;
BA_ "E2EDataId" SG_ 1150 ICC_RRVoiceControl 158;
BA_ "E2EProfile" SG_ 1150 ICC_RRVoiceControl "P01";
BA_ "E2EDataLength" SG_ 1150 ICC_RRVoiceControl 64;
BA_ "GenSigSendType" SG_ 1150 ICC_RLVoiceControl 5;
BA_ "E2EDataId" SG_ 1150 ICC_RLVoiceControl 158;
BA_ "E2EProfile" SG_ 1150 ICC_RLVoiceControl "P01";
BA_ "E2EDataLength" SG_ 1150 ICC_RLVoiceControl 64;
BA_ "GenSigSendType" SG_ 1150 RL_Door_RearScreen_Control 5;
BA_ "E2EDataId" SG_ 1150 RL_Door_RearScreen_Control 158;
BA_ "E2EProfile" SG_ 1150 RL_Door_RearScreen_Control "P01";
BA_ "E2EDataLength" SG_ 1150 RL_Door_RearScreen_Control 64;
BA_ "GenSigSendType" SG_ 917 ADBenable 0;
BA_ "GenSigSendType" SG_ 917 RandomMusicShowCMD 0;
BA_ "GenSigSendType" SG_ 917 DIYMusicShowmod 0;
BA_ "GenSigSendType" SG_ 917 LiShowMod 0;
BA_ "GenSigSendType" SG_ 917 MusicLoudness_55HZ 0;
BA_ "GenSigSendType" SG_ 917 MusicLoudness_123HZ 0;
BA_ "GenSigSendType" SG_ 917 MusicLoudness_262HZ 0;
BA_ "GenSigSendType" SG_ 917 MusicLoudness_440HZ 0;
BA_ "GenSigSendType" SG_ 917 MusicLoudness_587HZ 0;
BA_ "GenSigSendType" SG_ 917 MusicLoudness_784HZ 0;
BA_ "GenSigSendType" SG_ 917 MusicLoudness_1318HZ 0;
BA_ "GenSigSendType" SG_ 917 MusicLoudness_2794HZ 0;
BA_ "GenSigSendType" SG_ 917 MusicLoudness_6272HZ 0;
BA_ "GenSigSendType" SG_ 917 ISDShowCMD 0;
BA_ "GenSigSendType" SG_ 917 ISDShowMode 0;
BA_ "GenSigSendType" SG_ 1273 FaceID 5;
BA_ "GenSigSendType" SG_ 1157 Fusa_485_2 5;
BA_ "GenSigSendType" SG_ 1157 Fusa_485_1 5;
BA_ "GenSigSendType" SG_ 1157 ICC_DA_15_CRC 0;
BA_ "E2EDataId" SG_ 1157 ICC_DA_15_CRC 157;
BA_ "E2EProfile" SG_ 1157 ICC_DA_15_CRC "P01";
BA_ "E2EDataLength" SG_ 1157 ICC_DA_15_CRC 64;
BA_ "GenSigSendType" SG_ 1157 ICC_DA_15_RollgCntr 0;
BA_ "E2EDataId" SG_ 1157 ICC_DA_15_RollgCntr 157;
BA_ "E2EProfile" SG_ 1157 ICC_DA_15_RollgCntr "P01";
BA_ "E2EDataLength" SG_ 1157 ICC_DA_15_RollgCntr 64;
BA_ "GenSigSendType" SG_ 1157 ICC_DA_15_Resd 0;
BA_ "E2EDataId" SG_ 1157 ICC_DA_15_Resd 157;
BA_ "E2EProfile" SG_ 1157 ICC_DA_15_Resd "P01";
BA_ "E2EDataLength" SG_ 1157 ICC_DA_15_Resd 64;
BA_ "GenSigSendType" SG_ 1157 ICC_DA_15_BSDLCWSettingSt 5;
BA_ "E2EDataId" SG_ 1157 ICC_DA_15_BSDLCWSettingSt 157;
BA_ "E2EProfile" SG_ 1157 ICC_DA_15_BSDLCWSettingSt "P01";
BA_ "E2EDataLength" SG_ 1157 ICC_DA_15_BSDLCWSettingSt 64;
BA_ "GenSigSendType" SG_ 1157 ICC_DA_15_DOWSettingSt 5;
BA_ "E2EDataId" SG_ 1157 ICC_DA_15_DOWSettingSt 157;
BA_ "E2EProfile" SG_ 1157 ICC_DA_15_DOWSettingSt "P01";
BA_ "E2EDataLength" SG_ 1157 ICC_DA_15_DOWSettingSt 64;
BA_ "GenSigSendType" SG_ 1157 ICC_DA_15_RCWSettingSt 5;
BA_ "E2EDataId" SG_ 1157 ICC_DA_15_RCWSettingSt 157;
BA_ "E2EProfile" SG_ 1157 ICC_DA_15_RCWSettingSt "P01";
BA_ "E2EDataLength" SG_ 1157 ICC_DA_15_RCWSettingSt 64;
BA_ "GenSigSendType" SG_ 1157 ICC_DA_15_RCTARCTBWarnType 5;
BA_ "GenSigStartValue" SG_ 1157 ICC_DA_15_RCTARCTBWarnType 3;
BA_ "E2EDataId" SG_ 1157 ICC_DA_15_RCTARCTBWarnType 157;
BA_ "E2EProfile" SG_ 1157 ICC_DA_15_RCTARCTBWarnType "P01";
BA_ "E2EDataLength" SG_ 1157 ICC_DA_15_RCTARCTBWarnType 64;
BA_ "GenSigSendType" SG_ 1157 ICC_DA_15_FCTAFCTBWarnType 5;
BA_ "GenSigStartValue" SG_ 1157 ICC_DA_15_FCTAFCTBWarnType 3;
BA_ "E2EDataId" SG_ 1157 ICC_DA_15_FCTAFCTBWarnType 157;
BA_ "E2EProfile" SG_ 1157 ICC_DA_15_FCTAFCTBWarnType "P01";
BA_ "E2EDataLength" SG_ 1157 ICC_DA_15_FCTAFCTBWarnType 64;
BA_ "GenSigSendType" SG_ 1157 ICC_DA_15_FrontPDCMuteSet 0;
BA_ "E2EDataId" SG_ 1157 ICC_DA_15_FrontPDCMuteSet 157;
BA_ "E2EProfile" SG_ 1157 ICC_DA_15_FrontPDCMuteSet "P01";
BA_ "E2EDataLength" SG_ 1157 ICC_DA_15_FrontPDCMuteSet 64;
BA_ "GenSigSendType" SG_ 1157 ICC_DA_15_FKPMuteSet 0;
BA_ "E2EDataId" SG_ 1157 ICC_DA_15_FKPMuteSet 157;
BA_ "E2EProfile" SG_ 1157 ICC_DA_15_FKPMuteSet "P01";
BA_ "E2EDataLength" SG_ 1157 ICC_DA_15_FKPMuteSet 64;
BA_ "GenSigSendType" SG_ 1157 ICC_DA_15_ExtremeEnergySaveMode 0;
BA_ "E2EDataId" SG_ 1157 ICC_DA_15_ExtremeEnergySaveMode 157;
BA_ "E2EProfile" SG_ 1157 ICC_DA_15_ExtremeEnergySaveMode "P01";
BA_ "E2EDataLength" SG_ 1157 ICC_DA_15_ExtremeEnergySaveMode 64;
BA_ "GRC_Sig_ASIL" SG_ 1157 Driver_EyeOnRoad 3;
BA_ "GenSigSendType" SG_ 1157 Driver_EyeOnRoad 0;
BA_ "E2EDataId" SG_ 1157 Driver_EyeOnRoad 157;
BA_ "E2EProfile" SG_ 1157 Driver_EyeOnRoad "P01";
BA_ "E2EDataLength" SG_ 1157 Driver_EyeOnRoad 64;
BA_ "GRC_Sig_ASIL" SG_ 1157 Dms_Status 3;
BA_ "GenSigSendType" SG_ 1157 Dms_Status 0;
BA_ "E2EDataId" SG_ 1157 Dms_Status 157;
BA_ "E2EProfile" SG_ 1157 Dms_Status "P01";
BA_ "E2EDataLength" SG_ 1157 Dms_Status 64;
BA_ "GenSigSendType" SG_ 1157 Driver_AbnormalBehavior 0;
BA_ "E2EDataId" SG_ 1157 Driver_AbnormalBehavior 157;
BA_ "E2EProfile" SG_ 1157 Driver_AbnormalBehavior "P01";
BA_ "E2EDataLength" SG_ 1157 Driver_AbnormalBehavior 64;
BA_ "GenSigSendType" SG_ 1157 Driver_GazeRegion 0;
BA_ "E2EDataId" SG_ 1157 Driver_GazeRegion 157;
BA_ "E2EProfile" SG_ 1157 Driver_GazeRegion "P01";
BA_ "E2EDataLength" SG_ 1157 Driver_GazeRegion 64;
BA_ "GRC_Sig_ASIL" SG_ 1157 Dms_DriverPresence 2;
BA_ "GenSigSendType" SG_ 1157 Dms_DriverPresence 0;
BA_ "E2EDataId" SG_ 1157 Dms_DriverPresence 157;
BA_ "E2EProfile" SG_ 1157 Dms_DriverPresence "P01";
BA_ "E2EDataLength" SG_ 1157 Dms_DriverPresence 64;
BA_ "GenSigSendType" SG_ 1157 ICC_IHCfunctionSw 5;
BA_ "E2EDataId" SG_ 1157 ICC_IHCfunctionSw 157;
BA_ "E2EProfile" SG_ 1157 ICC_IHCfunctionSw "P01";
BA_ "E2EDataLength" SG_ 1157 ICC_IHCfunctionSw 64;
BA_ "GenSigSendType" SG_ 1279 Weather_Type 0;
BA_ "GenSigSendType" SG_ 1279 ICC_SentinelModeSts 0;
BA_ "GenSigSendType" SG_ 1279 ICC_CameraErrorCode 0;
BA_ "GenSigSendType" SG_ 1279 ICC_SentinelRequest 5;
BA_ "GenSigSendType" SG_ 1279 ICC_StartDeInitCameraStream 5;
BA_ "GenSigSendType" SG_ 1279 ICC_CameraRecoveryRequest 5;
BA_ "GenSigSendType" SG_ 1279 ICC_CleanMode 5;
BA_ "GenSigSendType" SG_ 644 ICM_5_FuelLevel 0;
BA_ "GenSigSendType" SG_ 644 FuelShortGround 0;
BA_ "GenSigSendType" SG_ 644 FuelShortPower 0;
BA_ "GenSigSendType" SG_ 644 FuelOutOfRange 0;
BA_ "GenSigSendType" SG_ 644 FuelValidData 0;
BA_ "GenSigSendType" SG_ 1174 IHU_SetSocManage 5;
BA_ "GenSigSendType" SG_ 1174 IHU_SetSOC 5;
BA_ "GenSigSendType" SG_ 1174 CTP_PowerModeSet 5;
BA_ "GenSigSendType" SG_ 1174 LidOpenReq 5;
BA_ "GenSigSendType" SG_ 1174 ICC_ForcedEVMode 5;
BA_ "GenSigSendType" SG_ 1174 ICC_EmissionMode 0;
BA_ "GenSigSendType" SG_ 1174 ICC_ForcedEVChargeMode 5;
BA_ "GenSigSendType" SG_ 1174 EVOdometer_km 0;
BA_ "GenSigInvalidValue" SG_ 1174 EVOdometer_km 16777215;
BA_ "GenSigSendType" SG_ 1174 EVOdometer_km_ValidData 0;
BA_ "GenSigSendType" SG_ 1174 ICC_SetChrgnFctMem 5;
BA_ "GenSigSendType" SG_ 1242 ICC_DK_19_CRC1 1;
BA_ "GenSigSendType" SG_ 1242 ICC_DK_19_RollgCntr1 1;
BA_ "GenSigSendType" SG_ 1242 ICC_DK_19_Resd1 1;
BA_ "GenSigSendType" SG_ 1242 ICC_DK_19_CMD 1;
BA_ "GenSigSendType" SG_ 1242 ICC_DK_19_PDU1 1;
BA_ "GenSigSendType" SG_ 1242 ICC_DK_19_PDU2 1;
BA_ "GenSigSendType" SG_ 1242 ICC_DK_19_PDU3 1;
BA_ "GenSigSendType" SG_ 1242 ICC_DK_19_PDU4 1;
BA_ "GenSigSendType" SG_ 1276 PassSeatHeiAdjmt_Target 5;
BA_ "GenSigSendType" SG_ 1276 SeatBackAndFwdAdjmt_Target 5;
BA_ "GenSigSendType" SG_ 1276 SeatBackAgAdjmt_Target 5;
BA_ "GenSigSendType" SG_ 1276 Set_ProfileID 5;
BA_ "GenSigSendType" SG_ 1276 SeatCushAgAdjmt_Target 5;
BA_ "GenSigSendType" SG_ 1276 LgRstFwdAndBckAdjmt_Target 5;
BA_ "GenSigSendType" SG_ 1276 FootRestAdjmt_Target 5;
BA_ "GenSigSendType" SG_ 1276 REQ_SeatPosRecall 5;
BA_ "GenSigSendType" SG_ 1276 REQ_SeatPosStore 5;
BA_ "GenSigSendType" SG_ 1276 Set_ToDefault 5;
BA_ "GenSigStartValue" SG_ 1276 Set_ToDefault 7;
BA_ "GenSigSendType" SG_ 1276 Set_EasyEntryEnable 5;
BA_ "GenSigStartValue" SG_ 1276 Set_EasyEntryEnable 3;
BA_ "GenSigSendType" SG_ 1276 REQ_SeatHeatPass 5;
BA_ "GenSigSendType" SG_ 1276 REQ_SeatVentPass 5;
BA_ "GenSigSendType" SG_ 1276 PassSeatMsgStr_LvlCmd 5;
BA_ "GenSigSendType" SG_ 1276 PassSeatMsg_ModeCmd 5;
BA_ "GenSigSendType" SG_ 1059 ICC_FLSeatHeatLevelCmd 5;
BA_ "GenSigSendType" SG_ 1059 ICC_FRSeatHeatLevelCmd 5;
BA_ "GenSigSendType" SG_ 1059 ICC_TrunkSW 5;
BA_ "GenSigSendType" SG_ 1059 ICC_Set_PLGOperateSts 5;
BA_ "GenSigInvalidValue" SG_ 1059 ICC_Set_PLGOperateSts 127;
BA_ "GenSigSendType" SG_ 1059 ICC_RLSeatHeatLevelCmd 5;
BA_ "GenSigSendType" SG_ 1059 ICC_RRSeatHeatLevelCmd 5;
BA_ "GenSigSendType" SG_ 1059 ICC_FLSeatVentLevelCmd 5;
BA_ "GenSigSendType" SG_ 1059 ICC_FRSeatVentLevelCmd 5;
BA_ "GenSigSendType" SG_ 1059 ICC_RLSeatVentLevelCmd 5;
BA_ "GenSigSendType" SG_ 1059 ICC_RRSeatVentLevelCmd 5;
BA_ "GenSigSendType" SG_ 1059 ICC_FrontWiperMaintenanceMode 5;
BA_ "GenSigSendType" SG_ 1059 ICC_RearWiperMaintenanceMode 5;
BA_ "GenSigSendType" SG_ 1105 ICC_MultiplexSignalStatusSet 5;
BA_ "GenSigSendType" SG_ 1056 ICC_DSBH_HeatReq 0;
BA_ "GenSigSendType" SG_ 1056 ICC_DSBH_SetTemp 0;
BA_ "GenSigStartValue" SG_ 1056 ICC_DSBH_SetTemp 30;
BA_ "GenSigSendType" SG_ 1056 ICC_PSBH_HeatReq 0;
BA_ "GenSigSendType" SG_ 1056 ICC_PSBH_SetTemp 0;
BA_ "GenSigStartValue" SG_ 1056 ICC_PSBH_SetTemp 30;
BA_ "GenSigSendType" SG_ 1112 ICC_DSeatBolsterModeCmd_458h 5;
BA_ "GenSigSendType" SG_ 1112 ICC_DSeatInOrDeflationCmd_458h 5;
BA_ "GenSigSendType" SG_ 1112 PassSeatMsgStr_LvlCmd 5;
BA_ "GenSigSendType" SG_ 1112 PassSeatMsg_ModeCmd 5;
BA_ "GenSigSendType" SG_ 1112 DriverSeatMsgStr_Lvlcmd 5;
BA_ "GenSigSendType" SG_ 1112 DriverSeatMsg_ModeCmd 5;
BA_ "GenSigSendType" SG_ 1112 RightSeatMsgStr_LvlCmd 5;
BA_ "GenSigSendType" SG_ 1112 RightSeatMsg_ModeCmd 5;
BA_ "GenSigSendType" SG_ 1112 LeftSeatMsgStr_LvlCmd 5;
BA_ "GenSigSendType" SG_ 1112 LeftSeatMsg_ModeCmd 5;
BA_ "GenSigSendType" SG_ 1265 ICC_PwrOff 0;
BA_ "GenSigSendType" SG_ 1265 ICC_EtmEgySave 0;
BA_ "GenSigSendType" SG_ 1265 ICC_HoodSW 5;
BA_ "GenSigSendType" SG_ 1265 ICC_GloveboxSW 5;
BA_ "GenSigSendType" SG_ 1265 ICC_ChrgPortCover_Switch 5;
BA_ "GenSigSendType" SG_ 1265 ICC_ReWinDefrstSwt 5;
BA_ "GenSigSendType" SG_ 1265 ICC_RearMirrorFoldCmd 5;
BA_ "GenSigSendType" SG_ 1265 ICC_CenterLockSwt 5;
BA_ "GenSigSendType" SG_ 1265 ICC_ReverseExtMirrorSts 5;
BA_ "GenSigSendType" SG_ 1265 ICC_LightMainSwitchSts 5;
BA_ "GenSigSendType" SG_ 1265 ICC_AutoFoldSts 5;
BA_ "GenSigSendType" SG_ 1265 ICC_HeadlampHeightSts 5;
BA_ "GenSigSendType" SG_ 1265 ICC_WiprSnvty 5;
BA_ "GenSigSendType" SG_ 1265 ICC_WindowCmd 5;
BA_ "GenSigSendType" SG_ 1265 ICC_LowBeamDelayOff 5;
BA_ "GenSigSendType" SG_ 1265 ICC_FLWinCmd 5;
BA_ "GenSigInvalidValue" SG_ 1265 ICC_FLWinCmd 127;
BA_ "GenSigSendType" SG_ 1265 ICC_FRWinCmd 5;
BA_ "GenSigInvalidValue" SG_ 1265 ICC_FRWinCmd 127;
BA_ "GenSigSendType" SG_ 1265 ICC_RLWinCmd 5;
BA_ "GenSigInvalidValue" SG_ 1265 ICC_RLWinCmd 127;
BA_ "GenSigSendType" SG_ 1265 ICC_RRWinCmd 5;
BA_ "GenSigInvalidValue" SG_ 1265 ICC_RRWinCmd 127;
BA_ "GenSigSendType" SG_ 1265 ICC_FGHeatSts 4;
BA_ "GenSigSendType" SG_ 1265 ICC_AutolockSts 5;
BA_ "GenSigSendType" SG_ 1265 ICC_WiperID 5;
BA_ "GenSigSendType" SG_ 1265 ICC_MaintenanceMode 5;
BA_ "GenSigSendType" SG_ 1265 ICC_lockSetSwitchSts 5;
BA_ "GenSigSendType" SG_ 1265 ICC_ChildLockSW 5;
BA_ "GenSigSendType" SG_ 1265 ICC_ParkUnlockEnable 5;
BA_ "GenSigSendType" SG_ 1265 ICC_BLEOpenDriverDoorEnable 5;
BA_ "GenSigSendType" SG_ 1265 ICC_WinInhbSwt 5;
BA_ "GenSigSendType" SG_ 1265 ICC_SteerWhlHeatgSwt 5;
BA_ "GenSigSendType" SG_ 1265 ICC_AutoHeatingset 5;
BA_ "GenSigSendType" SG_ 1265 ICC_FrontFogSw 5;
BA_ "GenSigSendType" SG_ 1265 ICC_RearFogSw 5;
BA_ "GenSigSendType" SG_ 1265 ICC_DoorControlSW 5;
BA_ "GenSigSendType" SG_ 1265 ICC_LockCarWinCloseSw 5;
BA_ "GenSigSendType" SG_ 1265 ICC_RainCarWinCloseSw 5;
BA_ "GenSigSendType" SG_ 1265 ICC_EasyEntryExitSet 5;
BA_ "GenSigSendType" SG_ 1265 ICC_NapTimeSet 5;
BA_ "GenSigSendType" SG_ 1265 ICC_NapAreaSet 5;
BA_ "GenSigSendType" SG_ 1265 ICC_NapStatusSet 5;
BA_ "GenSigSendType" SG_ 1265 ICC_NapCFSStatusSet 5;
BA_ "GenSigSendType" SG_ 1265 ICC_NapSetTemperature 5;
BA_ "GenSigInvalidValue" SG_ 1265 ICC_NapSetTemperature 31;
BA_ "GenSigStartValue" SG_ 1265 ICC_NapSetTemperature 31;
BA_ "GenSigSendType" SG_ 1265 ICC_SpoilerWelcomeFunSet 5;
BA_ "GenSigSendType" SG_ 1265 ICC_SpoilerCtrlCmd 5;
BA_ "GenSigSendType" SG_ 1265 ICC_HazardLightReq 0;
BA_ "GenSigSendType" SG_ 1265 ICC_MusicStatus 0;
BA_ "GenSigSendType" SG_ 1265 ICC_CinemaStatus 0;
BA_ "GenSigSendType" SG_ 1137 ICC_ElectronicFenceStsFed_471h 0;
BA_ "GenSigSendType" SG_ 1137 ICC_BookChrgSetReq 5;
BA_ "GenSigStartValue" SG_ 1137 ICC_BookChrgSetReq 3;
BA_ "GenSigSendType" SG_ 1137 ICC_BkChrgStartTimeYear 0;
BA_ "GenSigSendType" SG_ 1137 ICC_BkChrgStartTimeDay 0;
BA_ "GenSigStartValue" SG_ 1137 ICC_BkChrgStartTimeDay 1;
BA_ "GenSigSendType" SG_ 1137 ICC_BkChrgStartTimeHour 0;
BA_ "GenSigInvalidValue" SG_ 1137 ICC_BkChrgStartTimeHour 31;
BA_ "GenSigStartValue" SG_ 1137 ICC_BkChrgStartTimeHour 31;
BA_ "GenSigSendType" SG_ 1137 ICC_BkChrgStartTimemMin 0;
BA_ "GenSigInvalidValue" SG_ 1137 ICC_BkChrgStartTimemMin 63;
BA_ "GenSigStartValue" SG_ 1137 ICC_BkChrgStartTimemMin 63;
BA_ "GenSigSendType" SG_ 1137 ICC_BkChrgStartTimeMonth 0;
BA_ "GenSigStartValue" SG_ 1137 ICC_BkChrgStartTimeMonth 1;
BA_ "GenSigSendType" SG_ 1137 ICC_BkChrgDuration 0;
BA_ "GenSigInvalidValue" SG_ 1137 ICC_BkChrgDuration 2047;
BA_ "GenSigStartValue" SG_ 1137 ICC_BkChrgDuration 2047;
BA_ "GenSigSendType" SG_ 1137 ICC_BkChrgCycleType 0;
BA_ "GenSigSendType" SG_ 1137 ICC_StopChrgReq 5;
BA_ "GenSigSendType" SG_ 1137 ICC_BkChrgCycleMon 0;
BA_ "GenSigSendType" SG_ 1137 ICC_BkChrgCycleTues 0;
BA_ "GenSigSendType" SG_ 1137 ICC_BkChrgCycleWen 0;
BA_ "GenSigSendType" SG_ 1137 ICC_BkChrgCycleThur 0;
BA_ "GenSigSendType" SG_ 1137 ICC_BkChrgCycleFri 0;
BA_ "GenSigSendType" SG_ 1137 ICC_BkChrgCycleSat 0;
BA_ "GenSigSendType" SG_ 1137 ICC_BkChrgCycleSun 0;
BA_ "GenSigSendType" SG_ 1137 ICC_KeepWarmStrt 0;
BA_ "GenSigStartValue" SG_ 1137 ICC_KeepWarmStrt 1;
BA_ "GenSigInvalidValue" SG_ 1137 ICC_KeepWarmStrtHour 31;
BA_ "GenSigSendType" SG_ 1137 ICC_KeepWarmStrtHour 0;
BA_ "GenSigInvalidValue" SG_ 1137 ICC_KeepWarmStrtMin 63;
BA_ "GenSigSendType" SG_ 1137 ICC_KeepWarmStrtMin 0;
BA_ "GenSigSendType" SG_ 1137 ICC_PetmodeFb 0;
BA_ "GenSigInvalidValue" SG_ 1137 ICC_PetmodeFb 3;
BA_ "GenSigSendType" SG_ 1137 ICC_SentinelModeSwitchSts 0;
BA_ "GenSigSendType" SG_ 1137 ICC_SentinelModeWorkingSts 0;
BA_ "GenSigSendType" SG_ 1137 ICC_SentinelModeFaultSts 0;
BA_ "GenSigSendType" SG_ 1137 ICC_SentinelModeAlarmSts 0;
BA_ "GenSigSendType" SG_ 1137 ICC_SentinelModeExitReason 0;
BA_ "GenSigSendType" SG_ 1137 ICC_PetModeWarn 0;
BA_ "GenSigSendType" SG_ 1137 ICC_TBOXPetmodeReq 5;
BA_ "GenSigSendType" SG_ 1137 ICC_PetModeWarn_2 0;
BA_ "GenSigSendType" SG_ 1137 ICM_FuelLevel 0;
BA_ "GenSigSendType" SG_ 1137 ICM_AverageVehicleSpeed 0;
BA_ "GenSigSendType" SG_ 1137 ICM_DistenceToEmpty_Km 0;
BA_ "GenSigSendType" SG_ 1137 ICM_FuelLevelFailSts 0;
BA_ "GenSigSendType" SG_ 1137 ICM_Maintenance_tips 0;
BA_ "GenSigSendType" SG_ 1137 ICM_SumTrip 0;
BA_ "GenSigSendType" SG_ 1144 ICC_CarSickRelfModeReq 5;
BA_ "GenSigSendType" SG_ 1144 ICC_HvBattKeepWarmSet 0;
BA_ "GenSigInvalidValue" SG_ 1144 ICC_HvBattKeepWarmSet 3;
BA_ "GenSigStartValue" SG_ 1144 ICC_HvBattKeepWarmSet 3;
BA_ "GenSigSendType" SG_ 1144 ICC_EnergyRegSet 5;
BA_ "GenSigSendType" SG_ 1144 ICC_HvBattKeepWarmActiveReq 5;
BA_ "GenSigSendType" SG_ 1210 ICC_1_IDverify 5;
BA_ "GenSigSendType" SG_ 1210 ICC_FLSeatHeiCmd 5;
BA_ "GenSigSendType" SG_ 1210 ICC_FLSeatLvlCmd 5;
BA_ "GenSigSendType" SG_ 1210 ICC_FLSeatBackAgCmd 5;
BA_ "GenSigSendType" SG_ 1210 ICC_FLSeatCushCmd 5;
BA_ "GenSigSendType" SG_ 1210 ICC_FLSeatLegSpprtCmd 5;
BA_ "GenSigSendType" SG_ 1210 ICC_FRSeatHeiCmd 5;
BA_ "GenSigSendType" SG_ 1210 ICC_FRSeatLvlCmd 5;
BA_ "GenSigSendType" SG_ 1210 ICC_FRSeatBackAgCmd 5;
BA_ "GenSigSendType" SG_ 1210 ICC_FRSeatLegSpprtCmd 5;
BA_ "GenSigSendType" SG_ 1210 ICC_MemoryRecoveryCmd 5;
BA_ "GenSigSendType" SG_ 1210 ICC_DeleteFaceID 5;
BA_ "GenSigSendType" SG_ 1210 ICC_FLSeatHeitargetCmd 5;
BA_ "GenSigInvalidValue" SG_ 1210 ICC_FLSeatHeitargetCmd 127;
BA_ "GenSigSendType" SG_ 1210 ICC_FLSeatLvltargetCmd 5;
BA_ "GenSigInvalidValue" SG_ 1210 ICC_FLSeatLvltargetCmd 127;
BA_ "GenSigSendType" SG_ 1210 ICC_FLSeatBackAgtargetCmd 5;
BA_ "GenSigInvalidValue" SG_ 1210 ICC_FLSeatBackAgtargetCmd 127;
BA_ "GenSigSendType" SG_ 1210 ICC_FLSeatCushtargetCmd 5;
BA_ "GenSigInvalidValue" SG_ 1210 ICC_FLSeatCushtargetCmd 127;
BA_ "GenSigSendType" SG_ 1210 ICC_FLSeatLegSpprttargetCmd 5;
BA_ "GenSigInvalidValue" SG_ 1210 ICC_FLSeatLegSpprttargetCmd 127;
BA_ "GenSigSendType" SG_ 1210 ICC_FRSeatHeitargetCmd 5;
BA_ "GenSigInvalidValue" SG_ 1210 ICC_FRSeatHeitargetCmd 127;
BA_ "GenSigSendType" SG_ 1210 ICC_FRSeatLvltargetCmd 5;
BA_ "GenSigInvalidValue" SG_ 1210 ICC_FRSeatLvltargetCmd 127;
BA_ "GenSigSendType" SG_ 1210 ICC_FRSeatBackAgtargetCmd 5;
BA_ "GenSigInvalidValue" SG_ 1210 ICC_FRSeatBackAgtargetCmd 127;
BA_ "GenSigSendType" SG_ 1210 ICC_FRSeatLegSpprttargetCmd 5;
BA_ "GenSigInvalidValue" SG_ 1210 ICC_FRSeatLegSpprttargetCmd 127;
BA_ "GenSigSendType" SG_ 1210 ICC_NapFLSeatBackAgtargetSet 5;
BA_ "GenSigInvalidValue" SG_ 1210 ICC_NapFLSeatBackAgtargetSet 127;
BA_ "GenSigSendType" SG_ 1210 ICC_NapFRSeatBackAgtargetSet 5;
BA_ "GenSigInvalidValue" SG_ 1210 ICC_NapFRSeatBackAgtargetSet 127;
BA_ "GenSigSendType" SG_ 1210 ICC_NapFLSeatLvltargetSet 5;
BA_ "GenSigInvalidValue" SG_ 1210 ICC_NapFLSeatLvltargetSet 127;
BA_ "GenSigSendType" SG_ 1210 ICC_NapFRSeatLvltargetSet 5;
BA_ "GenSigInvalidValue" SG_ 1210 ICC_NapFRSeatLvltargetSet 127;
BA_ "GenSigSendType" SG_ 1210 ICC_FRSeatLegRestAngleCmd 5;
BA_ "GenSigSendType" SG_ 1210 ICC_FRSeatLegRestAngletargetCmd 5;
BA_ "GenSigInvalidValue" SG_ 1210 ICC_FRSeatLegRestAngletargetCmd 127;
BA_ "GenSigSendType" SG_ 1210 ICC_FRSeatCushCmd 5;
BA_ "GenSigSendType" SG_ 1210 ICC_FRSeatCushtargetCmd 5;
BA_ "GenSigInvalidValue" SG_ 1210 ICC_FRSeatCushtargetCmd 127;
BA_ "GenSigSendType" SG_ 1210 ICC_FRZeroGravitySeatSw 5;
BA_ "GenSigSendType" SG_ 1210 ICC_HomeLinkArmHornSet 5;
BA_ "GenSigSendType" SG_ 1210 ICC_HomeLinkWelLightSet 5;
BA_ "GenSigSendType" SG_ 1210 ICC_HomeLinkPositionSts 0;
BA_ "GenSigSendType" SG_ 1210 ICC_WelcomeOpenSetCmd 5;
BA_ "GenSigSendType" SG_ 1210 ICC_WALOpenSetCmd 5;
BA_ "GenSigSendType" SG_ 1210 ICC_UIROpenSetCmd 5;
BA_ "GenSigSendType" SG_ 1210 ICC_EnjoyableSeatSwitch 5;
BA_ "GenSigSendType" SG_ 1210 ICC_BLTKeyPESet 5;
BA_ "GenSigSendType" SG_ 1210 ICC_FRMemoryDeleteCmd 5;
BA_ "GenSigSendType" SG_ 1210 ICC_FLSitPosnlocation 5;
BA_ "GenSigSendType" SG_ 1210 ICC_FRSitPosnlocation 5;
BA_ "GenSigSendType" SG_ 1210 ICC_FREasyEntryExitSet 5;
BA_ "GenSigSendType" SG_ 1210 ICC_FRMemoryRecoveryCmd 5;
BA_ "GenSigSendType" SG_ 1210 ICC_ConsoleAdjustSwitch 5;
VAL_ 1345 DVR_1_DVRFailReasons 0 "NoFailure" 1 "DVR360StorageFailure" 2 "DVRFCMStorageFailure" 3 "DVRAllFailure" 4 "Reserved" 5 "Reserved" 6 "Reserved" 7 "Reserved" ;
VAL_ 1345 DVR_1_RecordSts 0 "Initinal" 1 "Recording" 2 "RecordStop" 3 "Reserved" ;
VAL_ 1121 STAT_AMPNaviVolume 0 "Not Active" 1 "0" 2 "1" 3 "2" 4 "3" 5 "4" 6 "5" 7 "6" 8 "7" 9 "8" 10 "9" 11 "10" 12 "Reserved" 13 "Reserved" 14 "Reserved" 15 "Reserved" ;
VAL_ 1121 STAT_AMPVRVolume 0 "Not Active" 1 "0" 2 "1" 3 "2" 4 "3" 5 "4" 6 "5" 7 "6" 8 "7" 9 "8" 10 "9" 11 "10" 12 "Reserved" 13 "Reserved" 14 "Reserved" 15 "Reserved" ;
VAL_ 1121 STAT_AMPKeyTone 0 "Not Active" 1 "ON" 2 "OFF" 3 "reserved" ;
VAL_ 1121 STAT_AMPMediaVolume 0 "Not Active" 1 "0" 2 "1" 3 "2" 4 "3" 5 "4" 6 "5" 7 "6" 8 "7" 9 "8" 10 "9" 11 "10" 12 "11" 13 "12" 14 "13" 15 "14" 16 "15" 17 "16" 18 "17" 19 "18" 20 "19" 21 "20" 22 "21" 23 "22" 24 "23" 25 "24" 26 "25" 27 "26" 28 "27" 29 "28" 30 "29" 31 "30" 32 "31" 33 "Reserved" 34 "Reserved" 35 "Reserved" 36 "Reserved" 37 "Reserved" 38 "Reserved" 39 "Reserved" 40 "Reserved" 41 "Reserved" 42 "Reserved" 43 "Reserved" 44 "Reserved" 45 "Reserved" 46 "Reserved" 47 "Reserved" 48 "Reserved" 49 "Reserved" 50 "Reserved" 51 "Reserved" 52 "Reserved" 53 "Reserved" 54 "Reserved" 55 "Reserved" 56 "Reserved" 57 "Reserved" 58 "Reserved" 59 "Reserved" 60 "Reserved" 61 "Reserved" 62 "Reserved" 63 "Reserved" ;
VAL_ 1121 STAT_AMPPhoneVolume 0 "Not Active" 1 "0" 2 "1" 3 "2" 4 "3" 5 "4" 6 "5" 7 "6" 8 "7" 9 "8" 10 "9" 11 "10" 12 "11" 13 "12" 14 "13" 15 "14" 16 "15" 17 "16" 18 "17" 19 "18" 20 "19" 21 "20" 22 "21" 23 "22" 24 "23" 25 "24" 26 "25" 27 "Reserved" 28 "Reserved" 29 "Reserved" 30 "Reserved" 31 "Reserved" ;
VAL_ 1121 STAT_AMPSoundFocus 0 "Not Active" 1 "Customized" 2 "All" 3 "Driver" 4 "Sleep" 5 "VIP" 6 "Dolby7.1.4" 7 "Reserved" ;
VAL_ 1121 STAT_AMPSoundEffect 0 "Not Active" 1 "Customer-defined mode" 2 "Standard mode" 3 "Popular mode" 4 "Jazz mode" 5 "Classic mode" 6 "Rock mode" 7 "Vocal mode" 8 "Reserved" 9 "Reserved" 10 "Reserved" 11 "Reserved" 12 "Reserved" 13 "Reserved" 14 "Reserved" 15 "Reserved" ;
VAL_ 1121 STAT_AMPSoundEffectBass 0 "Not Active" 1 "-7" 2 "-6" 3 "-5" 4 "-4" 5 "-3" 6 "-2" 7 "-1" 8 "0" 9 "1" 10 "2" 11 "3" 12 "4" 13 "5" 14 "6" 15 "7" ;
VAL_ 1121 STAT_AMPSoundEffectMidrange 0 "Not Active" 1 "-7" 2 "-6" 3 "-5" 4 "-4" 5 "-3" 6 "-2" 7 "-1" 8 "0" 9 "1" 10 "2" 11 "3" 12 "4" 13 "5" 14 "6" 15 "7" ;
VAL_ 1121 STAT_AMPSoundEffectTreble 0 "Not Active" 1 "-7" 2 "-6" 3 "-5" 4 "-4" 5 "-3" 6 "-2" 7 "-1" 8 "0" 9 "1" 10 "2" 11 "3" 12 "4" 13 "5" 14 "6" 15 "7" ;
VAL_ 1121 STAT_AMPSoundFieldBalance 0 "Not Active" 1 "-7" 2 "-6" 3 "-5" 4 "-4" 5 "-3" 6 "-2" 7 "-1" 8 "0" 9 "1" 10 "2" 11 "3" 12 "4" 13 "5" 14 "6" 15 "7" ;
VAL_ 1121 STAT_AMPSoundFieldFader 0 "Not Active" 1 "-7" 2 "-6" 3 "-5" 4 "-4" 5 "-3" 6 "-2" 7 "-1" 8 "0" 9 "1" 10 "2" 11 "3" 12 "4" 13 "5" 14 "6" 15 "7" ;
VAL_ 1121 STAT_REQ_AMPA2BMediaSound 0 "Not Active" 1 "Media" 2 "Background" 3 "OFF" ;
VAL_ 1121 STAT_REQ_AMPA2BNaviSound 0 "Not Active" 1 "ON" 2 "OFF" 3 "Reserved" ;
VAL_ 1121 STAT_REQ_AMPA2BVRSound 0 "Not Active" 1 "VR" 2 "Siri" 3 "OFF" ;
VAL_ 1121 STAT_REQ_AMPA2BTTSSound 0 "Not Active" 1 "ON" 2 "OFF" 3 "Reserved" ;
VAL_ 1121 STAT_REQ_AMPA2BPhoneSound 0 "Not Active" 1 "BT Phone Sound ON" 2 "Tbox Sound ON" 3 "OFF" ;
VAL_ 1121 STAT_REQ_AMPAlarm 0 "Not Active" 1 "Other CHIME" 2 "PDC_FL only" 3 "PDC_FR only" 4 "PDC_RL only" 5 "PDC_RR only" 6 "PDC_FL+FR" 7 "PDC_FL+RL" 8 "PDC_FL+RR" 9 "PDC_FR+RL" 10 "PDC_FR+RR" 11 "PDC_RL+RR" 12 "PDC_FL+FR+RL" 13 "PDC_FL+FR+RR" 14 "PDC_FL+RL+RR" 15 "PDC_FR+RL+RR" 16 "PDC_all" 17 "BSD_L only" 18 "BSD_R only" 19 "BSD_L+R" 20 "CHIME OFF" 21 "Reserved" 22 "Reserved" 23 "Reserved" 24 "Reserved" 25 "Reserved" 26 "Reserved" 27 "Reserved" 28 "Reserved" 29 "Reserved" 30 "Reserved" 31 "Reserved" 32 "Reserved" 33 "Reserved" 34 "Reserved" 35 "Reserved" 36 "Reserved" 37 "Reserved" 38 "Reserved" 39 "Reserved" 40 "Reserved" 41 "Reserved" 42 "Reserved" 43 "Reserved" 44 "Reserved" 45 "Reserved" 46 "Reserved" 47 "Reserved" 48 "Reserved" 49 "Reserved" 50 "Reserved" 51 "Reserved" 52 "Reserved" 53 "Reserved" 54 "Reserved" 55 "Reserved" 56 "Reserved" 57 "Reserved" 58 "Reserved" 59 "Reserved" 60 "Reserved" 61 "Reserved" 62 "Reserved" 63 "Reserved" ;
VAL_ 1140 STAT_AMPMediaDuck 0 "Not Active" 1 "ON" 2 "OFF" 3 "Reserved" ;
VAL_ 1140 STAT_AMPSpeedVolume 0 "Not Active" 1 "OFF" 2 "Low" 3 "Middle" 4 "High" 5 "Reserved" 6 "Reserved" 7 "Reserved" ;
VAL_ 1140 STAT_AMPMute 0 "Not Active" 1 "ON" 2 "OFF" 3 "Reserved" ;
VAL_ 1140 STAT_AMPRestoreDefaults 0 "Not Active" 1 "ON" 2 "OFF" 3 "Reserved" ;
VAL_ 1140 STAT_AMPAlarmVolume 0 "Not Active" 1 "1" 2 "2" 3 "3" 4 "4" 5 "5" 6 "6" 7 "7" 8 "8" 9 "9" 10 "10" 11 "Reserved" 12 "Reserved" 13 "Reserved" 14 "Reserved" 15 "Reserved" ;
VAL_ 1140 STAT_Headrest_Mode 0 "Not Active" 1 "Share Mode" 2 "Enjoy Driving Mode" 3 "Enjoy Private Mode" ;
VAL_ 1140 STAT_AMPSoundEffectMegaBass 0 "Not Active" 1 "-7" 2 "-6" 3 "-5" 4 "-4" 5 "-3" 6 "-2" 7 "-1" 8 "0" 9 "1" 10 "2" 11 "3" 12 "4" 13 "5" 14 "6" 15 "7" ;
VAL_ 1140 STAT_AMPSoundEffectMidBass 0 "Not Active" 1 "-7" 2 "-6" 3 "-5" 4 "-4" 5 "-3" 6 "-2" 7 "-1" 8 "0" 9 "1" 10 "2" 11 "3" 12 "4" 13 "5" 14 "6" 15 "7" ;
VAL_ 1140 STAT_AMPSoundEffectMidTreble 0 "Not Active" 1 "-7" 2 "-6" 3 "-5" 4 "-4" 5 "-3" 6 "-2" 7 "-1" 8 "0" 9 "1" 10 "2" 11 "3" 12 "4" 13 "5" 14 "6" 15 "7" ;
VAL_ 1140 STAT_VirtualSbwfrOnOff 0 "Not Active" 1 "VocalConcert" 2 "ConcertHall" 3 "OFF" ;
VAL_ 1140 STAT_SurndFnOnOff 0 "Not Active" 1 "ON" 2 "OFF" 3 "Reserved" ;
VAL_ 1140 STAT_AMPBackgroundVolume 0 "Not Active" 1 "0" 2 "1" 3 "2" 4 "3" 5 "4" 6 "5" 7 "6" 8 "7" 9 "8" 10 "9" 11 "10" 12 "11" 13 "12" 14 "13" 15 "14" 16 "15" 17 "16" 18 "17" 19 "18" 20 "19" 21 "20" 22 "21" 23 "22" 24 "23" 25 "24" 26 "25" 27 "26" 28 "27" 29 "28" 30 "29" 31 "30" 32 "31" 33 "Reserved" 34 "Reserved" 35 "Reserved" 36 "Reserved" 37 "Reserved" 38 "Reserved" 39 "Reserved" 40 "Reserved" 41 "Reserved" 42 "Reserved" 43 "Reserved" 44 "Reserved" 45 "Reserved" 46 "Reserved" 47 "Reserved" 48 "Reserved" 49 "Reserved" 50 "Reserved" 51 "Reserved" 52 "Reserved" 53 "Reserved" 54 "Reserved" 55 "Reserved" 56 "Reserved" 57 "Reserved" 58 "Reserved" 59 "Reserved" 60 "Reserved" 61 "Reserved" 62 "Reserved" 63 "Reserved" ;
VAL_ 1140 STAT_AMPSoundBypass 0 "Not Active" 1 "ON" 2 "OFF" 3 "Reserved" ;
VAL_ 1140 STAT_AMPPwrRdySts 0 "Not Active" 1 "Not Ready" 2 "Ready" 3 "Reserved" ;
VAL_ 1206 EAMP_AMPKTVvoiceVolumeFed 0 "Not Active" 1 "0" 2 "1" 3 "2" 4 "3" 5 "4" 6 "5" 7 "6" 8 "7" 9 "8" 10 "9" 11 "10" 12 "11" 13 "12" 14 "13" 15 "14" 16 "15" 17 "16" 18 "17" 19 "18" 20 "19" 21 "20" 22 "21" 23 "22" 24 "23" 25 "24" 26 "25" 27 "26" 28 "27" 29 "28" 30 "29" 31 "30" 32 "31" 33 "Reserved" 34 "Reserved" 35 "Reserved" 36 "Reserved" 37 "Reserved" 38 "Reserved" 39 "Reserved" 40 "Reserved" 41 "Reserved" 42 "Reserved" 43 "Reserved" 44 "Reserved" 45 "Reserved" 46 "Reserved" 47 "Reserved" 48 "Reserved" 49 "Reserved" 50 "Reserved" 51 "Reserved" 52 "Reserved" 53 "Reserved" 54 "Reserved" 55 "Reserved" 56 "Reserved" 57 "Reserved" 58 "Reserved" 59 "Reserved" 60 "Reserved" 61 "Reserved" 62 "Reserved" 63 "Reserved" ;
VAL_ 1206 EAMP_AMPENCVolumeFed 0 "Not Active" 1 "0" 2 "1" 3 "2" 4 "3" 5 "4" 6 "5" 7 "6" 8 "7" 9 "8" 10 "9" 11 "10" 12 "11" 13 "12" 14 "13" 15 "14" 16 "15" 17 "16" 18 "17" 19 "18" 20 "19" 21 "20" 22 "21" 23 "22" 24 "23" 25 "24" 26 "25" 27 "26" 28 "27" 29 "28" 30 "29" 31 "30" 32 "31" 33 "Reserved" 34 "Reserved" 35 "Reserved" 36 "Reserved" 37 "Reserved" 38 "Reserved" 39 "Reserved" 40 "Reserved" 41 "Reserved" 42 "Reserved" 43 "Reserved" 44 "Reserved" 45 "Reserved" 46 "Reserved" 47 "Reserved" 48 "Reserved" 49 "Reserved" 50 "Reserved" 51 "Reserved" 52 "Reserved" 53 "Reserved" 54 "Reserved" 55 "Reserved" 56 "Reserved" 57 "Reserved" 58 "Reserved" 59 "Reserved" 60 "Reserved" 61 "Reserved" 62 "Reserved" 63 "Reserved" ;
VAL_ 1206 EAMP_AMPA2BKTVvoiceSoundFed 0 "Not Active" 1 "IESS OFF and KTV OFF（默认值)" 2 "IESS OFF and KTV ON" 3 "IESS ON and KTV OFF" 4 "IESS ON and KTV ON" 5 "Reserved" 6 "Reserved" 7 "Reserved" ;
VAL_ 1206 STAT_AMPSoundFocus_2 0 "Not Active" 1 "Customized" 2 "All" 3 "Driver" 4 "Sleep" 5 "VIP" 6 "FrontRow" 7 "BackRow" 8 "Reserved" 9 "Reserved" 10 "Reserved" 11 "Reserved" 12 "Reserved" 13 "Reserved" 14 "Reserved" 15 "Reserved" ;
VAL_ 1206 EAMP_AMPA2BENCSoundFed 0 "Not Active" 1 "ON" 2 "OFF" 3 "Reserved" ;
VAL_ 1206 EAMP_AMPA2BChimeSoundFed 0 "Not Active" 1 "ON" 2 "OFF" 3 "Reserved" ;
VAL_ 1361 EPC_LeftPedalSystem_Sts 0 "Normal" 1 "Voltage_protect" 2 "System_fault" 3 "Over_temperature" 4 "Disable_mode" 5 "Left_steer" 6 "Left_pedal_Anti-pinch" 7 "Reserved" 8 "Reserved" 9 "Reserved" 10 "Reserved" 11 "Reserved" 12 "Reserved" 13 "Reserved" 14 "Reserved" 15 "Reserved" ;
VAL_ 1361 EPC_RightPedalSystem_Sts 0 "Normal" 1 "Voltage_protect" 2 "System_fault" 3 "Over_temperature" 4 "Disable_mode" 5 "Right_steer" 6 "Right_pedal_Anti-pinch" 7 "Reserved" 8 "Reserved" 9 "Reserved" 10 "Reserved" 11 "Reserved" 12 "Reserved" 13 "Reserved" 14 "Reserved" 15 "Reserved" ;
VAL_ 1361 EPC_LeftPedalRealTime_Sts 0 "Invalid" 1 "Left_pedal_retract_back_in_place" 2 "Left_pedal_is_retracting" 3 "Left_pedal_retract_failed" 4 "Left_pedal_spread_in_place" 5 "Left_pedal_is_spreading" 6 "Left_pedal_is_spread_failed" 7 "Reserved" ;
VAL_ 1361 EPC_LeftPedalBreakIce_Sts 0 "Invalid" 1 "Left_pedal_is_breaking_ice" 2 "Left_pedal_break_ice_successfully" 3 "Left_pedal_break_ice_failed" ;
VAL_ 1361 EPC_RightPedalRealTime_Sts 0 "Invalid" 1 "Right_pedal_retract_back_in_place" 2 "Right_pedal_is_retracting" 3 "Right_pedal_retract_failed" 4 "Right_pedal_spread_in_place" 5 "Right_pedal_is_spreading" 6 "Right_pedal_is_spread_failed" 7 "Reserved" ;
VAL_ 1361 EPC_RightPedalBreakIce_Sts 0 "Invalid" 1 "Right_pedal_is_breaking_ice" 2 "Right_pedal_break_ice_successfully" 3 "Right_pedal_break_ice_failed" ;
VAL_ 1361 EPC_Enable_CmdStatus 0 "Not active" 1 "ON" 2 "OFF" 3 "Invaild" ;
VAL_ 1361 EPC_LeftPedalCmdStatus 0 "Not active" 1 "Spread_LeftPedal" 2 "Retract_LeftPedal" 3 "Auto" ;
VAL_ 1361 EPC_RightPedalCmdStatus 0 "Not active" 1 "Spread_RightPedal" 2 "Retract_RightPedal" 3 "Auto" ;
VAL_ 1361 EPC_LeftPedal3D_Sts 0 "Not Active" 1 "Open" 2 "Close" 3 "Reserved" ;
VAL_ 1361 EPC_RightPedal3D_Sts 0 "Not Active" 1 "Open" 2 "Close" 3 "Reserved" ;
VAL_ 1349 SBOX_MSD_Res 0 "Reserved" 1 "send successfully" 2 "no signal" 3 "uncast net" 4 "short messages not enough" 5 "Reserved" 6 "Reserved" 7 "Reserved" 8 "Reserved" 9 "Reserved" 10 "Reserved" 11 "Reserved" 12 "Reserved" 13 "Reserved" 14 "Reserved" 15 "Reserved" ;
VAL_ 1349 SBOX_Ecallphonenub_Res 0 "Reserved" 1 "dialing" 2 "ringing" 3 "on the line" 4 "hang up" 5 "no signal" 6 "uncast net" 7 "Reserved" 8 "Reserved" 9 "Reserved" 10 "Reserved" 11 "Reserved" 12 "Reserved" 13 "Reserved" 14 "Reserved" 15 "Reserved" ;
VAL_ 1451 SBOX_GNSS_ANT_State 0 "GPS State is normal" 1 "GPS State is Short-Circuit to GND" 2 "GPS State is Short-Circuit to VCC" 3 "Reserved" ;
VAL_ 1451 SBOX_SIM_State 0 "SIM_State is normal" 1 "SIM_State is abnormal" ;
VAL_ 1451 SBOX_BT_State 0 "BT_State is normal" 1 "BT_State is abnormal" ;
VAL_ 1451 SBOX_TT_State 0 "TT_State is normal" 1 "TT_State is abnormal" ;
VAL_ 1451 SBOX_TT_ANT_State 0 "TT State is normal" 1 "TT State is Short-Circuit to GND" 2 "TT State is Short-Circuit to VCC" 3 "Reserved" ;
VAL_ 1451 SBOX_BatterState 0 "BackupPowe is normal" 1 "BackupPowe is Short-Circuit" 2 "BackupPowe is Open-Circuit" 3 "Reserved" ;
VAL_ 1451 SBOX_PowerState 0 "Power is normal" 1 "Power is overvoltage" 2 "Power is undervoltage" 3 "Reserved" ;
VAL_ 1451 SBOX_SimActivation 0 "unactivate" 1 "activate" ;
VAL_ 1451 SBOX_TspActivation 0 "unactivate" 1 "activate" ;
VAL_ 1451 SBOX_SatelliteStatus 1 "holding state" 2 "registered network" 3 "registration network failure" 4 "register network successfully" ;
VAL_ 1451 SBOX_BtConState 0 "not connect" 1 "connect car(SPP)" 2 "connect app(BLE)" ;
VAL_ 1451 SBOX_SelfCheck 0 "Invalid" 1 "Abnormal" 2 "Normal" ;
VAL_ 1451 SBOX_BatTemp 255 "Invalid" ;
VAL_ 1451 SBOX_EcallState 0 "Invalid" 1 "Unactivate" 2 "Activate" 3 "Reserved" ;
VAL_ 1353 SBOX_ICC_MACReq 0 "invalid" 1 "request connect" ;
VAL_ 1078 PLG_LatchSts 0 "Open" 1 "Secondary" 2 "Latched" 3 "Initializing" ;
VAL_ 1310 BBCM_RLSeatEasyEntryExitFb 0 "Not Active" 1 "ON" 2 "OFF" 3 "Not Used" ;
VAL_ 1310 BBCM_RRSeatEasyEntryExitFb 0 "Not Active" 1 "ON" 2 "OFF" 3 "Not Used" ;
VAL_ 1310 BBCM_RLSeatNeedMemory 0 "No Request" 1 "Request" 2 "Reserved" 3 "Reserved" ;
VAL_ 1310 BBCM_RLMemoryFb 0 "Not Active" 1 "Success" 2 "Fail" 3 "Ongoing" ;
VAL_ 1310 BBCM_RLRecoverFb 0 "Not Active" 1 "Success" 2 "Fail" 3 "Ongoing" ;
VAL_ 1310 BBCM_RRSeatNeedMemory 0 "No Request" 1 "Request" 2 "Reserved" 3 "Reserved" ;
VAL_ 1310 BBCM_RRMemoryFb 0 "Not Active" 1 "Success" 2 "Fail" 3 "Ongoing" ;
VAL_ 1310 BBCM_RRRecoverFb 0 "Not Active" 1 "Success" 2 "Fail" 3 "Ongoing" ;
VAL_ 1310 BBCM_RLSeatLvlFb2nd 0 "Not active" ;
VAL_ 1310 BBCM_RLSeatBackAgFb2nd 0 "Not active" ;
VAL_ 1310 BBCM_RLSeatLegSpprtFb2nd 0 "Not active" ;
VAL_ 1310 BBCM_RLSeatLegRestAngleFb2nd 0 "Not active" ;
VAL_ 1310 BBCM_RRSeatLvlFb2nd 0 "Not active" ;
VAL_ 1310 BBCM_RRSeatBackAgFb2nd 0 "Not active" ;
VAL_ 1310 BBCM_RRSeatLegSpprtFb2nd 0 "Not active" ;
VAL_ 1310 BBCM_RRSeatLegRestAngleFb2nd 0 "Not active" ;
VAL_ 1310 BBCM_RLSeatBackAgFb3rd 0 "Not active" ;
VAL_ 1310 BBCM_RRSeatBackAgFb3rd 0 "Not active" ;
VAL_ 1310 BBCM_RLSeatFrontFlipFb3rd 0 "Not active" ;
VAL_ 1310 BBCM_RRSeatFrontFlipFb3rd 0 "Not active" ;
VAL_ 1201 CMSM_DisplaySwitch 0 "Not active" 1 "ON" 2 "OFF" 3 "Reserved" ;
VAL_ 1201 CMSM_DisplayAdjustmode 0 "Not active" 1 "NormalAngle" 2 "ViewAngle" 3 "Reserved" ;
VAL_ 1201 CMSM_DisplayStandard 0 "Not active" 1 "suscess" 2 "fail" 3 "Reserved" ;
VAL_ 1252 TotalOdometer_km_OBD 16777215 "Invalid" ;
VAL_ 1252 DisplayVehicleSpeed 8191 "Invalid" ;
VAL_ 1252 ICC_BackLightLevel 0 "Level 1" 1 "Level 2" 2 "Level 3" 3 "Level 4" 4 "Level 5" 5 "Level 6" 6 "Level 7" 7 "Level 8" 8 "Level 9" 9 "Level 10" 10 "Reserved" 11 "Reserved" 12 "Reserved" 13 "Reserved" 14 "Reserved" 15 "Reserved" ;
VAL_ 1252 TotalOdometer_km_OBDValidData 0 "Valid" 1 "Not valid" ;
VAL_ 1252 ICC_TotalodometerbackupEnable 0 "Not Active" 1 "Disable" 2 "Enable" 3 "Reserved" ;
VAL_ 1322 STAT_AMPAlarm 0 "Not Active" 1 "Other CHIME" 2 "PDC_FL only" 3 "PDC_FR only" 4 "PDC_RL only" 5 "PDC_RR only" 6 "PDC_FL+FR" 7 "PDC_FL+RL" 8 "PDC_FL+RR" 9 "PDC_FR+RL" 10 "PDC_FR+RR" 11 "PDC_RL+RR" 12 "PDC_FL+FR+RL" 13 "PDC_FL+FR+RR" 14 "PDC_FL+RL+RR" 15 "PDC_FR+RL+RR" 16 "PDC_all" 17 "BSD_L only" 18 "BSD_R only" 19 "BSD_L+R" 20 "CHIME OFF" 21 "Reserved" 22 "Reserved" 23 "Reserved" 24 "Reserved" 25 "Reserved" 26 "Reserved" 27 "Reserved" 28 "Reserved" 29 "Reserved" 30 "Reserved" 31 "Reserved" 32 "Reserved" 33 "Reserved" 34 "Reserved" 35 "Reserved" 36 "Reserved" 37 "Reserved" 38 "Reserved" 39 "Reserved" 40 "Reserved" 41 "Reserved" 42 "Reserved" 43 "Reserved" 44 "Reserved" 45 "Reserved" 46 "Reserved" 47 "Reserved" 48 "Reserved" 49 "Reserved" 50 "Reserved" 51 "Reserved" 52 "Reserved" 53 "Reserved" 54 "Reserved" 55 "Reserved" 56 "Reserved" 57 "Reserved" 58 "Reserved" 59 "Reserved" 60 "Reserved" 61 "Reserved" 62 "Reserved" 63 "Reserved" ;
VAL_ 1176 ICC_ASUAssistPassSet 0 "Not Active" 1 "ON" 2 "OFF" 3 "Not Used" ;
VAL_ 1176 IHU_AutHldSet 0 "Not Active" 1 "On" 2 "Off" 3 "Not Used" ;
VAL_ 1176 ICC_AutoEasyEntrySet 0 "Not Active" 1 "ON" 2 "OFF" 3 "Not Used" ;
VAL_ 1176 ICC_ManualEasyOutSw 0 "Not Active" 1 "ON" 2 "OFF" 3 "Not Used" ;
VAL_ 1176 ICC_ASCMaintainModeReq 0 "Not Active" 1 "ON" 2 "OFF" 3 "Not Used" ;
VAL_ 1176 ICC_PABSetCmd 0 "Not Active" 1 "PAB OFF Cmd" 2 "PAB ON Cmd" 3 "Not Used" ;
VAL_ 1176 ICC_EPBSetCmd 0 "Not Active" 1 "Release" 2 "Apply" 3 "Reserved" ;
VAL_ 1176 ICC_ASUMemoryPosition 0 "Not Active" 1 "ON" 2 "OFF" 3 "Not Used" ;
VAL_ 1176 ICC_ASUEasyLoadingSet 0 "Not Active" 1 "ON" 2 "OFF" 3 "Not Used" ;
VAL_ 1176 Set_CSTFunctionSts 0 "Not active" 1 "CST ON" 2 "CST OFF" 3 "Reserved" ;
VAL_ 1176 ICC_ASURearaxlewithTaildoor 0 "Not Active" 1 "ON" 2 "OFF" 3 "Not Used" ;
VAL_ 1176 CST_SensitivityReq 0 "Not active" 1 "lowSensitivity" 2 "MiddleSensitivity" 3 "highSensitivity" ;
VAL_ 1176 TIHU_SetHDCOnOff 0 "Not Active" 1 "ON" 2 "OFF" 3 "Not Used" ;
VAL_ 1176 Set_ESPFunctionSts 0 "Not active" 1 "ON" 2 "OFF" 3 "Not Used" ;
VAL_ 1176 ICC_ASUPreviewCont 0 "Not Active" 1 "ON" 2 "OFF" 3 "Not Used" ;
VAL_ 1176 ICC_ASUHighwayModAdjust 0 "Not Active" 1 "ON" 2 "OFF" 3 "Not Used" ;
VAL_ 1176 ICC_ASUMapAdjust 0 "Not Active" 1 "ON" 2 "OFF" 3 "Not Used" ;
VAL_ 1239 ICC_DisChg 0 "Not Active" 1 "OFF" 2 "V2L ON" 3 "V2V ON" ;
VAL_ 1239 ICC_StpDisChgReq 0 "inactive" 1 "active" ;
VAL_ 1239 ICC_RegenLevel 0 "Not Active" 1 "off" 2 "low" 3 "high" ;
VAL_ 1239 ICC_ELockReq 0 "NoUnlockReq" 1 "UnlockReq" ;
VAL_ 1239 ICC_DisChgPercent 0 "Not Active" ;
VAL_ 1239 ICC_ChgSocSet 0 "Not Active" 254 "Abnormal" 255 "Invalid" ;
VAL_ 1239 ICC_CampMode 0 "Not Active" 1 "OFF" 2 "ON" 3 "Not Used" ;
VAL_ 1239 ICC_SftWarning 0 "Not Active" 1 "OFF" 2 "ON" 3 "Not Used" ;
VAL_ 1239 ICC_TowingMode 0 "Not Active" 1 "OFF" 2 "ON" 3 "Not Used" ;
VAL_ 1239 ICC_StopMode 0 "Not Active" 1 "Creep" 2 "Stop" 3 "Not Used" ;
VAL_ 1239 ICC_EPedalMode 0 "Not Active" 1 "ON" 2 "OFF" 3 "Not Used" ;
VAL_ 1246 ICC_WindowKeySts 0 "Not Active" 1 "On" 2 "Off" 3 "Not Used" ;
VAL_ 1246 ICC_FaceKeySts 0 "Not Active" 1 "On" 2 "Off" 3 "Not Used" ;
VAL_ 1246 ICC_FootKeySts 0 "Not Active" 1 "On" 2 "Off" 3 "Not Used" ;
VAL_ 1246 BltCallSts 0 "Not Active" 1 "On" 2 "Off" 3 "Not Used" ;
VAL_ 1246 ICC_DockWinspSts 0 "Not Active" 1 "On" 2 "Off" 3 "Not Used" ;
VAL_ 1246 ICC_DockTSts 0 "Not Active" 1 "On" 2 "Off" 3 "Not Used" ;
VAL_ 1246 ICC_ACFastCool 0 "Not Active" 1 "On" 2 "Off" 3 "Not Used" ;
VAL_ 1246 ICC_ACFastHeat 0 "Not Active" 1 "On" 2 "Off" 3 "Not Used" ;
VAL_ 1246 ICC_SetCLMOn 0 "Not Active" 1 "On" 2 "Off" 3 "Not Used" ;
VAL_ 1246 ICC_SetAutoKeySts 0 "Not Active" 1 "On" 2 "Off" 3 "Not Used" ;
VAL_ 1246 ICC_SetFrontDeforestSts 0 "Not Active" 1 "On" 2 "Off" 3 "Not used" ;
VAL_ 1246 ICC_SetCirculationModeKeySts 0 "Not Active" 1 "Recirculation mode" 2 "Air circulation mode" 3 "Two-Layer Flow Mode" ;
VAL_ 1246 ICC_ZoneSelectionKeySts 0 "Not Active" 1 "Single zone mode" 2 "Dual zone mode" 3 "Not Used" ;
VAL_ 1246 ICC_ResetFilter 0 "Not Active" 1 "On" 2 "Off" 3 "Not Used" ;
VAL_ 1246 ICC_AUTODefrostOnKeySts 0 "Not Active" 1 "On" 2 "Off" 3 "Not Used" ;
VAL_ 1246 ICC_AutoAirClean 0 "Not active" 1 "On" 2 "Off" 3 "Not Used" ;
VAL_ 1246 ICC_KeepWarm 0 "Not active" 1 "Open AC" 2 "Open NotAC" 3 "Closed" ;
VAL_ 1246 ICC_BlowSpeedLevelKeySts 0 "Not active" 1 "Level  1" 2 "Level  2" 3 "Level  3" 4 "Level  4" 5 "Level  5" 6 "Level  6" 7 "Level  7" 8 "Level  8" 9 "Level  9" 10 "Level 10" 11 "Reserved" 12 "Level__0" 13 "Reserved" 14 "Reserved" 15 "Reserved" ;
VAL_ 1246 ICC_SetACRequestKeySts 0 "Not Active" 1 "ON" 2 "OFF" 3 "Not used" 4 "Not used" ;
VAL_ 1246 ICC_DSwingSet 0 "Not_active" 1 "AllZone Swing" 2 "Single Swing" 3 "Mirro Swing" 4 "Free Swing" ;
VAL_ 1246 ICC_PSwingSet 0 "Not_active" 1 "AllZone Swing" 2 "Single Swing" 3 "Mirro Swing" 4 "Free Swing" ;
VAL_ 1246 ICC_AUTODefLevelSet 0 "Not Active" 1 "OFF" 2 "Low" 3 "Medium" 4 "High" ;
VAL_ 1246 ICC_SetTemperature_L_C 31 "Not active" ;
VAL_ 1246 ICC_SetTemperature_R_C 31 "Not active" ;
VAL_ 1246 ICC_NetWorkTemperature 254 "invalid" ;
VAL_ 1246 ICC_NetWorkHumidity 254 "invalid" ;
VAL_ 1246 ICC_DLOnOff 0 "Not Active" 1 "On" 2 "Off" 3 "Not Used" ;
VAL_ 1246 ICC_DROnOff 0 "Not Active" 1 "On" 2 "Off" 3 "Not Used" ;
VAL_ 1246 ICC_PLOnOff 0 "Not Active" 1 "On" 2 "Off" 3 "Not Used" ;
VAL_ 1246 ICC_PROnOff 0 "Not Active" 1 "On" 2 "Off" 3 "Not Used" ;
VAL_ 1246 ICC_DCOnOff 0 "Not Active" 1 "On" 2 "Off" 3 "Not Used" ;
VAL_ 1246 ICC_LoveRemind 0 "Not Active" 1 "On" 2 "Off" 3 "Not Used" ;
VAL_ 1246 ICC_InteCleanCar 0 "Not Active" 1 "On" 2 "Off" 3 "Not Used" ;
VAL_ 1246 ICC_KeepWarmMemory 0 "Not Active" 1 "Memory On" 2 "Memory Off" 3 "Not Used" ;
VAL_ 1250 ICC_AutoLightSW 0 "Not active" 1 "Active" ;
VAL_ 1250 ICC_CleanMode 0 "NotActive" 1 "OFF" 2 "ON" 3 "Reserved" ;
VAL_ 1250 ICC_1_OTASts 0 "Normal Status" 1 "OTA Status" 2 "Reserved" 3 "Reserved" ;
VAL_ 1250 ICC_1_OTAHV_Req 0 "Not active" 1 "HVON" 2 "HVOFF" 3 "Reserved" ;
VAL_ 1250 ICC_1_OTAPwrMngt 0 "No Request" 1 "Power Off" 2 "Power On" 3 "Continuous ON" 4 "Reserved" 5 "Reserved" 6 "Reserved" 7 "Reserved" ;
VAL_ 1250 ICC_DriveModeSwitch 0 "NotActive" 1 "ECO" 2 "NORMAL" 3 "SPORT" 4 "RainSNOW" 5 "MUD(Res)" 6 "Offroad" 7 "Individual" ;
VAL_ 1250 ICC_PropulsionMode 0 "Not Active" 1 "Comfortable" 2 "Normal" 3 "Sport" 4 "Snow" 5 "Off Road" ;
VAL_ 1250 ICC_SteeringMode 0 "Not Active" 1 "Normal" 2 "Sport" 3 "Light" ;
VAL_ 1250 ICC_SuspensionHeight 0 "Not Active" 1 "Very Low" 2 "Low" 3 "Normal" 4 "High" 5 "Very High" ;
VAL_ 1250 ICC_SuspensionDamping 0 "Not Active" 1 "Soft" 2 "Middle" 3 "Hard" ;
VAL_ 1250 ICC_AirconditionMode 0 "Not Active" 1 "ECO" 2 "Comfortable" 3 "Strong" ;
VAL_ 1250 ICC_BrakePedalFeelMode 0 "Not Active" 1 "Comfortable" 2 "Sport" 3 "Offroad" ;
VAL_ 1250 ICC_SentinelHV_Req 0 "Not active" 1 "HVON" 2 "HVOFF" 3 "Reserved" ;
VAL_ 1250 ICC_PetModeHV_Req 0 "Not Active" 1 "HVON" 2 "HVOFF" 3 "Reserved" ;
VAL_ 1250 ICC_SelfClearing 0 "Not active" 1 "Enable" ;
VAL_ 1254 ICC_WelcomeOpenSet 0 "Not Active" 1 "On" 2 "Off" 3 "Not Used" ;
VAL_ 1254 ICC_WALOpenSet 0 "Not Active" 1 "On" 2 "Off" 3 "Not Used" ;
VAL_ 1254 ICC_EasytrunkSet 0 "Not Active" 1 "On" 2 "Off" 3 "Not Used" ;
VAL_ 1254 ICC_UIROpenSet 0 "Not Active" 1 "On" 2 "Off" 3 "Not Used" ;
VAL_ 1254 ICC_BeanIDReq 0 "No action" 1 "Request" 2 "Clear data" 3 "Reserved" ;
VAL_ 1254 ICC_CWCWorkingStsSet 0 "Not active" 1 "OFF" 2 "ON" 3 "Invalid" ;
VAL_ 1254 ICC_CWCPhoneforgottenFunStsSet 0 "Not active" 1 "OFF" 2 "ON" 3 "Invalid" ;
VAL_ 1254 ICC_RCWCWorkingStsSet 0 "Not active" 1 "OFF" 2 "ON" 3 "Invalid" ;
VAL_ 1254 ICC_RCWCPhoneforgottenFunStsSet 0 "Not active" 1 "OFF" 2 "ON" 3 "Invalid" ;
VAL_ 1100 Set_AMPNaviVolume 0 "Not Active" 1 "0" 2 "1" 3 "2" 4 "3" 5 "4" 6 "5" 7 "6" 8 "7" 9 "8" 10 "9" 11 "10" 12 "Reserved" 13 "Reserved" 14 "Reserved" 15 "Reserved" ;
VAL_ 1100 Set_AMPVRVolume 0 "Not Active" 1 "0" 2 "1" 3 "2" 4 "3" 5 "4" 6 "5" 7 "6" 8 "7" 9 "8" 10 "9" 11 "10" 12 "Reserved" 13 "Reserved" 14 "Reserved" 15 "Reserved" ;
VAL_ 1100 Set_AMPKeyTone 0 "Not Active" 1 "ON" 2 "OFF" 3 "reserved" ;
VAL_ 1100 Set_AMPMediaVolume 0 "Not Active" 1 "0" 2 "1" 3 "2" 4 "3" 5 "4" 6 "5" 7 "6" 8 "7" 9 "8" 10 "9" 11 "10" 12 "11" 13 "12" 14 "13" 15 "14" 16 "15" 17 "16" 18 "17" 19 "18" 20 "19" 21 "20" 22 "21" 23 "22" 24 "23" 25 "24" 26 "25" 27 "26" 28 "27" 29 "28" 30 "29" 31 "30" 32 "31" 33 "Reserved" 34 "Reserved" 35 "Reserved" 36 "Reserved" 37 "Reserved" 38 "Reserved" 39 "Reserved" 40 "Reserved" 41 "Reserved" 42 "Reserved" 43 "Reserved" 44 "Reserved" 45 "Reserved" 46 "Reserved" 47 "Reserved" 48 "Reserved" 49 "Reserved" 50 "Reserved" 51 "Reserved" 52 "Reserved" 53 "Reserved" 54 "Reserved" 55 "Reserved" 56 "Reserved" 57 "Reserved" 58 "Reserved" 59 "Reserved" 60 "Reserved" 61 "Reserved" 62 "Reserved" 63 "Reserved" ;
VAL_ 1100 Set_AMPPhoneVolume 0 "Not Active" 1 "0" 2 "1" 3 "2" 4 "3" 5 "4" 6 "5" 7 "6" 8 "7" 9 "8" 10 "9" 11 "10" 12 "11" 13 "12" 14 "13" 15 "14" 16 "15" 17 "16" 18 "17" 19 "18" 20 "19" 21 "20" 22 "21" 23 "22" 24 "23" 25 "24" 26 "25" 27 "Reserved" 28 "Reserved" 29 "Reserved" 30 "Reserved" 31 "Reserved" ;
VAL_ 1100 Set_AMPSoundFocus 0 "Not Active" 1 "Customized" 2 "All" 3 "Driver" 4 "Sleep" 5 "VIP" 6 "Dolby7.1.4" 7 "Reserved" ;
VAL_ 1100 Set_AMPSoundEffect 0 "Not Active" 1 "Customer-defined mode" 2 "Standard mode" 3 "Popular mode" 4 "Jazz mode" 5 "Classic mode" 6 "Rock mode" 7 "Vocal mode" 8 "Reserved" 9 "Reserved" 10 "Reserved" 11 "Reserved" 12 "Reserved" 13 "Reserved" 14 "Reserved" 15 "Reserved" ;
VAL_ 1100 Set_AMPSoundEffectBass 0 "Not Active" 1 "-7" 2 "-6" 3 "-5" 4 "-4" 5 "-3" 6 "-2" 7 "-1" 8 "0" 9 "1" 10 "2" 11 "3" 12 "4" 13 "5" 14 "6" 15 "7" ;
VAL_ 1100 Set_AMPSoundEffectMidrange 0 "Not Active" 1 "-7" 2 "-6" 3 "-5" 4 "-4" 5 "-3" 6 "-2" 7 "-1" 8 "0" 9 "1" 10 "2" 11 "3" 12 "4" 13 "5" 14 "6" 15 "7" ;
VAL_ 1100 Set_AMPSoundEffectTreble 0 "Not Active" 1 "-7" 2 "-6" 3 "-5" 4 "-4" 5 "-3" 6 "-2" 7 "-1" 8 "0" 9 "1" 10 "2" 11 "3" 12 "4" 13 "5" 14 "6" 15 "7" ;
VAL_ 1100 Set_AMPSoundFieldBalance 0 "Not Active" 1 "-7" 2 "-6" 3 "-5" 4 "-4" 5 "-3" 6 "-2" 7 "-1" 8 "0" 9 "1" 10 "2" 11 "3" 12 "4" 13 "5" 14 "6" 15 "7" ;
VAL_ 1100 Set_AMPSoundFieldFader 0 "Not Active" 1 "-7" 2 "-6" 3 "-5" 4 "-4" 5 "-3" 6 "-2" 7 "-1" 8 "0" 9 "1" 10 "2" 11 "3" 12 "4" 13 "5" 14 "6" 15 "7" ;
VAL_ 1100 Set_Headrest_Mode 0 "Not Active" 1 "Share Mode" 2 "Enjoy Driving Mode" 3 "Enjoy Private Mode" ;
VAL_ 1100 Set_SurndFnOnOff 0 "Not Active" 1 "ON" 2 "OFF" 3 "Reserved" ;
VAL_ 1100 Set_VirtualSbwfrOnOff 0 "Not Active" 1 "VocalConcert" 2 "ConcertHall" 3 "OFF" ;
VAL_ 1119 Set_AMPMediaDuck 0 "Not Active" 1 "ON" 2 "OFF" 3 "Reserved" ;
VAL_ 1119 Set_AMPSpeedVolume 0 "Not Active" 1 "OFF" 2 "Low" 3 "Middle" 4 "High" 5 "Reserved" 6 "Reserved" 7 "Reserved" ;
VAL_ 1119 Set_AMPMute 0 "Not Active" 1 "ON" 2 "OFF" 3 "Reserved" ;
VAL_ 1119 REQ_AMPA2BMediaSound 0 "Not Active" 1 "Media" 2 "Background" 3 "OFF" ;
VAL_ 1119 REQ_AMPA2BNaviSound 0 "Not Active" 1 "ON" 2 "OFF" 3 "Reserved" ;
VAL_ 1119 REQ_AMPA2BVRSound 0 "Not Active" 1 "VR" 2 "Siri" 3 "OFF" ;
VAL_ 1119 REQ_AMPA2BTTSSound 0 "Not Active" 1 "ON" 2 "OFF" 3 "Reserved" ;
VAL_ 1119 REQ_AMPA2BKeyTone 0 "Not Active" 1 "ON" 2 "OFF" 3 "Reserved" ;
VAL_ 1119 Set_AMPRestoreDefaults 0 "Not Active" 1 "ON" 2 "OFF" 3 "Reserved" ;
VAL_ 1119 Set_AMPAlarmVolume 0 "Not Active" 1 "1" 2 "2" 3 "3" 4 "4" 5 "5" 6 "6" 7 "7" 8 "8" 9 "9" 10 "10" 11 "Reserved" 12 "Reserved" 13 "Reserved" 14 "Reserved" 15 "Reserved" ;
VAL_ 1119 REQ_AMPA2BPhoneSound 0 "Not Active" 1 "BT Phone Sound ON" 2 "Tbox Sound ON" 3 "OFF" ;
VAL_ 1119 Set_AMPSoundEffectMegaBass 0 "Not Active" 1 "-7" 2 "-6" 3 "-5" 4 "-4" 5 "-3" 6 "-2" 7 "-1" 8 "0" 9 "1" 10 "2" 11 "3" 12 "4" 13 "5" 14 "6" 15 "7" ;
VAL_ 1119 Set_AMPSoundEffectMidBass 0 "Not Active" 1 "-7" 2 "-6" 3 "-5" 4 "-4" 5 "-3" 6 "-2" 7 "-1" 8 "0" 9 "1" 10 "2" 11 "3" 12 "4" 13 "5" 14 "6" 15 "7" ;
VAL_ 1119 Set_AMPSoundEffectMidTreble 0 "Not Active" 1 "-7" 2 "-6" 3 "-5" 4 "-4" 5 "-3" 6 "-2" 7 "-1" 8 "0" 9 "1" 10 "2" 11 "3" 12 "4" 13 "5" 14 "6" 15 "7" ;
VAL_ 1119 Set_AMPBackgroundVolume 0 "Not Active" 1 "0" 2 "1" 3 "2" 4 "3" 5 "4" 6 "5" 7 "6" 8 "7" 9 "8" 10 "9" 11 "10" 12 "11" 13 "12" 14 "13" 15 "14" 16 "15" 17 "16" 18 "17" 19 "18" 20 "19" 21 "20" 22 "21" 23 "22" 24 "23" 25 "24" 26 "25" 27 "26" 28 "27" 29 "28" 30 "29" 31 "30" 32 "31" 33 "Reserved" 34 "Reserved" 35 "Reserved" 36 "Reserved" 37 "Reserved" 38 "Reserved" 39 "Reserved" 40 "Reserved" 41 "Reserved" 42 "Reserved" 43 "Reserved" 44 "Reserved" 45 "Reserved" 46 "Reserved" 47 "Reserved" 48 "Reserved" 49 "Reserved" 50 "Reserved" 51 "Reserved" 52 "Reserved" 53 "Reserved" 54 "Reserved" 55 "Reserved" 56 "Reserved" 57 "Reserved" 58 "Reserved" 59 "Reserved" 60 "Reserved" 61 "Reserved" 62 "Reserved" 63 "Reserved" ;
VAL_ 1119 Set_AMPSoundBypass 0 "Not Active" 1 "ON" 2 "OFF" 3 "Reserved" ;
VAL_ 1119 Set_AMPA2BConfig 0 "Not Active" 1 "Not OK" 2 "OK" 3 "Reserved" ;
VAL_ 1150 ICC_CPDDelaySwitchSet 0 "Not Active" 1 "ON" 2 "OFF" 3 "Not Used" ;
VAL_ 1150 ICC_PPMIDBSRBPASet 0 "Not Active" 1 "ON" 2 "OFF" 3 "Not Used" ;
VAL_ 1150 ICC_PPMIDHwSet 0 "Not Active" 1 "ON" 2 "OFF" 3 "Not Used" ;
VAL_ 1150 ICC_DriveDrosinessLevel 0 "not available" 1 "unknown" 2 "not fatigue" 3 "low fatigue" 4 "mid-fatigue" 5 "highly fatigue" 6 "Reserved" 7 "Reserved" ;
VAL_ 1150 ICC_FLDoorButton 0 "Init" 1 "Inactive" 2 "Active" 3 "Reserved" ;
VAL_ 1150 ICC_FRDoorButton 0 "Init" 1 "Inactive" 2 "Active" 3 "Reserved" ;
VAL_ 1150 ICC_RRDoorButton 0 "Init" 1 "Inactive" 2 "Active" 3 "Reserved" ;
VAL_ 1150 ICC_RLDoorButton 0 "Init" 1 "Inactive" 2 "Active" 3 "Reserved" ;
VAL_ 1150 ICC_CloseAllDoors 0 "Init" 1 "Inactive" 2 "Active" 3 "Reserved" ;
VAL_ 1150 ICC_DoorRemoteKeyControlEnable 0 "No Request" 1 "Enable" 2 "Disable" 3 "Reserved" ;
VAL_ 1150 ICC_SetOpenAngle 0 "No Request" 1 "50%" 2 "75%" 3 "100%" ;
VAL_ 1150 ICC_CPDSwitchSet 0 "Not Active" 1 "ON" 2 "OFF" 3 "Not Used" ;
VAL_ 1150 ICC_FrontDoorPowerMode 0 "No Request" 1 "PowerMode" 2 "ManualMode" 3 "SemiAutoMode" ;
VAL_ 1150 ICC_RearDoorPowerMode 0 "No Request" 1 "PowerMode" 2 "ManualMode" 3 "SemiAutoMode" ;
VAL_ 1150 ICC_PedalCloseDriverDoorEnable 0 "No Request" 1 "Enable" 2 "Disable" 3 "Reserved" ;
VAL_ 1150 RR_Door_RearScreen_Control 0 "No Request" 1 "Inactive" 2 "active" 3 "Reserved" ;
VAL_ 1150 ICC_RearDoorVoiceControlEnable 0 "No Request" 1 "Enable" 2 "Disable" 3 "Reserved" ;
VAL_ 1150 ICC_FLVoiceControl 0 "No Action" 1 "Door Close" 2 "Door Open" 3 "Reserved" ;
VAL_ 1150 ICC_FRVoiceControl 0 "No Action" 1 "Door Close" 2 "Door Open" 3 "Reserved" ;
VAL_ 1150 ICC_RRVoiceControl 0 "No Action" 1 "Door Close" 2 "Door Open" 3 "Reserved" ;
VAL_ 1150 ICC_RLVoiceControl 0 "No Action" 1 "Door Close" 2 "Door Open" 3 "Reserved" ;
VAL_ 1150 RL_Door_RearScreen_Control 0 "No Request" 1 "Inactive" 2 "active" 3 "Reserved" ;
VAL_ 917 ADBenable 0 "Notactive" 1 "enable" 2 "disenable" 3 "Reserved" ;
VAL_ 917 RandomMusicShowCMD 0 "Not active" 1 "Active" 2 "Reserved" 3 "Reserved" ;
VAL_ 917 DIYMusicShowmod 0 "Not active" 1 "waiting" 2 "mode1" 3 "mode2" ;
VAL_ 917 LiShowMod 0 "NotActive" 1 "OFF" 2 "Mode1" 3 "Mode2" 4 "Mode3" 5 "Mode4(Reserved)" 6 "Mode5(Reserved)" 7 "Reserved" ;
VAL_ 917 MusicLoudness_55HZ 0 "Level 1" 1 "Level 2" 2 "Level 3" 3 "Level 4" 4 "Level 5" 5 "Level 6" 6 "Level 7" 7 "Level 8" 8 "Level 9" 9 "Level 10" 10 "Level 11" 11 "Level 12" 12 "Level 13" 13 "Level 14" 14 "Level 15" 15 "Level 16" 16 "Reserved" 17 "Reserved" 18 "Reserved" 19 "Reserved" 20 "Reserved" 21 "Reserved" 22 "Reserved" 23 "Reserved" 24 "Reserved" 25 "Reserved" 26 "Reserved" 27 "Reserved" 28 "Reserved" 29 "Reserved" 30 "Reserved" 31 "Invalid" ;
VAL_ 917 MusicLoudness_123HZ 0 "Level 1" 1 "Level 2" 2 "Level 3" 3 "Level 4" 4 "Level 5" 5 "Level 6" 6 "Level 7" 7 "Level 8" 8 "Level 9" 9 "Level 10" 10 "Level 11" 11 "Level 12" 12 "Level 13" 13 "Level 14" 14 "Level 15" 15 "Level 16" 16 "Reserved" 17 "Reserved" 18 "Reserved" 19 "Reserved" 20 "Reserved" 21 "Reserved" 22 "Reserved" 23 "Reserved" 24 "Reserved" 25 "Reserved" 26 "Reserved" 27 "Reserved" 28 "Reserved" 29 "Reserved" 30 "Reserved" 31 "Invalid" ;
VAL_ 917 MusicLoudness_262HZ 0 "Level 1" 1 "Level 2" 2 "Level 3" 3 "Level 4" 4 "Level 5" 5 "Level 6" 6 "Level 7" 7 "Level 8" 8 "Level 9" 9 "Level 10" 10 "Level 11" 11 "Level 12" 12 "Level 13" 13 "Level 14" 14 "Level 15" 15 "Level 16" 16 "Reserved" 17 "Reserved" 18 "Reserved" 19 "Reserved" 20 "Reserved" 21 "Reserved" 22 "Reserved" 23 "Reserved" 24 "Reserved" 25 "Reserved" 26 "Reserved" 27 "Reserved" 28 "Reserved" 29 "Reserved" 30 "Reserved" 31 "Invalid" ;
VAL_ 917 MusicLoudness_440HZ 0 "Level 1" 1 "Level 2" 2 "Level 3" 3 "Level 4" 4 "Level 5" 5 "Level 6" 6 "Level 7" 7 "Level 8" 8 "Level 9" 9 "Level 10" 10 "Level 11" 11 "Level 12" 12 "Level 13" 13 "Level 14" 14 "Level 15" 15 "Level 16" 16 "Reserved" 17 "Reserved" 18 "Reserved" 19 "Reserved" 20 "Reserved" 21 "Reserved" 22 "Reserved" 23 "Reserved" 24 "Reserved" 25 "Reserved" 26 "Reserved" 27 "Reserved" 28 "Reserved" 29 "Reserved" 30 "Reserved" 31 "Invalid" ;
VAL_ 917 MusicLoudness_587HZ 0 "Level 1" 1 "Level 2" 2 "Level 3" 3 "Level 4" 4 "Level 5" 5 "Level 6" 6 "Level 7" 7 "Level 8" 8 "Level 9" 9 "Level 10" 10 "Level 11" 11 "Level 12" 12 "Level 13" 13 "Level 14" 14 "Level 15" 15 "Level 16" 16 "Reserved" 17 "Reserved" 18 "Reserved" 19 "Reserved" 20 "Reserved" 21 "Reserved" 22 "Reserved" 23 "Reserved" 24 "Reserved" 25 "Reserved" 26 "Reserved" 27 "Reserved" 28 "Reserved" 29 "Reserved" 30 "Reserved" 31 "Invalid" ;
VAL_ 917 MusicLoudness_784HZ 0 "Level 1" 1 "Level 2" 2 "Level 3" 3 "Level 4" 4 "Level 5" 5 "Level 6" 6 "Level 7" 7 "Level 8" 8 "Level 9" 9 "Level 10" 10 "Level 11" 11 "Level 12" 12 "Level 13" 13 "Level 14" 14 "Level 15" 15 "Level 16" 16 "Reserved" 17 "Reserved" 18 "Reserved" 19 "Reserved" 20 "Reserved" 21 "Reserved" 22 "Reserved" 23 "Reserved" 24 "Reserved" 25 "Reserved" 26 "Reserved" 27 "Reserved" 28 "Reserved" 29 "Reserved" 30 "Reserved" 31 "Invalid" ;
VAL_ 917 MusicLoudness_1318HZ 0 "Level 1" 1 "Level 2" 2 "Level 3" 3 "Level 4" 4 "Level 5" 5 "Level 6" 6 "Level 7" 7 "Level 8" 8 "Level 9" 9 "Level 10" 10 "Level 11" 11 "Level 12" 12 "Level 13" 13 "Level 14" 14 "Level 15" 15 "Level 16" 16 "Reserved" 17 "Reserved" 18 "Reserved" 19 "Reserved" 20 "Reserved" 21 "Reserved" 22 "Reserved" 23 "Reserved" 24 "Reserved" 25 "Reserved" 26 "Reserved" 27 "Reserved" 28 "Reserved" 29 "Reserved" 30 "Reserved" 31 "Invalid" ;
VAL_ 917 MusicLoudness_2794HZ 0 "Level 1" 1 "Level 2" 2 "Level 3" 3 "Level 4" 4 "Level 5" 5 "Level 6" 6 "Level 7" 7 "Level 8" 8 "Level 9" 9 "Level 10" 10 "Level 11" 11 "Level 12" 12 "Level 13" 13 "Level 14" 14 "Level 15" 15 "Level 16" 16 "Reserved" 17 "Reserved" 18 "Reserved" 19 "Reserved" 20 "Reserved" 21 "Reserved" 22 "Reserved" 23 "Reserved" 24 "Reserved" 25 "Reserved" 26 "Reserved" 27 "Reserved" 28 "Reserved" 29 "Reserved" 30 "Reserved" 31 "Invalid" ;
VAL_ 917 MusicLoudness_6272HZ 0 "Level 1" 1 "Level 2" 2 "Level 3" 3 "Level 4" 4 "Level 5" 5 "Level 6" 6 "Level 7" 7 "Level 8" 8 "Level 9" 9 "Level 10" 10 "Level 11" 11 "Level 12" 12 "Level 13" 13 "Level 14" 14 "Level 15" 15 "Level 16" 16 "Reserved" 17 "Reserved" 18 "Reserved" 19 "Reserved" 20 "Reserved" 21 "Reserved" 22 "Reserved" 23 "Reserved" 24 "Reserved" 25 "Reserved" 26 "Reserved" 27 "Reserved" 28 "Reserved" 29 "Reserved" 30 "Reserved" 31 "Invalid" ;
VAL_ 917 ISDShowCMD 0 "OFF" 1 "ON" ;
VAL_ 917 ISDShowMode 0 "Default value" 1 "BatteryCharging" 2 "Brand" 3 "TiresPressures" 4 "Weather" 5 "Greetings" 6 "Package" 7 "Panda" 8 "PredestrianCrossing" 9 "PingPong" 10 "Kite" 11 "Coffee" 12 "Reserved" 13 "Reserved" 14 "Reserved" 15 "Reserved" ;
VAL_ 1273 FaceID 0 "Not active" 1 "ID1" 2 "ID2" 3 "ID3" 4 "ID4" 5 "ID5" 6 "Not Used" 7 "Not Used" ;
VAL_ 1157 ICC_DA_15_BSDLCWSettingSt 0 "None" 1 "ON" 2 "OFF" 3 "Reserved" ;
VAL_ 1157 ICC_DA_15_DOWSettingSt 0 "None" 1 "ON" 2 "OFF" 3 "Reserved" ;
VAL_ 1157 ICC_DA_15_RCWSettingSt 0 "None" 1 "ON" 2 "OFF" 3 "Reserved" ;
VAL_ 1157 ICC_DA_15_RCTARCTBWarnType 0 "OFF" 1 "Warning" 2 "Warning and braking" 3 "None" ;
VAL_ 1157 ICC_DA_15_FCTAFCTBWarnType 0 "OFF" 1 "Warning" 2 "Warning and braking" 3 "None" ;
VAL_ 1157 ICC_DA_15_FrontPDCMuteSet 0 "OFF" 1 "ON" ;
VAL_ 1157 ICC_DA_15_FKPMuteSet 0 "OFF" 1 "ON" ;
VAL_ 1157 ICC_DA_15_ExtremeEnergySaveMode 0 "OFF" 1 "ON" ;
VAL_ 1157 Driver_EyeOnRoad 0 "Unavailable" 1 "Eyes on road" 2 "Eyes off road -- driving task related region" 3 "Eyes off road -- non-driving task related region" ;
VAL_ 1157 Dms_Status 0 "Init" 1 "off/standby" 2 "active" 3 "fault" 4 "camera blocked" ;
VAL_ 1157 Driver_AbnormalBehavior 0 "unknown" 1 "no abnormal behavior detected" 2 "abnormal behavior detected" 3 "Reserved" ;
VAL_ 1157 Driver_GazeRegion 0 "Unknown" 1 "Driver Side of Windscreen" 2 "Passenger Side of Windscreen" 3 "Left Rear View Mirror" 4 "Right Rear View Mirror" 5 "Left Side Window" 6 "Right Side Window" 7 "Central Rear View Mirror" 8 "Central driver's Instrument Cluster(speed gauge,etc.)" 9 "other" ;
VAL_ 1157 Dms_DriverPresence 0 "unknown" 1 "Not present" 2 "present" 3 "Reserved" ;
VAL_ 1157 ICC_IHCfunctionSw 0 "Not Active" 1 "ON" 2 "OFF" 3 "Reserved" ;
VAL_ 1279 Weather_Type 0 "Reserved" 1 "Sunny" 2 "Cloudy" 3 "Overcast" 4 "Shower" 5 "Thundershower" 6 "Thundershower with hail" 7 "Sleet" 8 "Light rain" 9 "Moderate rain" 10 "Heavy rain" 11 "Storm" 12 "Reserved(Heavy storm)" 13 "Reserved(Severe storm)" 14 "Reserved(Snow flurry)" 15 "Light snow" 16 "Moderate snow" 17 "Heavy snow" 18 "Snowstorm" 19 "Foggy" 20 "Reserved(Ice rain)" 21 "Duststorm" 22 "Reserved(Light to moderate rain)" 23 "Reserved(Moderate to heavy rain)" 24 "Reserved(Heavy rain to storm)" 25 "Reserved(Storm to heavy storm)" 26 "Reserved(Heavy to severe storm)" 27 "Reserved(Light to moderate snow)" 28 "Reserved(Moderate to heavy snow)" 29 "Reserve(Heavy snow to snowstorm)" 30 "Dust" 31 "Sand" 32 "Reserved(Sandstorm)" 33 "Haze" 34 "Reserved" 35 "Reserved" 36 "Reserved" 37 "Reserved" 38 "Reserved" 39 "Reserved" 40 "Reserved" 41 "Reserved" 42 "Reserved" 43 "Reserved" 44 "Reserved" 45 "Reserved" 46 "Reserved" 47 "Reserved" 48 "Reserved" 49 "Reserved" 50 "Reserved" 51 "Reserved" 52 "Reserved" 53 "Reserved" 54 "Reserved" 55 "Reserved" 56 "Reserved" 57 "Reserved" 58 "Reserved" 59 "Reserved" 60 "Reserved" 61 "Reserved" 62 "Reserved" 63 "Reserved" ;
VAL_ 1279 ICC_SentinelModeSts 0 "invalid" 1 "OFF" 2 "ON" 3 "Reserved" ;
VAL_ 1279 ICC_CameraErrorCode 0 "NoError" 1 "ErrorCode1" 2 "ErrorCode2" 3 "ErrorCode3" ;
VAL_ 1279 ICC_SentinelRequest 0 "Not Active" 1 "EnterSentinelRequest" 2 "ExitSentinelRequest" 3 "OFF" ;
VAL_ 1279 ICC_StartDeInitCameraStream 0 "Not Active" 1 "ICC_StartDeInitCameraStream" 2 "Reserved" 3 "Reserved" ;
VAL_ 1279 ICC_CameraRecoveryRequest 0 "Not Active" 1 "ICC_StartRecovery" 2 "Reserved" 3 "Reserved" ;
VAL_ 1279 ICC_CleanMode 0 "Not Active" 1 "OFF" 2 "ON" 3 "Reserved" ;
VAL_ 644 FuelShortGround 0 "Fail Not Present" 1 "Short Ground" ;
VAL_ 644 FuelShortPower 0 "Fail Not Present" 1 "Short Power" ;
VAL_ 644 FuelOutOfRange 0 "Fail Not Present" 1 "Out Of Range" ;
VAL_ 644 FuelValidData 0 "Valid" 1 "Not valid" ;
VAL_ 1174 IHU_SetSocManage 0 "Not Active" 1 "Pure electricity priority mode" 2 "Fuel priority mode" 3 "SOC hold mode" 4 "Reserved" 5 "Reserved" 6 "Reserved" 7 "Reserved" ;
VAL_ 1174 IHU_SetSOC 255 "Not Active" ;
VAL_ 1174 CTP_PowerModeSet 0 "Not Active" 1 "EV" 2 "HEV" 3 "EV+" ;
VAL_ 1174 LidOpenReq 0 "No request" 1 "Request" ;
VAL_ 1174 ICC_ForcedEVMode 0 "Not Active" 1 "On" 2 "Off" 3 "Reserved" ;
VAL_ 1174 ICC_EmissionMode 0 "Not Active" 1 "Active" ;
VAL_ 1174 ICC_ForcedEVChargeMode 0 "Not Active" 1 "On" 2 "Off" 3 "Reserved" ;
VAL_ 1174 EVOdometer_km_ValidData 0 "Valid" 1 "Not valid" ;
VAL_ 1174 ICC_SetChrgnFctMem 0 "Not active" 1 "Remember" 2 "No Remember" 3 "Reserved" ;
VAL_ 1276 PassSeatHeiAdjmt_Target 0 "Not active" 1 "0" 2 "10%" 3 "20%" 4 "30%" 5 "40%" 6 "50%" 7 "60%" 8 "70%" 9 "80%" 10 "90%" 11 "100%" ;
VAL_ 1276 SeatBackAndFwdAdjmt_Target 0 "Not active" 1 "0" 2 "10%" 3 "20%" 4 "30%" 5 "40%" 6 "50%" 7 "60%" 8 "70%" 9 "80%" 10 "90%" 11 "100%" ;
VAL_ 1276 SeatBackAgAdjmt_Target 0 "Not active" 1 "0" 2 "5%" 3 "10%" 4 "15%" 5 "20%" 6 "25%" 7 "30%" 8 "35%" 9 "40%" 10 "45%" 11 "50%" 12 "55%" 13 "60%" 14 "65%" 15 "70%" 16 "75%" 17 "80%" 18 "85%" 19 "90%" 20 "95%" 21 "100%" ;
VAL_ 1276 Set_ProfileID 0 "Not active" 1 "ID1" 2 "ID2" 3 "ID3" 4 "ID4" 5 "ID5" 6 "ID6" 7 "Ignore" ;
VAL_ 1276 SeatCushAgAdjmt_Target 0 "Not active" 1 "0" 2 "10%" 3 "20%" 4 "30%" 5 "40%" 6 "50%" 7 "60%" 8 "70%" 9 "80%" 10 "90%" 11 "100%" ;
VAL_ 1276 LgRstFwdAndBckAdjmt_Target 0 "Not active" 1 "0" 2 "10%" 3 "20%" 4 "30%" 5 "40%" 6 "50%" 7 "60%" 8 "70%" 9 "80%" 10 "90%" 11 "100%" ;
VAL_ 1276 FootRestAdjmt_Target 0 "Not active" 1 "0" 2 "10%" 3 "20%" 4 "30%" 5 "40%" 6 "50%" 7 "60%" 8 "70%" 9 "80%" 10 "90%" 11 "100%" ;
VAL_ 1276 REQ_SeatPosRecall 0 "No action" 1 "Recall seat_mode_1 of ID1" 2 "Recall seat_mode_2 of ID1" 3 "Recall seat_mode_3 of ID1" 4 "Recall seat_mode_1 of ID2" 5 "Recall seat_mode_2 of ID2" 6 "Recall seat_mode_3 of ID2" 7 "Recall seat_mode_1 of ID3" 8 "Recall seat_mode_2 of ID3" 9 "Recall seat_mode_3 of ID3" 10 "Recall seat_mode_1 of ID4" 11 "Recall seat_mode_2 of ID4" 12 "Recall seat_mode_3 of ID4" 13 "Recall seat_mode_1 of ID5" 14 "Recall seat_mode_2 of ID5" 15 "Recall seat_mode_3 of ID5" ;
VAL_ 1276 REQ_SeatPosStore 0 "No action" 1 "Store seat_mode_1 of ID1" 2 "Store seat_mode_2 of ID1" 3 "Store seat_mode_3 of ID1" 4 "Store seat_mode_1 of ID2" 5 "Store seat_mode_2 of ID2" 6 "Store seat_mode_3 of ID2" 7 "Store seat_mode_1 of ID3" 8 "Store seat_mode_2 of ID3" 9 "Store seat_mode_3 of ID3" 10 "Store seat_mode_1 of ID4" 11 "Store seat_mode_2 of ID4" 12 "Store seat_mode_3 of ID4" 13 "Store seat_mode_1 of ID5" 14 "Store seat_mode_2 of ID5" 15 "Store seat_mode_3 of ID5" ;
VAL_ 1276 Set_ToDefault 0 "No action" 1 "Set_Vehicle_to_default" 2 "Set_Personalization_to_default" 3 "Set_Telematics_to_default" 4 "Set_System_to_default" 5 "Set_All_to_default" 6 "Reserved" 7 "Ignore" ;
VAL_ 1276 Set_EasyEntryEnable 0 "No action" 1 "Enable" 2 "Disable" 3 "Ignore" ;
VAL_ 1276 REQ_SeatHeatPass 0 "Not Pressed" 1 "Seat heating level 1" 2 "Seat heating level 2" 3 "Seat heating level 3" ;
VAL_ 1276 REQ_SeatVentPass 0 "Not Pressed" 1 "Seat venting level 1" 2 "Seat venting level 2" 3 "Seat venting level 3" ;
VAL_ 1276 PassSeatMsgStr_LvlCmd 0 "NotActive" 1 "OFF" 2 "Low" 3 "Middle" 4 "High" ;
VAL_ 1276 PassSeatMsg_ModeCmd 0 "NotActive" 1 "PulseMode" 2 "WaveMode" 3 "CatPawMode" 4 "SigleRowMode" 5 "CrossMode" 6 "ButterflyMode" 7 "WaistMode" 8 "SnakeMode" 9 "Special 1" 10 "Special 2" 11 "Special 3" 12 "Special 4" ;
VAL_ 1059 ICC_FLSeatHeatLevelCmd 0 "Not Active" 1 "OFF" 2 "Seat heating Level1" 3 "Seat heating Level2" 4 "Seat heating Level3" 5 "Reserved" 6 "Reserved" 7 "Reserved" ;
VAL_ 1059 ICC_FRSeatHeatLevelCmd 0 "Not Active" 1 "OFF" 2 "Seat heating Level1" 3 "Seat heating Level2" 4 "Seat heating Level3" 5 "Reserved" 6 "Reserved" 7 "Reserved" ;
VAL_ 1059 ICC_TrunkSW 0 "Not Active" 1 "ON" 2 "OFF" 3 "Reserved" ;
VAL_ 1059 ICC_Set_PLGOperateSts 0 "Not active" ;
VAL_ 1059 ICC_RLSeatHeatLevelCmd 0 "Not active" 1 "OFF" 2 "Seat heating Level1" 3 "Seat heating Level2" 4 "Seat heating Level3" 5 "Reserved" 6 "Reserved" 7 "Reserved" ;
VAL_ 1059 ICC_RRSeatHeatLevelCmd 0 "Not active" 1 "OFF" 2 "Seat heating Level1" 3 "Seat heating Level2" 4 "Seat heating Level3" 5 "Reserved" 6 "Reserved" 7 "Reserved" ;
VAL_ 1059 ICC_FLSeatVentLevelCmd 0 "Not Active" 1 "OFF" 2 "Seat Ventilation Level1" 3 "Seat Ventilation Level2" 4 "Seat Ventilation Level3" 5 "Reserved" 6 "Reserved" 7 "Reserved" ;
VAL_ 1059 ICC_FRSeatVentLevelCmd 0 "Not Active" 1 "OFF" 2 "Seat Ventilation Level1" 3 "Seat Ventilation Level2" 4 "Seat Ventilation Level3" 5 "Reserved" 6 "Reserved" 7 "Reserved" ;
VAL_ 1059 ICC_RLSeatVentLevelCmd 0 "Not Active" 1 "OFF" 2 "Seat Ventilation Level1" 3 "Seat Ventilation Level2" 4 "Seat Ventilation Level3" 5 "Reserved" 6 "Reserved" 7 "Reserved" ;
VAL_ 1059 ICC_RRSeatVentLevelCmd 0 "Not Active" 1 "OFF" 2 "Seat Ventilation Level1" 3 "Seat Ventilation Level2" 4 "Seat Ventilation Level3" 5 "Reserved" 6 "Reserved" 7 "Reserved" ;
VAL_ 1059 ICC_FrontWiperMaintenanceMode 0 "Not Active" 1 "ON" 2 "OFF" 3 "Reserved" ;
VAL_ 1059 ICC_RearWiperMaintenanceMode 0 "Not Active" 1 "ON" 2 "OFF" 3 "Reserved" ;
VAL_ 1105 ICC_MultiplexSignalStatusSet 0 "Not Active" 1 "Mirror" 2 "EPS" 3 "HUD" 4 "OFF" 5 "Reserved" 6 "Reserved" 7 "invalid" ;
VAL_ 1056 ICC_DSBH_HeatReq 0 "NotActive" 1 "No Heat Request" 2 "Heat Request" 3 "Reserved" ;
VAL_ 1056 ICC_DSBH_SetTemp 0 "NotActive" ;
VAL_ 1056 ICC_PSBH_HeatReq 0 "NotActive" 1 "No Heat Request" 2 "Heat Request" 3 "Reserved" ;
VAL_ 1056 ICC_PSBH_SetTemp 0 "NotActive" ;
VAL_ 1112 PassSeatMsgStr_LvlCmd 0 "NotActive/Initial" 1 "OFF" 2 "Low" 3 "Middle" 4 "High" ;
VAL_ 1112 PassSeatMsg_ModeCmd 0 "NotActive" 1 "PulseMode" 2 "WaveMode" 3 "CatPawMode" 4 "SigleRowMode" 5 "CrossMode" 6 "ButterflyMode" 7 "WaistMode" 8 "SnakeMode" 9 "Special 1" 10 "Special 2" 11 "Special 3" 12 "Special 4" ;
VAL_ 1112 DriverSeatMsgStr_Lvlcmd 0 "NotActive/Initial" 1 "OFF" 2 "Low" 3 "Middle" 4 "High" ;
VAL_ 1112 DriverSeatMsg_ModeCmd 0 "NotActive" 1 "PulseMode" 2 "WaveMode" 3 "CatPawMode" 4 "SigleRowMode" 5 "CrossMode" 6 "ButterflyMode" 7 "WaistMode" 8 "SnakeMode" 9 "Special 1" 10 "Special 2" 11 "Special 3" 12 "Special 4" ;
VAL_ 1112 RightSeatMsgStr_LvlCmd 0 "NotActive/Initial" 1 "OFF" 2 "Low" 3 "Middle" 4 "High" ;
VAL_ 1112 RightSeatMsg_ModeCmd 0 "NotActive" 1 "PulseMode" 2 "WaveMode" 3 "CatPawMode" 4 "SigleRowMode" 5 "CrossMode" 6 "ButterflyMode" 7 "WaistMode" 8 "SnakeMode" 9 "Special 1" 10 "Special 2" 11 "Special 3" 12 "Special 4" ;
VAL_ 1112 LeftSeatMsgStr_LvlCmd 0 "NotActive/Initial" 1 "OFF" 2 "Low" 3 "Middle" 4 "High" ;
VAL_ 1112 LeftSeatMsg_ModeCmd 0 "NotActive" 1 "PulseMode" 2 "WaveMode" 3 "CatPawMode" 4 "SigleRowMode" 5 "CrossMode" 6 "ButterflyMode" 7 "WaistMode" 8 "SnakeMode" 9 "Special 1" 10 "Special 2" 11 "Special 3" 12 "Special 4" ;
VAL_ 1265 ICC_PwrOff 0 "No active" 1 "Active" ;
VAL_ 1265 ICC_EtmEgySave 0 "OFF" 1 "ON" ;
VAL_ 1265 ICC_HoodSW 0 "Not Active" 1 "ON" 2 "Reserved" 3 "Reserved" ;
VAL_ 1265 ICC_GloveboxSW 0 "Not Active" 1 "ON" 2 "Reserved" 3 "Reserved" ;
VAL_ 1265 ICC_ChrgPortCover_Switch 0 "Not Active" 1 "ON" 2 "OFF" 3 "Reserved" ;
VAL_ 1265 ICC_ReWinDefrstSwt 0 "Not Active" 1 "ON" 2 "OFF" 3 "Reserved" ;
VAL_ 1265 ICC_RearMirrorFoldCmd 0 "Not Active" 1 "Fold" 2 "Unfold" 3 "Reserved" ;
VAL_ 1265 ICC_CenterLockSwt 0 "Not Active" 1 "UNLOCK" 2 "LOCK" 3 "Reserved" ;
VAL_ 1265 ICC_ReverseExtMirrorSts 0 "Not active" 1 "OFF" 2 "Only right side" 3 "Only left side" 4 "Both sides" 5 "Not Used" 6 "Not Used" 7 "Not Used" ;
VAL_ 1265 ICC_LightMainSwitchSts 0 "Not active" 1 "Off" 2 "Auto" 3 "PositionLampSwitch" 4 "LowBeamSwitch" 5 "Reserved" 6 "Reserved" 7 "Reserved" ;
VAL_ 1265 ICC_AutoFoldSts 0 "Not active" 1 "Autofold mode" 2 "Not autofold mode" 3 "Not used" ;
VAL_ 1265 ICC_HeadlampHeightSts 0 "Not active" 1 "Level 0" 2 "Level 1" 3 "Level 2" 4 "Level 3" 5 "Not Used" 6 "Not Used" 7 "Not Used" ;
VAL_ 1265 ICC_WiprSnvty 0 "Not Active" 1 "Level1" 2 "Level2" 3 "Level3" 4 "Level4" 5 "Reserved" 6 "Reserved" ;
VAL_ 1265 ICC_WindowCmd 0 "Not active" 1 "FLWindow open" 2 "FLWindow close" 3 "FRWindow open" 4 "FRWindow close" 5 "RLWindow open" 6 "RLWindow close" 7 "RRWindow open" 8 "RRWindow close" 9 "Front Windows open" 10 "Front Windows close" 11 "Rear Windows open" 12 "Rear Windows close" 13 "All Windows open" 14 "All  Windows close" 15 "All  Windows comfort" 16 "Not used" 17 "Not used" 18 "Not used" 19 "Not used" 20 "Not used" 21 "Not used" 22 "Not used" 23 "Not used" 24 "Not used" 25 "Not used" 26 "Not used" 27 "Not used" 28 "Not used" 29 "Not used" 30 "Not used" 31 "Not used" ;
VAL_ 1265 ICC_LowBeamDelayOff 0 "Not Active" 1 "0s" 2 "10s" 3 "20s" 4 "30s" 5 "60s" 6 "Not Used" 7 "Not Used" ;
VAL_ 1265 ICC_FGHeatSts 0 "Not Active" 1 "ON" 2 "OFF" 3 "Reserved" ;
VAL_ 1265 ICC_AutolockSts 0 "Not active" 1 "Autolock mode" 2 "Not autolock mode" 3 "Not Used" ;
VAL_ 1265 ICC_WiperID 0 "Not Active" 1 "Front Wiper" 2 "Rear Wiper" 3 "Both Wiper" ;
VAL_ 1265 ICC_MaintenanceMode 0 "Not Active" 1 "Exit" 2 "Entrance" 3 "Reserved" ;
VAL_ 1265 ICC_lockSetSwitchSts 0 "Not Active" 1 "OFF" 2 "Only Lighting" 3 "Sound and Lighting" ;
VAL_ 1265 ICC_ChildLockSW 0 "Not Active" 1 "Window" 2 "ChildLock_RL" 3 "ChildLock_RR" ;
VAL_ 1265 ICC_ParkUnlockEnable 0 "Not Active" 1 "Disable" 2 "Enable" 3 "Reserved" ;
VAL_ 1265 ICC_BLEOpenDriverDoorEnable 0 "No Request" 1 "Enable" 2 "Disable" 3 "Reserved" ;
VAL_ 1265 ICC_WinInhbSwt 0 "Not Active" 1 "Inhibit" 2 "Permit" 3 "Reserved" ;
VAL_ 1265 ICC_SteerWhlHeatgSwt 0 "Not Active" 1 "Level1" 2 "Level2" 3 "Level3" 4 "OFF" ;
VAL_ 1265 ICC_AutoHeatingset 0 "Not Active" 1 "ON" 2 "OFF" 3 "Reserved" ;
VAL_ 1265 ICC_FrontFogSw 0 "Not Active" 1 "ON" 2 "OFF" 3 "Reserved" ;
VAL_ 1265 ICC_RearFogSw 0 "Not Active" 1 "ON" 2 "OFF" 3 "Reserved" ;
VAL_ 1265 ICC_DoorControlSW 0 "Not Active" 1 "ON" 2 "OFF" 3 "Reserved" ;
VAL_ 1265 ICC_LockCarWinCloseSw 0 "Not Active" 1 "ON" 2 "OFF" 3 "Reserved" ;
VAL_ 1265 ICC_RainCarWinCloseSw 0 "Not Active" 1 "ON" 2 "OFF" 3 "Reserved" ;
VAL_ 1265 ICC_EasyEntryExitSet 0 "Not Active" 1 "ON" 2 "OFF" 3 "Not Used" ;
VAL_ 1265 ICC_NapTimeSet 0 "Not Active" ;
VAL_ 1265 ICC_NapAreaSet 0 "Not Active" 1 "Front Left" 2 "Front Right" 3 "Front Left and Right" ;
VAL_ 1265 ICC_NapStatusSet 0 "Not Active" 1 "ON" 2 "OFF" 3 "Not Used" ;
VAL_ 1265 ICC_NapCFSStatusSet 0 "Not Active" 1 "On" 2 "Off" 3 "Not Used" ;
VAL_ 1265 ICC_NapSetTemperature 31 "Not active" ;
VAL_ 1265 ICC_SpoilerWelcomeFunSet 0 "Not Active" 1 "ON" 2 "OFF" 3 "Reserved" ;
VAL_ 1265 ICC_SpoilerCtrlCmd 0 "Not Active" 1 "Auto" 2 "Open Level1" 3 "Open Level2" 4 "Close" 5 "Reserved" 6 "Reserved" 7 "Reserved" ;
VAL_ 1265 ICC_HazardLightReq 0 "Not Active" 1 "ON" 2 "OFF" 3 "Not Used" ;
VAL_ 1265 ICC_MusicStatus 0 "Not Active" 1 "ON" 2 "OFF" 3 "Not Used" ;
VAL_ 1265 ICC_CinemaStatus 0 "Not Active" 1 "ON" 2 "OFF" 3 "Not Used" ;
VAL_ 1137 ICC_BookChrgSetReq 0 "default" 1 "BookSet" 2 "CancellBook" 3 "Reserved" ;
VAL_ 1137 ICC_BkChrgCycleType 0 "default" 1 "Once" 2 "EveryDay" 3 "WorkDay" 4 "Reserved" 5 "Reserved" ;
VAL_ 1137 ICC_StopChrgReq 0 "Not Active" 1 "Active" ;
VAL_ 1137 ICC_BkChrgCycleMon 0 "Not active" 1 "Active" ;
VAL_ 1137 ICC_BkChrgCycleTues 0 "Not active" 1 "Active" ;
VAL_ 1137 ICC_BkChrgCycleWen 0 "Not active" 1 "Active" ;
VAL_ 1137 ICC_BkChrgCycleThur 0 "Not active" 1 "Active" ;
VAL_ 1137 ICC_BkChrgCycleFri 0 "Not active" 1 "Active" ;
VAL_ 1137 ICC_BkChrgCycleSat 0 "Not active" 1 "Active" ;
VAL_ 1137 ICC_BkChrgCycleSun 0 "Not active" 1 "Active" ;
VAL_ 1137 ICC_PetmodeFb 0 "Not active" 1 "ON" 2 "OFF" 3 "Invalid" ;
VAL_ 1137 ICC_SentinelModeSwitchSts 0 "Not active" 1 "ON" 2 "OFF" 3 "Reserved" ;
VAL_ 1137 ICC_SentinelModeWorkingSts 0 "Not Active" 1 "Active" 2 "LowSOC" 3 "HVNotReady" 4 "HVFault" 5 "MirrorUnFold" 6 "CameraFault" 7 "LowBatVolt" ;
VAL_ 1137 ICC_SentinelModeFaultSts 0 "Not Warming" 1 "Artificial occlusion" 2 "Rain and snow cover" 3 "Reserved" ;
VAL_ 1137 ICC_SentinelModeAlarmSts 0 "Not Alarm" 1 "Level 1" 2 "Level 2" 3 "Level 3" ;
VAL_ 1137 ICC_SentinelModeExitReason 0 "Normal" 1 "LowSOC" 2 "HVNotReady" 3 "HVFault" 4 "MirrorUnFold" 5 "CameraFault" 6 "LowBatVolt" ;
VAL_ 1137 ICC_PetModeWarn 0 "Not Active" 1 "High Voltage Battery Low" 2 "TMS Abnormal" 3 "High Pressure Abnormal" 4 "Low Voltage Battery Low" 5 "High Voltage Battery Less Than 15%" 6 "High Voltage Battery Less Than 12%" 7 "Time Long Warning" ;
VAL_ 1137 ICC_TBOXPetmodeReq 0 "Not Active" 1 "ON" 2 "OFF" 3 "Reserved" ;
VAL_ 1137 ICC_PetModeWarn_2 0 "Not Active" 1 "High Voltage Battery Low" 2 "TMS Abnormal" 3 "High Pressure Abnormal" 4 "Low Voltage Battery Low" 5 "High Voltage Battery Less Than 15%" 6 "High Voltage Battery Less Than 12%" 7 "Time Long Warning" 8 "Vehicle charging" 9 "Vehicle Disarming" 10 "Gear is non-p" ;
VAL_ 1137 ICM_FuelLevelFailSts 0 "Fail_Not_Present" 1 "Fail_Present" ;
VAL_ 1137 ICM_Maintenance_tips 0 "Tip_Not_Present" 1 "Tip_Present" ;
VAL_ 1144 ICC_HvBattKeepWarmSet 0 "Not active" 1 "active" ;
VAL_ 1144 ICC_EnergyRegSet 0 "Not active" ;
VAL_ 1144 ICC_HvBattKeepWarmActiveReq 0 "Not active" 1 "StartWarm" 2 "EndWarm" 3 "Not Used" ;
VAL_ 1210 ICC_FLSeatHeiCmd 0 "Not active" 1 "Move Forwardwarde" 2 "Move Bacwardkwarde" 3 "Reserved" ;
VAL_ 1210 ICC_FLSeatLvlCmd 0 "Not active" 1 "Move Forwardwarde" 2 "Move Bacwardkwarde" 3 "Reserved" ;
VAL_ 1210 ICC_FLSeatBackAgCmd 0 "Not active" 1 "Move Forwardwarde" 2 "Move Bacwardkwarde" 3 "Reserved" ;
VAL_ 1210 ICC_FLSeatCushCmd 0 "Not active" 1 "Move Forwardwarde" 2 "Move Bacwardkwarde" 3 "Reserved" ;
VAL_ 1210 ICC_FLSeatLegSpprtCmd 0 "Not active" 1 "Move Forwardwarde" 2 "Move Bacwardkwarde" 3 "Reserved" ;
VAL_ 1210 ICC_FRSeatHeiCmd 0 "Not active" 1 "Move Forwardwarde" 2 "Move Bacwardkwarde" 3 "Reserved" ;
VAL_ 1210 ICC_FRSeatLvlCmd 0 "Not active" 1 "Move Forwardwarde" 2 "Move Bacwardkwarde" 3 "Reserved" ;
VAL_ 1210 ICC_FRSeatBackAgCmd 0 "Not active" 1 "Move Forwardwarde" 2 "Move Bacwardkwarde" 3 "Reserved" ;
VAL_ 1210 ICC_FRSeatLegSpprtCmd 0 "Not active" 1 "Move Forwardwarde" 2 "Move Bacwardkwarde" 3 "Reserved" ;
VAL_ 1210 ICC_MemoryRecoveryCmd 0 "Not Active" 1 "Save" 2 "Recover Manual" 3 "RecoverAuto" ;
VAL_ 1210 ICC_DeleteFaceID 0 "Not active" 1 "ID1" 2 "ID2" 3 "ID3" 4 "ID4" 5 "ID5" 6 "Not Used" 7 "Not Used" ;
VAL_ 1210 ICC_FLSeatHeitargetCmd 0 "Not active" ;
VAL_ 1210 ICC_FLSeatLvltargetCmd 0 "Not active" ;
VAL_ 1210 ICC_FLSeatBackAgtargetCmd 0 "Not active" ;
VAL_ 1210 ICC_FLSeatCushtargetCmd 0 "Not active" ;
VAL_ 1210 ICC_FLSeatLegSpprttargetCmd 0 "Not active" ;
VAL_ 1210 ICC_FRSeatHeitargetCmd 0 "Not active" ;
VAL_ 1210 ICC_FRSeatLvltargetCmd 0 "Not active" ;
VAL_ 1210 ICC_FRSeatBackAgtargetCmd 0 "Not active" ;
VAL_ 1210 ICC_FRSeatLegSpprttargetCmd 0 "Not active" ;
VAL_ 1210 ICC_NapFLSeatBackAgtargetSet 0 "Not active" ;
VAL_ 1210 ICC_NapFRSeatBackAgtargetSet 0 "Not active" ;
VAL_ 1210 ICC_NapFLSeatLvltargetSet 0 "Not active" ;
VAL_ 1210 ICC_NapFRSeatLvltargetSet 0 "Not active" ;
VAL_ 1210 ICC_FRSeatLegRestAngleCmd 0 "Not Active" 1 "Move Forwardwarde" 2 "Move Bacwardkwarde" 3 "Reserved" ;
VAL_ 1210 ICC_FRSeatLegRestAngletargetCmd 0 "Not active" ;
VAL_ 1210 ICC_FRSeatCushCmd 0 "Not Active" 1 "Move Forwardwarde" 2 "Move Bacwardkwarde" 3 "Reserved" ;
VAL_ 1210 ICC_FRSeatCushtargetCmd 0 "Not Active" ;
VAL_ 1210 ICC_FRZeroGravitySeatSw 0 "Not Active" 1 "OFF" 2 "ON" 3 "Reserved" ;
VAL_ 1210 ICC_HomeLinkArmHornSet 0 "Not Active" 1 "ON" 2 "OFF" 3 "Not Used" ;
VAL_ 1210 ICC_HomeLinkWelLightSet 0 "Not Active" 1 "ON" 2 "OFF" 3 "Not Used" ;
VAL_ 1210 ICC_HomeLinkPositionSts 0 "Not Active" 1 "At home" 2 "Not at home" 3 "Reserved" ;
VAL_ 1210 ICC_WelcomeOpenSetCmd 0 "Not Active" 1 "ON" 2 "OFF" 3 "Not Used" ;
VAL_ 1210 ICC_WALOpenSetCmd 0 "Not Active" 1 "ON" 2 "OFF" 3 "Not Used" ;
VAL_ 1210 ICC_UIROpenSetCmd 0 "Not Active" 1 "ON" 2 "OFF" 3 "Not Used" ;
VAL_ 1210 ICC_EnjoyableSeatSwitch 0 "Not Active" 1 "Entrence" 2 "Exit" 3 "Pause" ;
VAL_ 1210 ICC_BLTKeyPESet 0 "Not Active" 1 "ON" 2 "OFF" 3 "Not Used" ;
VAL_ 1210 ICC_FRMemoryDeleteCmd 0 "Not Active" 1 "Delete" 2 "Not Used" 3 "Not Used" ;
VAL_ 1210 ICC_FLSitPosnlocation 0 "Not Active" 1 "Location1" 2 "Location2" 3 "Location3" ;
VAL_ 1210 ICC_FRSitPosnlocation 0 "Not Active" 1 "Location1" 2 "Location2" 3 "Location3" ;
VAL_ 1210 ICC_FREasyEntryExitSet 0 "Not Active" 1 "ON" 2 "OFF" 3 "Not Used" ;
VAL_ 1210 ICC_FRMemoryRecoveryCmd 0 "Not Active" 1 "Save" 2 "Recover Manual" 3 "RecoverAuto" ;
VAL_ 1210 ICC_ConsoleAdjustSwitch 0 "Not Active" 1 "Lock" 2 "Unlock" 3 "Forward(Reserved)" 4 "Backward(Reserved)" 5 "Delpoy" 6 "Retract" 7 "Middle" 8 "Stop" ;
SIG_GROUP_ 1176 ICC_CH_3_0x498_E2E_P01_1 1 : Fusa_498_1 Fusa_498_2 Fusa_498_3 Fusa_498_4 Fusa_498_5 Fusa_498_6 ICC_CH_3_CRC ICC_CH_3_RollgCntr ICC_ASUAssistPassSet IHU_AutHldSet ICC_AutoEasyEntrySet ICC_ManualEasyOutSw ICC_ASCMaintainModeReq ICC_PABSetCmd ICC_EPBSetCmd ICC_ASUMemoryPosition ICC_ASUEasyLoadingSet Set_CSTFunctionSts ICC_ASURearaxlewithTaildoor CST_SensitivityReq TIHU_SetHDCOnOff Set_ESPFunctionSts ICC_ASUPreviewCont ICC_ASUHighwayModAdjust ICC_ASUMapAdjust;
SIG_GROUP_ 1150 ICC_BD_11_0x47E_E2E_P01_1 1 : Fusa_47E_1 Fusa_47E_2 Fusa_47E_3 ICC_BD_11_CRC ICC_BD_11_RollgCntr ICC_CPDDelaySwitchSet ICC_PPMIDBSRBPASet ICC_PPMIDHwSet ICC_DriveDrosinessLevel ICC_FLDoorButton ICC_FRDoorButton ICC_RRDoorButton ICC_RLDoorButton ICC_CloseAllDoors ICC_DoorRemoteKeyControlEnable ICC_SetOpenAngle ICC_CPDSwitchSet ICC_FrontDoorPowerMode ICC_RearDoorPowerMode ICC_PedalCloseDriverDoorEnable RR_Door_RearScreen_Control ICC_RearDoorVoiceControlEnable ICC_FLVoiceControl ICC_FRVoiceControl ICC_RRVoiceControl ICC_RLVoiceControl RL_Door_RearScreen_Control;
SIG_GROUP_ 1157 ICC_DA_15_0x485_E2E_P01_1 1 : Fusa_485_1 Fusa_485_2 ICC_DA_15_CRC ICC_DA_15_RollgCntr ICC_DA_15_Resd ICC_DA_15_BSDLCWSettingSt ICC_DA_15_DOWSettingSt ICC_DA_15_RCWSettingSt ICC_DA_15_RCTARCTBWarnType ICC_DA_15_FCTAFCTBWarnType ICC_DA_15_FrontPDCMuteSet ICC_DA_15_FKPMuteSet ICC_DA_15_ExtremeEnergySaveMode Driver_EyeOnRoad Dms_Status Driver_AbnormalBehavior Driver_GazeRegion Dms_DriverPresence ICC_IHCfunctionSw;
